VERSION "hnnbnnnynnnnnnnnnnnnnnnnnnnnnnnnnnnnnnnnnn/4/%%%/4/'%**4nnn///"

NS_ :

BS_:

BU_: BAP_Tester Fahrerdisplay_Kombi HUD ICAS1_X_Gateway ICAS3_Gateway ICC_IO_Node Kombi SmartLight_01 ZR_MIB_TOP_ab_Gen3

BO_ 512 Motor_53: 32 ICAS1_X_Gateway
	SG_ ISA_Tempolimit_Regelung : 196|6@1+ (1,0) [0|63] ""  ICAS3_Gateway
	SG_ MO_Antriebsstrang_Warnung_HS : 174|2@1+ (1,0) [0|3] ""  Vector__XXX
	SG_ MO_Anzeige_Betriebsmodus : 154|4@1+ (1,0) [0|15] ""  Vector__XXX
	SG_ MO_Anzeige_Fahrbereitschaft : 143|1@1+ (1,0) [0|1] ""  ICAS3_Gateway,Kombi
	SG_ MO_Anzeige_Rekuperation : 128|8@1+ (0.5,-0.5) [0|100] "PerCent"  Vector__XXX
	SG_ MO_Anzeige_Verbrauch_oE : 176|16@1+ (0.005,0) [0|327.675] "None"  Vector__XXX
	SG_ MO_Boost_aktiv : 153|1@1+ (1,0) [0|1] ""  Vector__XXX
	SG_ MO_Boost_verfuegbar : 144|8@1+ (0.4,-0.4) [0|100.4] "PerCent"  Vector__XXX
	SG_ MO_BZS_Charisma_FahrPr : 117|4@1+ (1,0) [0|15] ""  Vector__XXX
	SG_ MO_BZS_Charisma_Status : 121|2@1+ (1,0) [0|3] ""  Vector__XXX
	SG_ MO_Charisma_FahrPr : 105|4@1+ (1,0) [0|15] ""  Vector__XXX
	SG_ MO_Charisma_Status : 109|2@1+ (1,0) [0|3] ""  Vector__XXX
	SG_ MO_Drehzahlbeeinflussung : 80|8@1+ (0.39,0) [0|99.45] "PerCent"  Vector__XXX
	SG_ MO_Luftpfad_aktiv : 78|1@1+ (1,0) [0|1] ""  Vector__XXX
	SG_ MO_MAX_Wunschdrehzahl : 96|9@1+ (25,0) [0|12750] "MinutInver"  Vector__XXX
	SG_ MO_MIN_Wunschdrehzahl : 88|8@1+ (25,0) [0|6350] "MinutInver"  Vector__XXX
	SG_ MO_Motorlaufwarnung : 58|1@1+ (1,0) [0|1] ""  Vector__XXX
	SG_ MO_NGS_Position : 123|1@1+ (1,0) [0|1] ""  Vector__XXX
	SG_ MO_NGS_Status : 124|2@1+ (1,0) [0|3] ""  Vector__XXX
	SG_ MO_Overboost : 152|1@1+ (1,0) [0|1] ""  Vector__XXX
	SG_ MO_Prio_MAX_Wunschdrehzahl : 76|1@1+ (1,0) [0|1] ""  Vector__XXX
	SG_ MO_Prio_MIN_Wunschdrehzahl : 77|1@1+ (1,0) [0|1] ""  Vector__XXX
	SG_ MO_Rampenzeit_Generator_Anf : 72|4@1+ (1,0) [0|15] ""  Vector__XXX
	SG_ MO_Sperrung_FahrPr_BZS : 64|8@1+ (1,0) [0|255] ""  Vector__XXX
	SG_ MO_StSt_Charisma_FahrPr : 111|4@1+ (1,0) [0|15] ""  Vector__XXX
	SG_ MO_StSt_Charisma_Status : 115|2@1+ (1,0) [0|3] ""  Vector__XXX
	SG_ MO_Text_Aktivierung_Antrieb : 192|4@1+ (1,0) [0|15] ""  Kombi
	SG_ MO_v_Begrenz_Aktivierbar : 79|1@1+ (1,0) [0|1] ""  Vector__XXX
	SG_ MO_v_Begrenzung_Niveau : 126|2@1+ (1,0) [0|3] ""  Vector__XXX
	SG_ PEA_Abschalttexte : 166|2@1+ (1,0) [0|3] ""  Vector__XXX
	SG_ PEA_Ereignisanzeige : 160|5@1+ (1,0) [0|31] ""  Vector__XXX
	SG_ PEA_Ereignisanzeige_temporaer : 165|1@1+ (1,0) [0|1] ""  Vector__XXX
	SG_ PEA_Fahrerinfo : 202|4@1+ (1,0) [0|15] ""  Kombi
	SG_ PEA_Fortschrittsanzeige : 136|7@1+ (1,0) [0|100] "PerCent"  Vector__XXX
	SG_ PEA_Hinweis : 158|2@1+ (1,0) [0|3] ""  Vector__XXX
	SG_ PEA_Zielgeschw : 169|5@1+ (1,0) [0|31] ""  Vector__XXX
	SG_ PEA_Zielgeschw_Einheit : 168|1@1+ (1,0) [0|1] ""  Vector__XXX
	SG_ TSK_Akustik : 45|3@1+ (1,0) [0|7] ""  Kombi
	SG_ TSK_Fahrzeugstatus_GRA : 56|1@1+ (1,0) [0|1] ""  Kombi,ZR_MIB_TOP_ab_Gen3
	SG_ TSK_Fahrzeugstatus_Limiter : 57|1@1+ (1,0) [0|1] ""  Kombi,ZR_MIB_TOP_ab_Gen3
	SG_ TSK_Fahrzeugstatus_praed_Fkt : 31|3@1+ (1,0) [0|7] ""  Kombi,ZR_MIB_TOP_ab_Gen3
	SG_ TSK_Limiter_Anzeige : 55|1@1+ (1,0) [0|1] ""  Kombi,ZR_MIB_TOP_ab_Gen3
	SG_ TSK_Limiter_Fahrerinfo : 53|2@1+ (1,0) [0|3] ""  Kombi,ZR_MIB_TOP_ab_Gen3
	SG_ TSK_naechstes_Event : 25|6@1+ (1,0) [0|63] ""  Kombi,ZR_MIB_TOP_ab_Gen3
	SG_ TSK_naechstes_Event_Einheit : 60|1@1+ (1,0) [0|1] ""  Vector__XXX
	SG_ TSK_praed_Wunschgeschw : 246|10@1+ (0.32,0) [0|326.72] "KiloMeterPerHour"  Kombi,ZR_MIB_TOP_ab_Gen3
	SG_ TSK_praediktiver_Automode : 34|1@1+ (1,0) [0|1] ""  Vector__XXX
	SG_ TSK_praediktiver_Hinweis : 22|3@1+ (1,0) [0|7] ""  Kombi,ZR_MIB_TOP_ab_Gen3
	SG_ TSK_Status_Anzeige : 61|3@1+ (1,0) [0|7] ""  Kombi,ZR_MIB_TOP_ab_Gen3
	SG_ TSK_Texte : 40|5@1+ (1,0) [0|31] ""  Kombi
	SG_ TSK_Texte_Primaeranz : 48|5@1+ (1,0) [0|31] ""  Kombi,ZR_MIB_TOP_ab_Gen3
	SG_ TSK_Wunschgeschw : 12|10@1+ (0.32,0) [0|326.72] "KiloMeterPerHour"  Kombi,ZR_MIB_TOP_ab_Gen3

BO_ 332 Motor_54: 32 ICAS1_X_Gateway
	SG_ FoD_DTC_TSK_ACC : 35|1@1+ (1,0) [0|1] ""  Vector__XXX
	SG_ FoD_DTC_TSK_GRA : 15|1@1+ (1,0) [0|1] ""  Vector__XXX
	SG_ ISA_Regelung_aktiv : 27|1@1+ (1,0) [0|1] ""  ICAS3_Gateway,Kombi,ZR_MIB_TOP_ab_Gen3
	SG_ ISA_Status : 24|3@1+ (1,0) [0|7] ""  Kombi,ZR_MIB_TOP_ab_Gen3
	SG_ ISA_Tempolimitwarnung : 28|1@1+ (1,0) [0|1] ""  Kombi,ZR_MIB_TOP_ab_Gen3
	SG_ KVA_Ist_Pos : 121|7@1+ (1,0) [0|100] "PerCent"  Vector__XXX
	SG_ MO_Anforderung_Anzeige_Halten : 120|1@1+ (1,0) [0|1] ""  Vector__XXX
	SG_ MO_Anforderung_HMS : 12|3@1+ (1,0) [0|7] ""  Vector__XXX
	SG_ MO_EBoost_verf_praed : 90|2@1+ (1,0) [0|3] ""  Vector__XXX
	SG_ MO_eLaunch_verf : 93|2@1+ (1,0) [0|3] ""  Vector__XXX
	SG_ MO_Fahrbereitschaft : 76|2@1+ (1,0) [0|3] ""  Vector__XXX
	SG_ MO_Freilauf_Info : 78|2@1+ (1,0) [0|3] ""  Vector__XXX
	SG_ MO_Freilauf_Status : 87|3@1+ (1,0) [0|7] ""  Vector__XXX
	SG_ MO_Heckspoiler_Anf : 92|1@1+ (1,0) [0|1] ""  Vector__XXX
	SG_ MO_Klima_Regelmodus : 74|2@1+ (1,0) [0|3] ""  Vector__XXX
	SG_ MO_Krit_Heckobjekt : 81|3@1+ (1,0) [0|7] ""  Vector__XXX
	SG_ MO_LaunchControl : 101|1@1+ (1,0) [0|1] ""  Vector__XXX
	SG_ MO_NGS_Gangpos : 84|3@1+ (1,0) [0|7] ""  Vector__XXX
	SG_ MO_OnePedal_Verzoegerungsstufe : 117|3@1+ (1,0) [0|7] ""  Vector__XXX
	SG_ MO_Positionierung_aktiv : 95|1@1+ (1,0) [0|1] ""  Vector__XXX
	SG_ MO_QBit_Aussen_Temp : 185|1@1+ (1,0) [0|1] ""  Vector__XXX
	SG_ MO_Red_El_Fahrleistung : 29|3@1+ (1,0) [0|7] ""  Kombi
	SG_ MO_Servicemodus : 176|4@1+ (1,0) [0|15] ""  Vector__XXX
	SG_ MO_Startwunsch : 100|1@1+ (1,0) [0|1] ""  Vector__XXX
	SG_ MO_UBE_Reserve : 238|10@1+ (5,0) [0|5110] "WattHour"  Vector__XXX
	SG_ Motor_54_BZ : 8|4@1+ (1,0) [0|15] ""  Vector__XXX
	SG_ Motor_54_CRC : 0|8@1+ (1,0) [0|255] ""  Vector__XXX
	SG_ OBD_Abs_Load_Val : 152|16@1+ (0.392156862745,0) [0|25700] "PerCent"  Vector__XXX
	SG_ OBD_Abs_Pedal_Pos : 168|8@1+ (0.392156862745,0) [0|100] "PerCent"  Vector__XXX
	SG_ OBD_Abs_Throttle_Pos : 144|8@1+ (0.392156862745,0) [0|100] "PerCent"  Vector__XXX
	SG_ OBD_Aussen_Temp_gef : 248|8@1+ (1,-40) [-40|213] "DegreCelsi"  Vector__XXX
	SG_ OBD_Calc_Load_Val : 128|8@1+ (0.392156862745,0) [0|100] "PerCent"  Vector__XXX
	SG_ OBD_ClearMem_Inhibit : 183|1@1+ (1,0) [0|1] ""  Vector__XXX
	SG_ OBD_Driving_Cycle : 189|1@1+ (1,0) [0|1] ""  ICAS3_Gateway,ZR_MIB_TOP_ab_Gen3
	SG_ OBD_Eng_Cool_Temp : 136|8@1+ (1,-40) [-40|215] "DegreCelsi"  Vector__XXX
	SG_ OBD_Kaltstart_Denominator : 187|1@1+ (1,0) [0|1] ""  Vector__XXX
	SG_ OBD_Minimum_Trip : 188|1@1+ (1,0) [0|1] ""  Vector__XXX
	SG_ OBD_Normed_Trip : 191|1@1+ (1,0) [0|1] ""  Vector__XXX
	SG_ OBD_Sperrung_IUMPR : 186|1@1+ (1,0) [0|1] ""  Vector__XXX
	SG_ OBD_Sperrung_Kaltstart_Denom : 184|1@1+ (1,0) [0|1] ""  Vector__XXX
	SG_ OBD_Warm_Up_Cycle : 190|1@1+ (1,0) [0|1] ""  ICAS3_Gateway,ZR_MIB_TOP_ab_Gen3
	SG_ TSK_ACC_FoD_Status : 36|2@1+ (1,0) [0|3] ""  Vector__XXX
	SG_ TSK_aktives_System : 53|3@1+ (1,0) [0|7] ""  Vector__XXX
	SG_ TSK_Anf_Antriebsmoment : 57|1@1+ (1,0) [0|1] ""  Vector__XXX
	SG_ TSK_Einheit_vMax_Fahrerassistenz : 49|1@1+ (1,0) [0|1] ""  Vector__XXX
	SG_ TSK_erhoehter_Fahrwiderstand : 56|1@1+ (1,0) [0|1] ""  Vector__XXX
	SG_ TSK_GRA_FoD_Status : 38|2@1+ (1,0) [0|3] ""  ICAS3_Gateway
	SG_ TSK_Status_ARA : 58|3@1+ (1,0) [0|7] ""  Vector__XXX
	SG_ TSK_Status_EA : 32|3@1+ (1,0) [0|7] ""  Vector__XXX
	SG_ TSK_Status_IPA : 61|3@1+ (1,0) [0|7] ""  Vector__XXX
	SG_ TSK_Status_PLA : 50|3@1+ (1,0) [0|7] ""  Vector__XXX
	SG_ TSK_vMax_aktuell : 16|8@1+ (1,0) [0|253] "KiloMeterPerHour"  Kombi
	SG_ TSK_vMax_Fahrerassistenz : 40|9@1+ (1,0) [0|510] ""  Vector__XXX

BO_ 2463978666 Motor_57: 32 ICAS1_X_Gateway
	SG_ MO_Drehzahl_EM : 152|13@1+ (8,-32768) [-32768|32744] "RevPerMinute"  Vector__XXX
	SG_ MO_Drehzahl_EM_sek : 175|13@1+ (8,-32768) [-32768|32744] "RevPerMinute"  Vector__XXX
	SG_ MO_EM1_Generator_Leistung : 104|8@1+ (100,0) [0|25300] "Watt"  Vector__XXX
	SG_ MO_EM1_Max_Leistung_Gesamt : 45|13@1+ (200,-819000) [-819000|818800] "Watt"  Vector__XXX
	SG_ MO_EM1_Max_Spannung_Lim : 22|10@1+ (1,0) [0|1021] "Volt"  Vector__XXX
	SG_ MO_EM1_Min_Leistung_Gesamt : 32|13@1+ (200,-819000) [-819000|818800] "Watt"  Vector__XXX
	SG_ MO_EM1_Min_Spannung_Lim : 12|10@1+ (1,0) [0|1021] "Volt"  Vector__XXX
	SG_ MO_EM2_Generator_Leistung : 112|8@1+ (100,0) [0|25300] "Watt"  Vector__XXX
	SG_ MO_EM2_Max_Leistung_Gesamt : 71|13@1+ (200,-819000) [-819000|818800] "Watt"  Vector__XXX
	SG_ MO_EM2_Max_Spannung_Lim : 94|10@1+ (1,0) [0|1021] "Volt"  Vector__XXX
	SG_ MO_EM2_Min_Leistung_Gesamt : 58|13@1+ (200,-819000) [-819000|818800] "Watt"  Vector__XXX
	SG_ MO_EM2_Min_Spannung_Lim : 84|10@1+ (1,0) [0|1021] "Volt"  Vector__XXX
	SG_ MO_Rekuperation_EM_Ges_Ueberlauf : 151|1@1+ (1,0) [0|1] ""  Kombi
	SG_ MO_Rekuperation_Ges_EM : 136|15@1+ (10,0) [0|327670] "WattSecond"  Kombi
	SG_ MO_Uebersetzung_EM : 165|10@1+ (0.03125,0) [0.03125|31.90625] ""  Vector__XXX
	SG_ MO_Uebersetzung_EM_sek : 188|10@1+ (0.03125,0) [0.03125|31.90625] ""  Vector__XXX
	SG_ MO_Verbrauch_EM_Ges : 120|15@1+ (10,0) [0|327670] "WattSecond"  Kombi
	SG_ MO_Verbrauch_EM_Ges_Ueberlauf : 135|1@1+ (1,0) [0|1] ""  Kombi
	SG_ Motor_57_BZ : 8|4@1+ (1,0) [0|15] ""  Vector__XXX
	SG_ Motor_57_CRC : 0|8@1+ (1,0) [0|255] ""  Vector__XXX

BO_ 2331595982 Motor_64: 32 ICAS1_X_Gateway
	SG_ PTHyDrA_PrctUtilElDrv : 40|11@1+ (0.05,0) [0|102.25] "PerCent"  Vector__XXX
	SG_ PTHyDrA_StAcv : 36|2@1+ (1,0) [0|3] ""  Vector__XXX
	SG_ PTUIPwrm_FacPwrDyn : 73|7@1+ (0.01,0) [0|1.25] "None"  ICAS3_Gateway,Kombi
	SG_ PTUIPwrm_PrctBoostAvl : 91|10@1+ (0.1,0) [0|102.1] "PerCent"  Vector__XXX
	SG_ PTUIPwrm_PrctPeakPwrAvl : 131|11@1+ (0.05,0) [0|102.25] "PerCent"  ICAS3_Gateway
	SG_ PTUIPwrm_PrctPwrElBoostCur : 101|10@1+ (0.1,0) [0|102.1] "PerCent"  Vector__XXX
	SG_ PTUIPwrm_PrctPwrElBoostMaxUse : 111|10@1+ (0.1,0) [0|102.1] "PerCent"  Vector__XXX
	SG_ PTUIPwrm_PrctPwrElDrvCur : 24|12@1+ (0.05,-102.3) [-102.3|102.35] "PerCent"  Vector__XXX
	SG_ PTUIPwrm_PrctPwrGnrMaxUse : 51|11@1+ (0.05,-102.25) [-102.25|0] "PerCent"  ICAS3_Gateway,Kombi
	SG_ PTUIPwrm_PrctPwrMotElMaxUse : 62|11@1+ (0.05,0) [0|102.25] "PerCent"  Vector__XXX
	SG_ PTUIPwrm_PrctPwrMotMaxUse : 80|11@1+ (0.05,0) [0|102.25] "PerCent"  ICAS3_Gateway,Kombi
	SG_ PTUIPwrm_PrctPwrSysCur : 12|12@1+ (0.05,-102.3) [-102.3|102.35] "PerCent"  ICAS3_Gateway,Kombi
	SG_ PTUIPwrm_PwrElBoostNom : 121|10@1+ (1,0) [0|1021] "KiloWatt"  Vector__XXX
	SG_ PTUIPwrm_StAcv : 38|2@1+ (1,0) [0|3] ""  ICAS3_Gateway,Kombi

BO_ 2589283946 Motor_65: 32 ICAS1_X_Gateway
	SG_ PTUIPwrm_PwrGnrNom : 24|11@1+ (1,0) [0|2045] "KiloWatt"  ICAS3_Gateway,Kombi
	SG_ PTUIPwrm_PwrMotElNom : 12|11@1+ (1,0) [0|2045] "KiloWatt"  Vector__XXX
	SG_ PTUIPwrm_PwrSysMotNomDisp : 35|11@1+ (1,0) [0|2045] "KiloWatt"  ICAS3_Gateway,Kombi

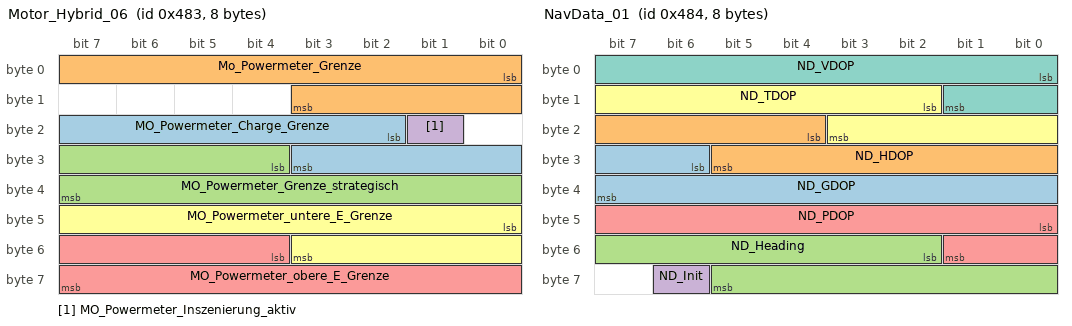
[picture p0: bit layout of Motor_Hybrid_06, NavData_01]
BO_ 1155 Motor_Hybrid_06: 8 ICAS1_X_Gateway
	SG_ MO_Powermeter_Charge_Grenze : 18|10@1+ (1,0) [0|1021] "None"  Kombi
	SG_ Mo_Powermeter_Grenze : 0|12@1+ (1,0) [0|4092] ""  Kombi
	SG_ MO_Powermeter_Grenze_strategisch : 28|12@1+ (1,0) [0|4093] "None"  Kombi
	SG_ MO_Powermeter_Inszenierung_aktiv : 17|1@1+ (1,0) [0|1] ""  Vector__XXX
	SG_ MO_Powermeter_obere_E_Grenze : 52|12@1+ (1,0) [0|4093] "None"  Vector__XXX
	SG_ MO_Powermeter_untere_E_Grenze : 40|12@1+ (1,0) [0|4093] "None"  Vector__XXX

BO_ 1156 NavData_01: 8 ZR_MIB_TOP_ab_Gen3
	SG_ ND_GDOP : 30|10@1+ (0.025,0) [0|25] ""  ICAS1_X_Gateway
	SG_ ND_HDOP : 20|10@1+ (0.025,0) [0|25] ""  ICAS1_X_Gateway
	SG_ ND_Heading : 50|12@1+ (0.1,0) [0|359.9] "DegreOfArc"  ICAS1_X_Gateway
	SG_ ND_Init : 62|1@1+ (1,0) [0|1] ""  ICAS1_X_Gateway
	SG_ ND_PDOP : 40|10@1+ (0.025,0) [0|25] ""  ICAS1_X_Gateway
	SG_ ND_TDOP : 10|10@1+ (0.025,0) [0|25] ""  ICAS1_X_Gateway
	SG_ ND_VDOP : 0|10@1+ (0.025,0) [0|25] ""  ICAS1_X_Gateway

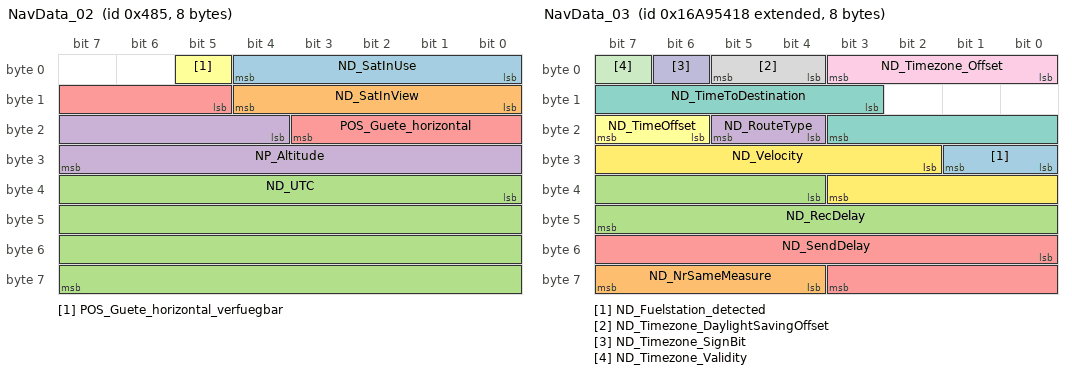
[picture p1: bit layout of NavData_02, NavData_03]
BO_ 1157 NavData_02: 8 ZR_MIB_TOP_ab_Gen3
	SG_ ND_SatInUse : 0|5@1+ (1,0) [0|29] ""  ICAS1_X_Gateway
	SG_ ND_SatInView : 8|5@1+ (1,0) [0|29] ""  ICAS1_X_Gateway
	SG_ ND_UTC : 32|32@1+ (1,0) [0|4294967293] "Secon"  ICAS1_X_Gateway
	SG_ NP_Altitude : 20|12@1+ (2,-500) [-500|7686] "Meter"  ICAS1_X_Gateway
	SG_ POS_Guete_horizontal : 13|7@1+ (2,0) [0|246] "Meter"  ICAS1_X_Gateway
	SG_ POS_Guete_horizontal_verfuegbar : 5|1@1+ (1,0) [0|1] ""  ICAS1_X_Gateway

BO_ 2527679512 NavData_03: 8 ZR_MIB_TOP_ab_Gen3
	SG_ ND_Fuelstation_detected : 24|2@1+ (1,0) [0|3] ""  Vector__XXX
	SG_ ND_NrSameMeasure : 60|4@1+ (1,0) [0|8] ""  Vector__XXX
	SG_ ND_RecDelay : 36|12@1+ (1,0) [0|4093] "MilliSecon"  Vector__XXX
	SG_ ND_RouteType : 20|2@1+ (1,0) [0|3] ""  Vector__XXX
	SG_ ND_SendDelay : 48|12@1+ (1,0) [0|4093] "MilliSecon"  Vector__XXX
	SG_ ND_TimeOffset : 22|2@1+ (1,0) [0|3] ""  Vector__XXX
	SG_ ND_TimeToDestination : 11|9@1+ (1,0) [0|509] "Minut"  Vector__XXX
	SG_ ND_Timezone_DaylightSavingOffset : 4|2@1+ (30,0) [0|60] "Minut"  Vector__XXX
	SG_ ND_Timezone_Offset : 0|4@1+ (1,0) [0|12] "Hours"  Vector__XXX
	SG_ ND_Timezone_SignBit : 6|1@1+ (1,0) [0|1] ""  Vector__XXX
	SG_ ND_Timezone_Validity : 7|1@1+ (1,0) [0|1] ""  Vector__XXX
	SG_ ND_Velocity : 26|10@1+ (0.1,0) [0|102.1] "MeterPerSecon"  Vector__XXX

BO_ 2527679665 NavData_04: 8 ICAS3_Gateway
	SG_ ND_Avrg_Speed_RangeData : 56|8@1+ (1,0) [0|253] "KiloMeterPerHour"  ICAS1_X_Gateway
	SG_ ND_PSD_Street_Category : 53|3@1+ (1,0) [0|7] ""  ICAS1_X_Gateway

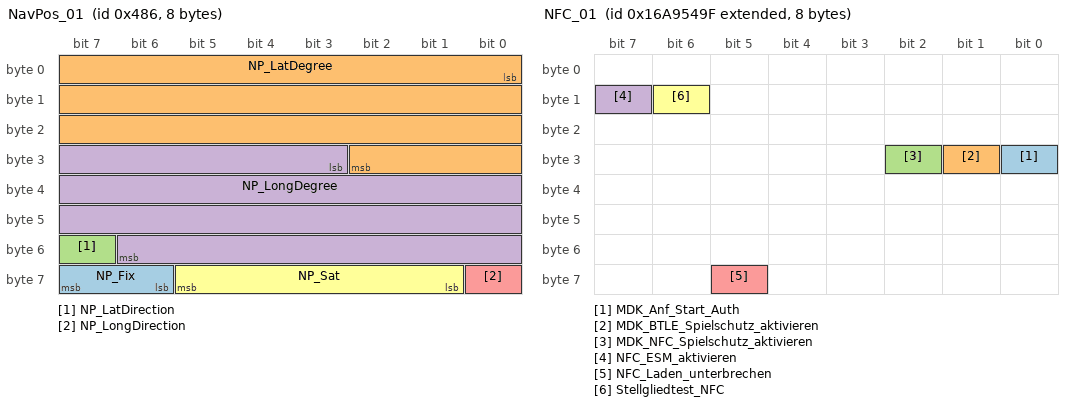
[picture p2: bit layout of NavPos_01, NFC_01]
BO_ 1158 NavPos_01: 8 ZR_MIB_TOP_ab_Gen3
	SG_ NP_Fix : 62|2@1+ (1,0) [0|3] ""  ICAS1_X_Gateway
	SG_ NP_LatDegree : 0|27@1+ (0.000001,0) [0|90] "DegreOfArc"  ICAS1_X_Gateway
	SG_ NP_LatDirection : 55|1@1+ (1,0) [0|1] ""  ICAS1_X_Gateway
	SG_ NP_LongDegree : 27|28@1+ (0.000001,0) [0|180] "DegreOfArc"  ICAS1_X_Gateway
	SG_ NP_LongDirection : 56|1@1+ (1,0) [0|1] ""  ICAS1_X_Gateway
	SG_ NP_Sat : 57|5@1+ (1,0) [0|29] ""  ICAS1_X_Gateway

BO_ 2589283496 NavPos_02_Map_Matched: 8 ZR_MIB_TOP_ab_Gen3
	SG_ POS_Heading m1 : 4|12@1+ (0.1,0) [0|409.5] "DegreOfArc"  ICAS1_X_Gateway
	SG_ POS_Heading_Trust m1 : 30|2@1+ (1,0) [0|3] ""  ICAS1_X_Gateway
	SG_ POS_Last_GPS_Sync m1 : 16|14@1+ (1,0) [0|16383] "Secon"  ICAS1_X_Gateway
	SG_ POS_LatDegree m0 : 8|27@1+ (0.000001,0) [0|90] "DegreOfArc"  ICAS1_X_Gateway
	SG_ POS_LatDirection m0 : 7|1@1+ (1,0) [0|1] ""  ICAS1_X_Gateway
	SG_ POS_LongDegree m0 : 36|28@1+ (0.000001,0) [0|180] "DegreOfArc"  ICAS1_X_Gateway
	SG_ POS_LongDirection m0 : 35|1@1+ (1,0) [0|1] ""  ICAS1_X_Gateway
	SG_ POS_MUX M : 0|2@1+ (1,0) [0|3] ""  ICAS1_X_Gateway
	SG_ POS_ODD_EVEN : 2|1@1+ (1,0) [0|1] ""  ICAS1_X_Gateway
	SG_ POS_PosStati m0 : 3|4@1+ (1,0) [0|15] ""  ICAS1_X_Gateway
	SG_ POS_UTC_REF m1 : 32|32@1+ (1,0) [0|4294967295] "Secon"  ICAS1_X_Gateway

BO_ 2527679647 NFC_01: 8 ICAS1_X_Gateway
	SG_ MDK_Anf_Start_Auth : 24|1@1+ (1,0) [0|1] ""  ICAS3_Gateway,ICC_IO_Node,ZR_MIB_TOP_ab_Gen3
	SG_ MDK_BTLE_Spielschutz_aktivieren : 25|1@1+ (1,0) [0|1] ""  ICAS3_Gateway,ICC_IO_Node,ZR_MIB_TOP_ab_Gen3
	SG_ MDK_NFC_Spielschutz_aktivieren : 26|1@1+ (1,0) [0|1] ""  ICAS3_Gateway,ICC_IO_Node,ZR_MIB_TOP_ab_Gen3
	SG_ NFC_ESM_aktivieren : 15|1@1+ (1,0) [0|1] ""  ICAS3_Gateway,ICC_IO_Node,ZR_MIB_TOP_ab_Gen3
	SG_ NFC_Laden_unterbrechen : 61|1@1+ (1,0) [0|1] ""  ICAS3_Gateway,ICC_IO_Node,ZR_MIB_TOP_ab_Gen3
	SG_ Stellgliedtest_NFC : 14|1@1+ (1,0) [0|1] ""  ICAS3_Gateway,ICC_IO_Node,ZR_MIB_TOP_ab_Gen3

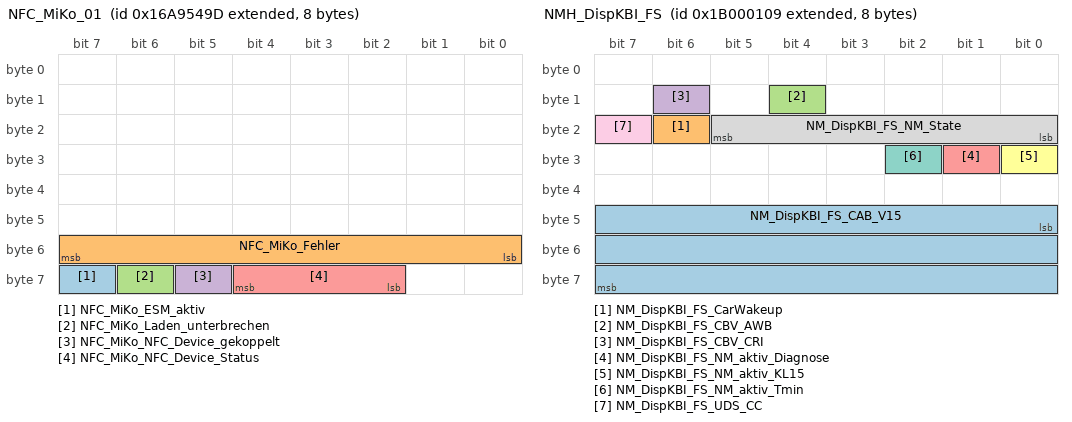
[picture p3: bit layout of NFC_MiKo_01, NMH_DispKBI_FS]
BO_ 2527679645 NFC_MiKo_01: 8 ICAS1_X_Gateway
	SG_ NFC_MiKo_ESM_aktiv : 63|1@1+ (1,0) [0|1] ""  ICAS3_Gateway,ICC_IO_Node,ZR_MIB_TOP_ab_Gen3
	SG_ NFC_MiKo_Fehler : 48|8@1+ (1,0) [0|255] ""  ICAS3_Gateway,ICC_IO_Node,ZR_MIB_TOP_ab_Gen3
	SG_ NFC_MiKo_Laden_unterbrechen : 62|1@1+ (1,0) [0|1] ""  ICAS3_Gateway,ICC_IO_Node,ZR_MIB_TOP_ab_Gen3
	SG_ NFC_MiKo_NFC_Device_gekoppelt : 61|1@1+ (1,0) [0|1] ""  ICAS3_Gateway,ICC_IO_Node,ZR_MIB_TOP_ab_Gen3
	SG_ NFC_MiKo_NFC_Device_Status : 58|3@1+ (1,0) [0|7] ""  ICAS3_Gateway,ICC_IO_Node,ZR_MIB_TOP_ab_Gen3

BO_ 2600468745 NMH_DispKBI_FS: 8 Fahrerdisplay_Kombi
	SG_ NM_DispKBI_FS_CAB_V15 : 40|24@1+ (1,0) [0|16777215] ""  ICAS1_X_Gateway
	SG_ NM_DispKBI_FS_CarWakeup : 22|1@1+ (1,0) [0|1] ""  ICAS1_X_Gateway
	SG_ NM_DispKBI_FS_CBV_AWB : 12|1@1+ (1,0) [0|1] ""  ICAS1_X_Gateway
	SG_ NM_DispKBI_FS_CBV_CRI : 14|1@1+ (1,0) [0|1] ""  ICAS1_X_Gateway
	SG_ NM_DispKBI_FS_NM_aktiv_Diagnose : 25|1@1+ (1,0) [0|1] ""  Vector__XXX
	SG_ NM_DispKBI_FS_NM_aktiv_KL15 : 24|1@1+ (1,0) [0|1] ""  Vector__XXX
	SG_ NM_DispKBI_FS_NM_aktiv_Tmin : 26|1@1+ (1,0) [0|1] ""  Vector__XXX
	SG_ NM_DispKBI_FS_NM_State : 16|6@1+ (1,0) [0|63] ""  HUD,ICAS3_Gateway,ICC_IO_Node,Kombi,SmartLight_01,ZR_MIB_TOP_ab_Gen3
	SG_ NM_DispKBI_FS_UDS_CC : 23|1@1+ (1,0) [0|1] ""  Vector__XXX

BO_ 2600468496 NMH_Gateway: 8 ICAS1_X_Gateway
	SG_ NM_Gateway_CAB_V15 : 40|24@1+ (1,0) [0|16777215] ""  Vector__XXX
	SG_ NM_Gateway_Car_Wakeup : 22|1@1+ (1,0) [0|1] ""  ICAS3_Gateway,ZR_MIB_TOP_ab_Gen3
	SG_ NM_Gateway_CBV_AWB : 12|1@1+ (1,0) [0|1] ""  Vector__XXX
	SG_ NM_Gateway_CBV_CRI : 14|1@1+ (1,0) [0|1] ""  Vector__XXX
	SG_ NM_Gateway_NM_aktiv_CAB : 32|1@1+ (1,0) [0|1] ""  Vector__XXX
	SG_ NM_Gateway_NM_aktiv_Diagnose : 25|1@1+ (1,0) [0|1] ""  Vector__XXX
	SG_ NM_Gateway_NM_aktiv_Energie : 28|1@1+ (1,0) [0|1] ""  Vector__XXX
	SG_ NM_Gateway_NM_aktiv_FoD : 39|1@1+ (1,0) [0|1] ""  Vector__XXX
	SG_ NM_Gateway_NM_aktiv_IAA_PSO : 31|1@1+ (1,0) [0|1] ""  Vector__XXX
	SG_ NM_Gateway_NM_aktiv_Kessy : 27|1@1+ (1,0) [0|1] ""  Vector__XXX
	SG_ NM_Gateway_NM_aktiv_KL15 : 24|1@1+ (1,0) [0|1] ""  Vector__XXX
	SG_ NM_Gateway_NM_aktiv_KS : 33|1@1+ (1,0) [0|1] ""  Vector__XXX
	SG_ NM_Gateway_NM_aktiv_Licht : 29|1@1+ (1,0) [0|1] ""  Vector__XXX
	SG_ NM_Gateway_NM_aktiv_PaCo : 34|1@1+ (1,0) [0|1] ""  Vector__XXX
	SG_ NM_Gateway_NM_aktiv_RTM : 37|1@1+ (1,0) [0|1] ""  Vector__XXX
	SG_ NM_Gateway_NM_aktiv_Standklima : 35|1@1+ (1,0) [0|1] ""  Vector__XXX
	SG_ NM_Gateway_NM_aktiv_Tmin : 26|1@1+ (1,0) [0|1] ""  Vector__XXX
	SG_ NM_Gateway_NM_aktiv_USS : 30|1@1+ (1,0) [0|1] ""  Vector__XXX
	SG_ NM_Gateway_NM_aktiv_ZM : 38|1@1+ (1,0) [0|1] ""  Vector__XXX
	SG_ NM_Gateway_NM_aktiv_ZV : 36|1@1+ (1,0) [0|1] ""  Vector__XXX
	SG_ NM_Gateway_NM_State : 16|6@1+ (1,0) [0|63] ""  Fahrerdisplay_Kombi,HUD,ICAS3_Gateway,ICC_IO_Node,Kombi,SmartLight_01,ZR_MIB_TOP_ab_Gen3
	SG_ NM_Gateway_UDS_CC : 23|1@1+ (1,0) [0|1] ""  Vector__XXX

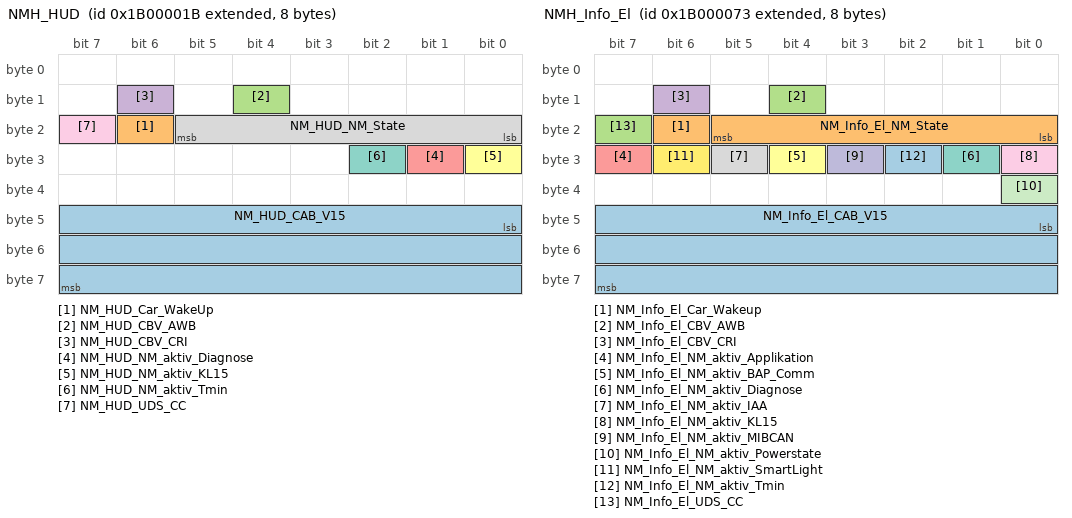
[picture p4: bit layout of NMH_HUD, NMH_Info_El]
BO_ 2600468507 NMH_HUD: 8 HUD
	SG_ NM_HUD_CAB_V15 : 40|24@1+ (1,0) [0|16777215] ""  ICAS1_X_Gateway
	SG_ NM_HUD_Car_WakeUp : 22|1@1+ (1,0) [0|1] ""  ICAS1_X_Gateway
	SG_ NM_HUD_CBV_AWB : 12|1@1+ (1,0) [0|1] ""  ICAS1_X_Gateway
	SG_ NM_HUD_CBV_CRI : 14|1@1+ (1,0) [0|1] ""  ICAS1_X_Gateway
	SG_ NM_HUD_NM_aktiv_Diagnose : 25|1@1+ (1,0) [0|1] ""  Vector__XXX
	SG_ NM_HUD_NM_aktiv_KL15 : 24|1@1+ (1,0) [0|1] ""  Vector__XXX
	SG_ NM_HUD_NM_aktiv_Tmin : 26|1@1+ (1,0) [0|1] ""  Vector__XXX
	SG_ NM_HUD_NM_State : 16|6@1+ (1,0) [0|63] ""  Fahrerdisplay_Kombi,ICAS3_Gateway,ICC_IO_Node,Kombi,SmartLight_01,ZR_MIB_TOP_ab_Gen3
	SG_ NM_HUD_UDS_CC : 23|1@1+ (1,0) [0|1] ""  Vector__XXX

BO_ 2600468595 NMH_Info_El: 8 ICAS3_Gateway
	SG_ NM_Info_El_CAB_V15 : 40|24@1+ (1,0) [0|16777215] ""  ICAS1_X_Gateway
	SG_ NM_Info_El_Car_Wakeup : 22|1@1+ (1,0) [0|1] ""  ICAS1_X_Gateway
	SG_ NM_Info_El_CBV_AWB : 12|1@1+ (1,0) [0|1] ""  ICAS1_X_Gateway
	SG_ NM_Info_El_CBV_CRI : 14|1@1+ (1,0) [0|1] ""  ICAS1_X_Gateway
	SG_ NM_Info_El_NM_aktiv_Applikation : 31|1@1+ (1,0) [0|1] ""  Vector__XXX
	SG_ NM_Info_El_NM_aktiv_BAP_Comm : 28|1@1+ (1,0) [0|1] ""  Vector__XXX
	SG_ NM_Info_El_NM_aktiv_Diagnose : 25|1@1+ (1,0) [0|1] ""  Vector__XXX
	SG_ NM_Info_El_NM_aktiv_IAA : 29|1@1+ (1,0) [0|1] ""  Vector__XXX
	SG_ NM_Info_El_NM_aktiv_KL15 : 24|1@1+ (1,0) [0|1] ""  Vector__XXX
	SG_ NM_Info_El_NM_aktiv_MIBCAN : 27|1@1+ (1,0) [0|1] ""  Vector__XXX
	SG_ NM_Info_El_NM_aktiv_Powerstate : 32|1@1+ (1,0) [0|1] ""  Vector__XXX
	SG_ NM_Info_El_NM_aktiv_SmartLight : 30|1@1+ (1,0) [0|1] ""  Vector__XXX
	SG_ NM_Info_El_NM_aktiv_Tmin : 26|1@1+ (1,0) [0|1] ""  Vector__XXX
	SG_ NM_Info_El_NM_State : 16|6@1+ (1,0) [0|63] ""  Fahrerdisplay_Kombi,HUD,Kombi,SmartLight_01
	SG_ NM_Info_El_UDS_CC : 23|1@1+ (1,0) [0|1] ""  Vector__XXX

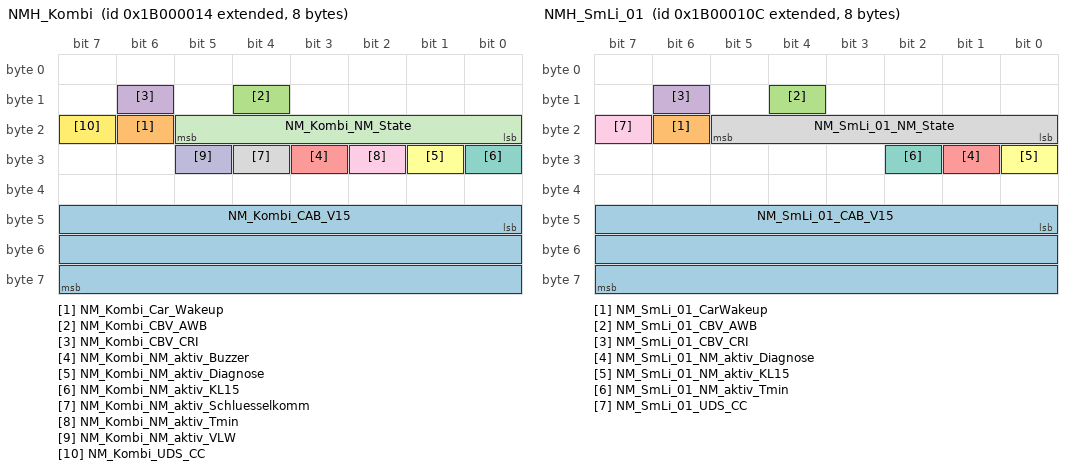
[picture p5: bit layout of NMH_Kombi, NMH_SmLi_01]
BO_ 2600468500 NMH_Kombi: 8 Kombi
	SG_ NM_Kombi_CAB_V15 : 40|24@1+ (1,0) [0|16777215] ""  ICAS1_X_Gateway
	SG_ NM_Kombi_Car_Wakeup : 22|1@1+ (1,0) [0|1] ""  ICAS1_X_Gateway
	SG_ NM_Kombi_CBV_AWB : 12|1@1+ (1,0) [0|1] ""  ICAS1_X_Gateway
	SG_ NM_Kombi_CBV_CRI : 14|1@1+ (1,0) [0|1] ""  ICAS1_X_Gateway
	SG_ NM_Kombi_NM_aktiv_Buzzer : 27|1@1+ (1,0) [0|1] ""  Vector__XXX
	SG_ NM_Kombi_NM_aktiv_Diagnose : 25|1@1+ (1,0) [0|1] ""  Vector__XXX
	SG_ NM_Kombi_NM_aktiv_KL15 : 24|1@1+ (1,0) [0|1] ""  Vector__XXX
	SG_ NM_Kombi_NM_aktiv_Schluesselkomm : 28|1@1+ (1,0) [0|1] ""  Vector__XXX
	SG_ NM_Kombi_NM_aktiv_Tmin : 26|1@1+ (1,0) [0|1] ""  Vector__XXX
	SG_ NM_Kombi_NM_aktiv_VLW : 29|1@1+ (1,0) [0|1] ""  Vector__XXX
	SG_ NM_Kombi_NM_State : 16|6@1+ (1,0) [0|63] ""  Fahrerdisplay_Kombi,HUD,ICAS3_Gateway,ICC_IO_Node,SmartLight_01,ZR_MIB_TOP_ab_Gen3
	SG_ NM_Kombi_UDS_CC : 23|1@1+ (1,0) [0|1] ""  Vector__XXX

BO_ 2600468748 NMH_SmLi_01: 8 SmartLight_01
	SG_ NM_SmLi_01_CAB_V15 : 40|24@1+ (1,0) [0|16777215] ""  ICAS1_X_Gateway
	SG_ NM_SmLi_01_CarWakeup : 22|1@1+ (1,0) [0|1] ""  ICAS1_X_Gateway
	SG_ NM_SmLi_01_CBV_AWB : 12|1@1+ (1,0) [0|1] ""  ICAS1_X_Gateway
	SG_ NM_SmLi_01_CBV_CRI : 14|1@1+ (1,0) [0|1] ""  ICAS1_X_Gateway
	SG_ NM_SmLi_01_NM_aktiv_Diagnose : 25|1@1+ (1,0) [0|1] ""  Vector__XXX
	SG_ NM_SmLi_01_NM_aktiv_KL15 : 24|1@1+ (1,0) [0|1] ""  Vector__XXX
	SG_ NM_SmLi_01_NM_aktiv_Tmin : 26|1@1+ (1,0) [0|1] ""  Vector__XXX
	SG_ NM_SmLi_01_NM_State : 16|6@1+ (1,0) [0|63] ""  Fahrerdisplay_Kombi,HUD,ICAS3_Gateway,ICC_IO_Node,Kombi,ZR_MIB_TOP_ab_Gen3
	SG_ NM_SmLi_01_UDS_CC : 23|1@1+ (1,0) [0|1] ""  Vector__XXX

BO_ 2621702665 OBDC_DispKBI_FS_Req_FD: 64 ICAS1_X_Gateway
	SG_ OBDC_DispKBI_FS_Req_FD_Data : 0|512@1+ (1,0) [0|13407807929942597099574024998205846127479365820592393377723561443721764030073546976801874298166903427690031858186486050853753882811946569946433649006084096] ""  Fahrerdisplay_Kombi

BO_ 2621833737 OBDC_DispKBI_FS_Resp_FD: 64 Fahrerdisplay_Kombi
	SG_ OBDC_DispKBI_FS_Resp_FD_Data : 0|512@1+ (1,0) [0|13407807929942597099574024998205846127479365820592393377723561443721764030073546976801874298166903427690031858186486050853753882811946569946433649006084096] ""  ICAS1_X_Gateway

BO_ 2549940736 OBDC_Funktionaler_Req_All: 8 ICAS1_X_Gateway
	SG_ OBDC_Funktionaler_Req_All_Data : 0|64@1+ (1,0) [0|18446744073709551616] ""  ICAS3_Gateway,ICC_IO_Node,ZR_MIB_TOP_ab_Gen3

BO_ 2621506048 OBDC_Funktionaler_Req_All_FD: 64 ICAS1_X_Gateway
	SG_ OBDC_Funktion_Req_All_FD_Data : 0|512@1+ (1,0) [0|13407807929942597099574024998205846127479365820592393377723561443721764030073546976801874298166903427690031858186486050853753882811946569946433649006084096] ""  Fahrerdisplay_Kombi,HUD,Kombi,SmartLight_01

BO_ 2621440539 OBDC_HUD_Req_FD: 64 ICAS1_X_Gateway
	SG_ OBDC_HUD_Req_FD_Data : 0|512@1+ (1,0) [0|13407807929942597099574024998205846127479365820592393377723561443721764030073546976801874298166903427690031858186486050853753882811946569946433649006084096] ""  HUD

BO_ 2621571611 OBDC_HUD_Resp_FD: 64 HUD
	SG_ OBDC_HUD_Resp_FD_Data : 0|512@1+ (1,0) [0|13407807929942597099574024998205846127479365820592393377723561443721764030073546976801874298166903427690031858186486050853753882811946569946433649006084096] ""  ICAS1_X_Gateway

BO_ 2621440532 OBDC_Kombi_Req_FD: 64 ICAS1_X_Gateway
	SG_ OBDC_Kombi_Req_FD_Data : 0|512@1+ (1,0) [0|13407807929942597099574024998205846127479365820592393377723561443721764030073546976801874298166903427690031858186486050853753882811946569946433649006084096] ""  Kombi

BO_ 2621571604 OBDC_Kombi_Resp_FD: 64 Kombi
	SG_ OBDC_Kombi_Resp_FD_Data : 0|512@1+ (1,0) [0|13407807929942597099574024998205846127479365820592393377723561443721764030073546976801874298166903427690031858186486050853753882811946569946433649006084096] ""  ICAS1_X_Gateway

BO_ 2621702668 OBDC_SmLi_01_Req_FD: 64 ICAS1_X_Gateway
	SG_ OBDC_SmLi_01_Req_FD_Data : 0|512@1+ (1,0) [0|13407807929942597099574024998205846127479365820592393377723561443721764030073546976801874298166903427690031858186486050853753882811946569946433649006084096] ""  SmartLight_01

BO_ 2621833740 OBDC_SmLi_01_Resp_FD: 64 SmartLight_01
	SG_ OBDC_SmLi_01_Resp_FD_Data : 0|512@1+ (1,0) [0|13407807929942597099574024998205846127479365820592393377723561443721764030073546976801874298166903427690031858186486050853753882811946569946433649006084096] ""  ICAS1_X_Gateway

BO_ 2549903374 OBDC_SSN_ABT_1_Req: 8 ICAS1_X_Gateway
	SG_ OBDC_SSN_ABT_1_Req_Data : 0|64@1+ (1,0) [0|18446744073709551616] ""  ICAS3_Gateway,ICC_IO_Node,ZR_MIB_TOP_ab_Gen3

BO_ 2550034446 OBDC_SSN_ABT_1_Resp: 8 ICAS3_Gateway
	SG_ OBDC_SSN_ABT_1_Resp_Data : 0|64@1+ (1,0) [0|18446744073709551616] ""  ICAS1_X_Gateway

BO_ 2549875309 OBDC_TV_Tuner_Req: 8 ICAS1_X_Gateway
	SG_ OBDC_TV_Tuner_Req_Data : 0|64@1+ (1,0) [0|18446744073709551616] ""  ZR_MIB_TOP_ab_Gen3

BO_ 2550006381 OBDC_TV_Tuner_Resp: 8 ZR_MIB_TOP_ab_Gen3
	SG_ OBDC_TV_Tuner_Resp_Data : 0|64@1+ (1,0) [0|18446744073709551616] ""  ICAS1_X_Gateway

BO_ 2549875365 OBDC_WLC1_Req: 8 ICAS1_X_Gateway
	SG_ OBDC_WLC1_Req_Data : 0|64@1+ (1,0) [0|18446744073709551616] "None"  ICAS3_Gateway,ICC_IO_Node,ZR_MIB_TOP_ab_Gen3

BO_ 2550006437 OBDC_WLC1_Resp: 8 ICAS3_Gateway
	SG_ OBDC_WLC1_Resp_Data : 0|64@1+ (1,0) [0|18446744073709551616] "None"  ICAS1_X_Gateway

BO_ 2564502513 OBDx_allOBD_Req: 8 ICAS1_X_Gateway
	SG_ OBDx_allOBD_Req_Data : 0|64@1+ (1,0) [0|18446744073709551616] ""  Vector__XXX

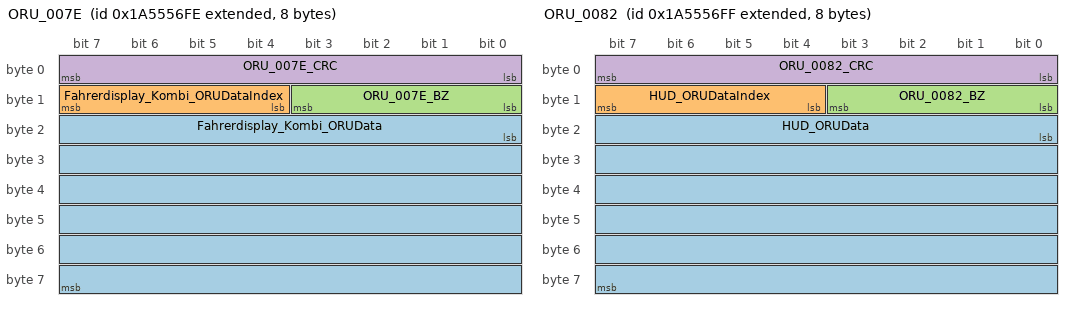
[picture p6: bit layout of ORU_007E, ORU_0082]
BO_ 2589284094 ORU_007E: 8 Fahrerdisplay_Kombi
	SG_ Fahrerdisplay_Kombi_ORUData : 16|48@1+ (1,0) [0|281474976710655] ""  ICAS1_X_Gateway
	SG_ Fahrerdisplay_Kombi_ORUDataIndex : 12|4@1+ (1,0) [0|15] ""  ICAS1_X_Gateway
	SG_ ORU_007E_BZ : 8|4@1+ (1,0) [0|15] ""  ICAS1_X_Gateway
	SG_ ORU_007E_CRC : 0|8@1+ (1,0) [0|255] ""  ICAS1_X_Gateway

BO_ 2589284095 ORU_0082: 8 HUD
	SG_ HUD_ORUData : 16|48@1+ (1,0) [0|281474976710655] ""  ICAS1_X_Gateway
	SG_ HUD_ORUDataIndex : 12|4@1+ (1,0) [0|15] ""  ICAS1_X_Gateway
	SG_ ORU_0082_BZ : 8|4@1+ (1,0) [0|15] ""  ICAS1_X_Gateway
	SG_ ORU_0082_CRC : 0|8@1+ (1,0) [0|255] ""  ICAS1_X_Gateway

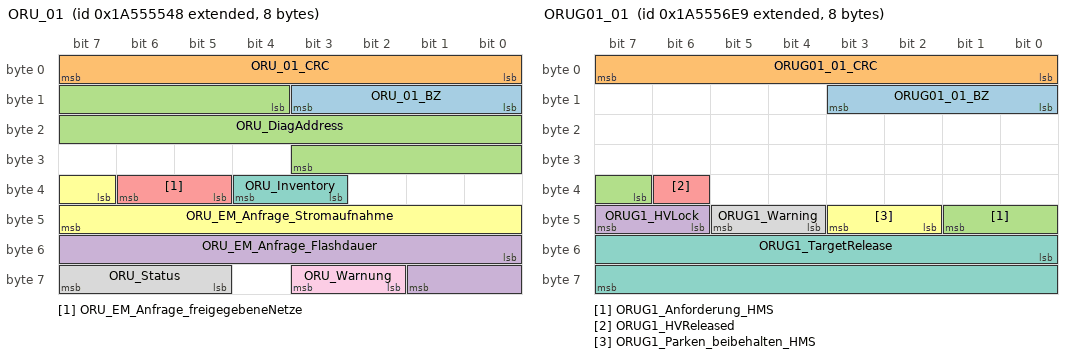
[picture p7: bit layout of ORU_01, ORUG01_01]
BO_ 2589283656 ORU_01: 8 ICAS1_X_Gateway
	SG_ ORU_01_BZ : 8|4@1+ (1,0) [0|15] ""  ICAS3_Gateway,ICC_IO_Node,ZR_MIB_TOP_ab_Gen3
	SG_ ORU_01_CRC : 0|8@1+ (1,0) [0|255] ""  ICAS3_Gateway,ICC_IO_Node,ZR_MIB_TOP_ab_Gen3
	SG_ ORU_DiagAddress : 12|16@1+ (1,0) [0|65535] ""  ICAS3_Gateway,ICC_IO_Node,ZR_MIB_TOP_ab_Gen3
	SG_ ORU_EM_Anfrage_Flashdauer : 48|10@1+ (10,0) [0|10230] "Secon"  ICAS3_Gateway,ICC_IO_Node,ZR_MIB_TOP_ab_Gen3
	SG_ ORU_EM_Anfrage_freigegebeneNetze : 37|2@1+ (1,0) [0|3] ""  ICAS3_Gateway,ICC_IO_Node,ZR_MIB_TOP_ab_Gen3
	SG_ ORU_EM_Anfrage_Stromaufnahme : 39|9@1+ (0.1,0) [0|51.1] "Amper"  ICAS3_Gateway,ICC_IO_Node,ZR_MIB_TOP_ab_Gen3
	SG_ ORU_Inventory : 35|2@1+ (1,0) [0|3] ""  ICAS3_Gateway,ICC_IO_Node,ZR_MIB_TOP_ab_Gen3
	SG_ ORU_Status : 61|3@1+ (1,0) [0|7] ""  Fahrerdisplay_Kombi,HUD,ICAS3_Gateway,ICC_IO_Node,SmartLight_01,ZR_MIB_TOP_ab_Gen3
	SG_ ORU_Warnung : 58|2@1+ (1,0) [0|3] ""  Fahrerdisplay_Kombi,ICAS3_Gateway,ICC_IO_Node,Kombi,ZR_MIB_TOP_ab_Gen3

BO_ 2589283672 ORU_01_SOK_Signatur: 8 ICAS1_X_Gateway
	SG_ SOK_ORU_01_Signatur : 0|64@1+ (1,0) [0|18446744073709551616] ""  ICAS3_Gateway

BO_ 2589284073 ORUG01_01: 8 ICAS1_X_Gateway
	SG_ ORUG01_01_BZ : 8|4@1+ (1,0) [0|15] ""  Fahrerdisplay_Kombi,HUD
	SG_ ORUG01_01_CRC : 0|8@1+ (1,0) [0|255] ""  Fahrerdisplay_Kombi,HUD
	SG_ ORUG1_Anforderung_HMS : 39|3@1+ (1,0) [0|7] ""  Vector__XXX
	SG_ ORUG1_HVLock : 46|2@1+ (1,0) [0|3] ""  Vector__XXX
	SG_ ORUG1_HVReleased : 38|1@1+ (1,0) [0|1] ""  Vector__XXX
	SG_ ORUG1_Parken_beibehalten_HMS : 42|2@1+ (1,0) [0|3] ""  Vector__XXX
	SG_ ORUG1_TargetRelease : 48|16@1+ (1,0) [0|65535] ""  Fahrerdisplay_Kombi,HUD
	SG_ ORUG1_Warning : 44|2@1+ (1,0) [0|3] ""  Fahrerdisplay_Kombi

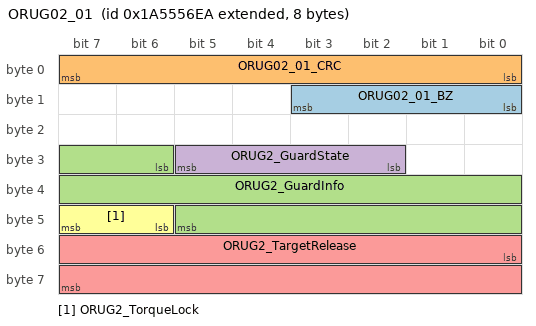
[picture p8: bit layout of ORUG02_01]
BO_ 2589284074 ORUG02_01: 8 ICAS1_X_Gateway
	SG_ ORUG02_01_BZ : 8|4@1+ (1,0) [0|15] ""  Fahrerdisplay_Kombi,HUD
	SG_ ORUG02_01_CRC : 0|8@1+ (1,0) [0|255] ""  Fahrerdisplay_Kombi,HUD
	SG_ ORUG2_GuardInfo : 30|16@1+ (1,0) [0|65535] ""  Vector__XXX
	SG_ ORUG2_GuardState : 26|4@1+ (1,0) [0|15] ""  Vector__XXX
	SG_ ORUG2_TargetRelease : 48|16@1+ (1,0) [0|65535] ""  Fahrerdisplay_Kombi,HUD
	SG_ ORUG2_TorqueLock : 46|2@1+ (1,0) [0|3] ""  Vector__XXX

BO_TX_BU_ 512 :ICAS1_X_Gateway;
BO_TX_BU_ 332 :ICAS1_X_Gateway;
BO_TX_BU_ 2463978666 :ICAS1_X_Gateway;
BO_TX_BU_ 2331595982 :ICAS1_X_Gateway;
BO_TX_BU_ 2589283946 :ICAS1_X_Gateway;
BO_TX_BU_ 1155 :ICAS1_X_Gateway;
BO_TX_BU_ 1156 :ZR_MIB_TOP_ab_Gen3;
BO_TX_BU_ 1157 :ZR_MIB_TOP_ab_Gen3;
BO_TX_BU_ 2527679512 :ZR_MIB_TOP_ab_Gen3;
BO_TX_BU_ 2527679665 :ICAS3_Gateway,ZR_MIB_TOP_ab_Gen3;
BO_TX_BU_ 1158 :ZR_MIB_TOP_ab_Gen3;
BO_TX_BU_ 2589283496 :ZR_MIB_TOP_ab_Gen3;
BO_TX_BU_ 2527679647 :ICAS1_X_Gateway;
BO_TX_BU_ 2527679645 :ICAS1_X_Gateway;
BO_TX_BU_ 2600468745 :Fahrerdisplay_Kombi;
BO_TX_BU_ 2600468496 :ICAS1_X_Gateway;
BO_TX_BU_ 2600468507 :HUD;
BO_TX_BU_ 2600468595 :ICAS3_Gateway,ICC_IO_Node,ZR_MIB_TOP_ab_Gen3;
BO_TX_BU_ 2600468500 :Kombi;
BO_TX_BU_ 2600468748 :SmartLight_01;
BO_TX_BU_ 2621702665 :ICAS1_X_Gateway;
BO_TX_BU_ 2621833737 :Fahrerdisplay_Kombi;
BO_TX_BU_ 2549940736 :ICAS1_X_Gateway;
BO_TX_BU_ 2621506048 :ICAS1_X_Gateway;
BO_TX_BU_ 2621440539 :ICAS1_X_Gateway;
BO_TX_BU_ 2621571611 :HUD;
BO_TX_BU_ 2621440532 :ICAS1_X_Gateway;
BO_TX_BU_ 2621571604 :Kombi;
BO_TX_BU_ 2621702668 :ICAS1_X_Gateway;
BO_TX_BU_ 2621833740 :SmartLight_01;
BO_TX_BU_ 2549903374 :ICAS1_X_Gateway;
BO_TX_BU_ 2550034446 :ICAS3_Gateway,ICC_IO_Node,ZR_MIB_TOP_ab_Gen3;
BO_TX_BU_ 2549875309 :ICAS1_X_Gateway;
BO_TX_BU_ 2550006381 :ZR_MIB_TOP_ab_Gen3;
BO_TX_BU_ 2549875365 :ICAS1_X_Gateway;
BO_TX_BU_ 2550006437 :ICAS3_Gateway,ICC_IO_Node,ZR_MIB_TOP_ab_Gen3;
BO_TX_BU_ 2564502513 :ICAS1_X_Gateway;
BO_TX_BU_ 2589284094 :Fahrerdisplay_Kombi;
BO_TX_BU_ 2589284095 :HUD;
BO_TX_BU_ 2589283656 :ICAS1_X_Gateway;
BO_TX_BU_ 2589283672 :ICAS1_X_Gateway;
BO_TX_BU_ 2589284073 :ICAS1_X_Gateway;
BO_TX_BU_ 2589284074 :ICAS1_X_Gateway;
CM_ BO_ 2600468507 "CAN_NM_PDU MLBevo";
CM_ BO_ 2549940736 "VDC funktionaler Request auf CANHS";
CM_ BO_ 2621506048 "VDC funktionaler Request auf CANFD";
CM_ SG_ 512 ISA_Tempolimit_Regelung "Anzeige des expliziten Tempolimits zur Regelgrundanzeige";
CM_ SG_ 512 MO_Antriebsstrang_Warnung_HS "Status der Fehlerlampen-Ansteuerung und Textausgabe fï?½r Fehlerspeichereintrï?½ge aus der Kupplungsschutz-Funktion fï?½r Handschaltgetriebe.";
CM_ SG_ 512 MO_Anzeige_Betriebsmodus "Info an das Kombi zur Anzeige verschiedener Betriebsmodi";
CM_ SG_ 512 MO_Anzeige_Fahrbereitschaft "Signalisiert dauerhaft an das Kombi, ob die Fahrbereitschaft vorhanden ist (Drehzahlmesser auf READY)";
CM_ SG_ 512 MO_Anzeige_Rekuperation "Signal steht im Kontext zu MO_Anzeige_Verbrauch und wird fï?½r die Anzeige des Reku-Bereiches im grafischen Momentanverbrauch verwendet";
CM_ SG_ 512 MO_Anzeige_Verbrauch_oE "Anzeige Verbrauchssignal fï?½rs Kombi. Im Bezug auf Verbrennerbeteiligung. Das Signal ist einheitenlos. Die zugehï?½rige Einheit wird in MO_Anzeige_Verbr_Einheit ï?½bertragen.";
CM_ SG_ 512 MO_Boost_aktiv "Anzeige im Kombi ob Boost aktiv ist.\nDie Anzeige wird zusï?½tzlich ï?½ber das Signal MO_Boost_verfuegbar gesteuert.\n";
CM_ SG_ 512 MO_Boost_verfuegbar "Anzeige des aktuell verfï?½gbaren Boostpotentials im Kombiinstrument.";
CM_ SG_ 512 MO_BZS_Charisma_FahrPr "Rï?½ckmeldung des aktuellen Charisma-Fahrprogramms der MSG Betriebsstrategie\n\nMLBevo: Aktuelles Fahrprogramm des Charisma-Teilnehmers (siehe Systemlastenheft Drive Select)\nMQB: Istwert der Kennlinie (siehe Systemlastenheft MQB FPA)";
CM_ SG_ 512 MO_BZS_Charisma_Status "Charisma Systemstatus des Charisma-Teilnehmers MSG (Betriebszustï?½nde)\n\nWert 0x3 ist nur fï?½r Fahrzeuge ab MQB relevant";
CM_ SG_ 512 MO_Charisma_FahrPr "MLBevo: Aktuelles Fahrprogramm des Charisma-Teilnehmers (siehe Systemlastenheft Drive Select)\nMQB: Istwert der Kennlinie (siehe Systemlastenheft MQB FPA)";
CM_ SG_ 512 MO_Charisma_Status "Charisma Systemstatus des Charisma-Teilnehmers\n\nWert 0x3 ist nur fï?½r Fahrzeuge ab MQB relevant";
CM_ SG_ 512 MO_Drehzahlbeeinflussung "Faktor zur Anhebung der Fahrdrehzahl im Warmlauf";
CM_ SG_ 512 MO_Luftpfad_aktiv "Getriebeeingriff wird zusï?½tzlich zum Zï?½ndungspfad auch ï?½ber den Luftpfad umgesetzt, kommt zu MLB neu in die PL48-Getriebe";
CM_ SG_ 512 MO_MAX_Wunschdrehzahl "maximale Motorwunschdrehzahl, die vom Getriebe nicht ï?½berschritten werden darf\n\nSignal darf GE_Synchro_Wunschdrehzahl nicht spiegeln";
CM_ SG_ 512 MO_MIN_Wunschdrehzahl "minimale Motorwunschdrehzahl aufgrund Regeneration, die vom Getriebe nicht unterschritten werden darf\n\nHinweis: \nEhemaliger Fehlerwert 0xFF wird senderseitig nicht unterstï?½tzt. \nDiesen Wert aus Kompatibilitï?½tsgrï?½nden nicht neu belegen!";
CM_ SG_ 512 MO_Motorlaufwarnung "Signal zur Anforderung der 'Motorlaufwarnung' im Kombi.";
CM_ SG_ 512 MO_NGS_Position "Messwert des Neutralgangsensors\n(nur Handschalter)";
CM_ SG_ 512 MO_NGS_Status "Status des Signals MO_NGS_Position. Das MSG prï?½ft die Plausibilitï?½t nur hinsichtlich sicher geï?½ffnetem Triebstrang.";
CM_ SG_ 512 MO_Overboost "Nur Turbo. Anzeige eines Overboostpfeils im Kombi wï?½hrend Overboostzustand der Ladedruckregelung.";
CM_ SG_ 512 MO_Prio_MAX_Wunschdrehzahl "Prioritï?½tsbit der Motorwunschdrehzahl  als MAX";
CM_ SG_ 512 MO_Prio_MIN_Wunschdrehzahl "Prioritï?½tsbit der Motorwunschdrehzahl als MIN";
CM_ SG_ 512 MO_Rampenzeit_Generator_Anf "Das Motorsteuergerï?½t kann eine Load-Response-Zeit des Generators vom Niedervoltenergiemanagement (NVEM) anfordern. Die Load-Response-Zeit wird vom NVEM umgesetzt, wenn dies bordnetzvertrï?½glich mï?½glich ist.";
CM_ SG_ 512 MO_Sperrung_FahrPr_BZS "Sperrung einzelner Betriebszustï?½nde bzgl. Kommunikation zwischen Motor-SG und Charisma-SG (Gateway)";
CM_ SG_ 512 MO_StSt_Charisma_FahrPr "MLBevo: Aktuelles Fahrprogramm des Charisma-Teilnehmers (siehe Systemlastenheft Drive Select)\nMQB: Istwert der Kennlinie (siehe Systemlastenheft MQB FPA)";
CM_ SG_ 512 MO_StSt_Charisma_Status "Charisma Systemstatus des Charisma-Teilnehmers\n\nWert 0x3 ist nur fï?½r Fahrzeuge ab MQB relevant";
CM_ SG_ 512 MO_Text_Aktivierung_Antrieb "Fahrerinformation zur Antriebsstrangaktivierung.";
CM_ SG_ 512 MO_v_Begrenz_Aktivierbar "Fehlerbit wird vom Motor-SG gesetzt, wenn dieses nicht in dieGeschwindigkeits-begrenzung gehen kann, ein Fehler wï?½hrend der v-Begrenzung auftritt oder v > v_Begrenzung - v_Delta";
CM_ SG_ 512 MO_v_Begrenzung_Niveau "Zeigt an, ob eine v-Begrenzung aufgrund Anforderung der Niveauregelung  im MSG aktiv ist oder nicht (Signal fï?½r Niveau zum Steuern der Kombianzeige).";
CM_ SG_ 512 PEA_Abschalttexte "Das Signal dient dem Anzeigen von Abschalttexten, wenn PEA nicht verfï?½gbar ist";
CM_ SG_ 512 PEA_Ereignisanzeige "Das Signal dient der Anzeige des Hinweisgrundes";
CM_ SG_ 512 PEA_Ereignisanzeige_temporaer "Signal dient zur Steuerung einer TPA Anzeige im Kombi";
CM_ SG_ 512 PEA_Fahrerinfo "PEA sendet im Hinweis-/Stï?½rungsfall an das Kombi Informationen zum Anzeigen (Text + Akustik)";
CM_ SG_ 512 PEA_Fortschrittsanzeige "Ablaufbalken fï?½r PEA-Hinweise";
CM_ SG_ 512 PEA_Hinweis "Aufforderung fï?½r Fahrerhandlung durch PEA";
CM_ SG_ 512 PEA_Zielgeschw "Das Signal dient der Anzeige einer Geschwindigkeit eines Geschwindigkeitsereignisses fï?½r PEA";
CM_ SG_ 512 PEA_Zielgeschw_Einheit "Einheit der anzuzeigenden Zielgeschwindigkeit fï?½r PEA (Prï?½diktiver Effizienz Assistent)";
CM_ SG_ 512 TSK_Akustik "Anforderung zur Ausgabe Akustischer Meldungen des Triebstrangkoordinators";
CM_ SG_ 512 TSK_Fahrzeugstatus_GRA "Zur Anzeige der Nicht-Verfuegbarkeit des Geschwindigkeitsregelanlage im Fahrzeugstatus";
CM_ SG_ 512 TSK_Fahrzeugstatus_Limiter "Zur Anzeige der Nicht-Verfuegbarkeit des Speedlimiters im Fahrzeugstatus";
CM_ SG_ 512 TSK_Fahrzeugstatus_praed_Fkt "Zeigt den Status der Prï?½diktion der Kundenfunktionen P_LIM und P_ GRA an";
CM_ SG_ 512 TSK_Limiter_Anzeige "Signalisiert den Wunsch des MSG an das Kombiinstrument, seine Anzeige auf Limiter umzuschalten";
CM_ SG_ 512 TSK_Limiter_Fahrerinfo "Fahrerhinweise und Warnungen des Speedlimiters";
CM_ SG_ 512 TSK_naechstes_Event "Anzeige des naechsten Streckenereignisses, welches in der PGRA-PLIM Regelung eine ï?½nderung der Zielgeschwindigkeit zur Folge hat";
CM_ SG_ 512 TSK_naechstes_Event_Einheit "Das Signal zeigt an in welcher Einheit der Hinweis anzuzeigen ist. Bspw. Schilder in mph und Anzeige in Km/h";
CM_ SG_ 512 TSK_praed_Wunschgeschw "Zur Anzeige der prï?½diktiven Wunschgeschwindigkeit von GRA/Speedlimiter im Kombiinstrument";
CM_ SG_ 512 TSK_praediktiver_Automode "Signal zur Anzeige des Automodes bei praediktivem Limiter/GRA";
CM_ SG_ 512 TSK_praediktiver_Hinweis "Anzeigesteuerung ob Geschwindigkeitshinweis als Vorschlag (zur ï?½bernahme) oder als Hinweis (bei automatischer ï?½bernahme) behandelt werden soll";
CM_ SG_ 512 TSK_Status_Anzeige "Signalisiert den Status von GRA oder Limiter zur Anzeige im Kombiinstrument.\nDer Signalwert 'Limitierung_aktiv' wird nur verwendet fï?½r den Audi Speedlimiter und zeigt bei aktivier Funktion an, dass nahe an der Abregelgeschwindigkeit gefahren wird und die";
CM_ SG_ 512 TSK_Texte "Textmeldungen des TSK zur Darstellung im Kombi";
CM_ SG_ 512 TSK_Texte_Primaeranz "Trigger fï?½r Anzeigetexte von GRA und Limiter, GRA Temporï?½ranzeige (Audi) und Limiter Warnungen\n\n0 keine Anzeige \n1 GRA Symbol passiv xxx km/h / mph (nur Audi)\n2 GRA Symbol aktiv xxx km/h / mph (nur Audi)\n3 Bremse ï?½berhitzt ! (reserv.)\n4 Limiter Modu";
CM_ SG_ 512 TSK_Wunschgeschw "Zur Anzeige der Wunschgeschwindigkeit von GRA/Speedlimiter im Kombiinstrument";
CM_ SG_ 332 FoD_DTC_TSK_ACC "DTC ist entweder bereits eingetragen oder wird eingetragen, sobald die zugehï?½rige FOD Funktion freigeschaltet wird.";
CM_ SG_ 332 FoD_DTC_TSK_GRA "DTC ist entweder bereits eingetragen oder wird eingetragen, sobald die zugehï?½rige FoD Funktion freigeschaltet wird.";
CM_ SG_ 332 ISA_Regelung_aktiv "Signalisiert, dass die Regelung zur ï?½berfï?½hrung der Fahrzeuggeschwindigkeit auf ein gï?½ltiges Tempolimit der Funktion Intelligent Speed Assist (ISA) aktiv ist.";
CM_ SG_ 332 ISA_Status "Signalisiert den Status der Funktion Intelligent Speed Assist (ISA). Der Status zeigt an, ob ISA Tempolimits ï?½bernimmt und einregelt. Dabei wird unterschieden, ob es sich um eine globale Aktivierung/Deaktivierung der Funktion, oder um eine temporï?½re Einsc";
CM_ SG_ 332 ISA_Tempolimitwarnung "Signal zur Ausgabe einer Warnung an den Fahrer, wenn bei aktiviertem Intelligent Speed Assit (ISA) das gï?½ltige Tempolimit ï?½berschritten wird.";
CM_ SG_ 332 KVA_Ist_Pos "KVA Istpositionsrï?½ckmeldung";
CM_ SG_ 332 MO_Anforderung_Anzeige_Halten "Statusanzeige, ob 'Hold'-Anzeige aktiv werden soll. Im Status Halten wird die 'Hold' Anzeige aktiviert. Im Status Rï?½ckrollsicherung wird die 'Hold' Anzeige nicht aktiviert.";
CM_ SG_ 332 MO_Anforderung_HMS "Halteanforderung vom Motor an HMS";
CM_ SG_ 332 MO_EBoost_verf_praed "Zeigt an, ob fï?½r eine im Projekt definierte Zeit (max. 10s) E-Boost in Hï?½he von EM1_maxPred_Moment verfï?½gbar sein wird.\n\n0 - Init_oder_nicht_verfï?½gbar\n1 - EBoost_kurzzeit_verfï?½gbar (~3Sek.)\n2 - EBoost_langzeit_verfï?½gbar (~10Sek)";
CM_ SG_ 332 MO_eLaunch_verf "Zeigt an, ob aus Antriebssicht E-Launch verfï?½gbar ist.";
CM_ SG_ 332 MO_Fahrbereitschaft "Das Signal MO_Fahrbereitschaft zeigt in mehreren Stufen an, ob der Motor in einem anfahrbereiten Zustand ist.";
CM_ SG_ 332 MO_Freilauf_Info "Freilauf Informationssignal vom Motorsteuergerï?½t zum Getriebesteuergerï?½t. Das Motorsteuergerï?½t kann ï?½ber dieses Signal den Freilauf freigeben, verhindern bzw. explizit anfordern.";
CM_ SG_ 332 MO_Freilauf_Status "Freilauf-Status-Signal vom Frailauf-Master an aktive Freilauf-Teilnehmer. In diesem Signal zeigt der Freilauf-Master an, welchen aktuellen Status die Freilauf-Betriebsstrategie hat.";
CM_ SG_ 332 MO_Heckspoiler_Anf "Anforderung den Heckspoiler zur Ladeluft- bzw. Motorraumkï?½hlung auszufahren.";
CM_ SG_ 332 MO_Klima_Regelmodus "Anforderung an Klima SG zur Regelungsanpassung der HV Klimakomponenten bei bestimmten Umweltbedingungen";
CM_ SG_ 332 MO_Krit_Heckobjekt "Beschreibt die Kritikalitï?½t des hinter einem in der Spur fahrenden Fahrzeuges";
CM_ SG_ 332 MO_LaunchControl "Signalisierung einer verfï?½gbaren LaunchControl Funktion ans Kombiinstrument";
CM_ SG_ 332 MO_NGS_Gangpos "Gang- bzw. Neutralinformation des erweiterten Neutralgangsensors. Bedingt durch den eingeschrï?½nkten Erfassungssbereich des Sensors sind die Ganginformationen als eingelegt bzw. fast eingelegt/vorausgewï?½hlt zu interpretieren (nur Handschalter)";
CM_ SG_ 332 MO_OnePedal_Verzoegerungsstufe "Angabe der Verzï?½gerungsstufe fï?½r One Pedal Driving";
CM_ SG_ 332 MO_Positionierung_aktiv "Zeigt an, dass die Motorpositionierung mit Hilfe des Riemenstartergenerator momentan aktiv ist.";
CM_ SG_ 332 MO_QBit_Aussen_Temp "QBit der Aussentemperatur. Gesetzt bei Ersatzwert, Init oder Fehler.";
CM_ SG_ 332 MO_Red_El_Fahrleistung "Anzeige einer eingeschrï?½nkten Fahrleistung";
CM_ SG_ 332 MO_Servicemodus "Ausgabe aktiver Service-Mode";
CM_ SG_ 332 MO_Startwunsch "o\tSetzen bei Erfï?½llung der kompletten Fahrerbedienhandlung (z.B. Zï?½ndanlasstaster + Bremse + Fahrstufe P/N [klassisch] oder Fahrstufe D/R + Bremse [MEB]), je nach Fahrzeug z.T. bereits vor oder immer erst nach Einschalten der Klemme 15;\no\tRï?½cksetzen bei ";
CM_ SG_ 332 MO_UBE_Reserve "Seitens Antrieb erforderliche Energiereserve der HV-Batterie, die den Fuï?½punkt der ï?½Usable Battery Energyï?½ (BMS_UBE) verschiebt. Die Reserve dient der Gewï?½hrleistung von Sicherheitsfunktionen und ggf. Emissionierungsmaï?½nahmen unterhalb des Fahrbetriebs im";
CM_ SG_ 332 Motor_54_BZ "4bit Botschaftszï?½hler, wird mit jeder Sendebotschaft inkrementiert";
CM_ SG_ 332 Motor_54_CRC "Fï?½r MLB:\nBerechnung siehe Lastenheft 'Kommunikationsabsicherung fï?½r FlexRay und CAN'\nAb MQB und MLBevo:\nBerechnung siehe Lastenheft 'End-to-End Kommunikationsabsicherung'\n\nEndwerte siehe Begleitdokument 'S-PDU Kennungsfolgen'";
CM_ SG_ 332 OBD_Abs_Load_Val "Absolute Load Value\n\nï?½bertragung von Meï?½grï?½ï?½en an das Getriebesteuergerï?½t fï?½r Freeze Frame Abspeicherung bei Getriebefehlern\n\nPID $43 Absolute Load Value; 0 .. 25700%  mit 100/255 %/bit";
CM_ SG_ 332 OBD_Abs_Pedal_Pos "Absolute Pedal Position\n\nï?½bertragung von Meï?½grï?½ï?½en an das Getriebesteuergerï?½t fï?½r Freeze Frame Abspeicherung bei Getriebefehlern\n\nPID $49 Accelerator Pedal Position D; 0 .. 100% mit 100/255 %/bit";
CM_ SG_ 332 OBD_Abs_Throttle_Pos "Absolute Throttle Position\n\nï?½bertragung von Meï?½grï?½ï?½en an das Getriebesteuergerï?½t fï?½r Freeze Frame Abspeicherung bei Getriebefehlern\n\nPID $11 Absolute Throttle Position; 0 .. 100% mit 100/255 %/bit";
CM_ SG_ 332 OBD_Aussen_Temp_gef "Gefilterte Aussentemperatur vom Motor fï?½r OBD Funktionen.";
CM_ SG_ 332 OBD_Calc_Load_Val "Calculated Load Value\n\nï?½bertragung von Meï?½grï?½ï?½en an das Getriebesteuergerï?½t fï?½r Freeze Frame Abspeicherung bei Getriebefehlern\n\nPID $04 Calculated Load Value; 0 .. 100% mit 100/255 % per bit\n";
CM_ SG_ 332 OBD_ClearMem_Inhibit "Bei FSP_Loeschen_zulï?½ssig mï?½ssen alle OBD-ECUs im Gesamtfahrzeug einen Service 04hex Request (Ereignisspeicher lï?½schen) korrekt ausfï?½hren. \n\nIn MLB-, MLBevo-, MQB-Fahrzeugkonzepten muss der MIL-Master/Motorsteuergerï?½t bei Kl.15 ein, projektabhï?½ngig, kon";
CM_ SG_ 332 OBD_Driving_Cycle "Signalisierung Driving Cycle Qualifizierung - Trigger Ignition Cycle Counter";
CM_ SG_ 332 OBD_Eng_Cool_Temp "Engine Coolant Temperature\n\nï?½bertragung von Meï?½grï?½ï?½en an das Getriebesteuergerï?½t fï?½r Freeze Frame Abspeicherung bei Getriebefehlern\n\nPID $05 Engine Coolant Temperature; -40 .. +215ï?½C mit 1ï?½C/bit und 40ï?½C Offset";
CM_ SG_ 332 OBD_Kaltstart_Denominator "Bestimmte Diagnosen werden nur unter Kaltstartbedingungen durchgefï?½hrt, der entsprechende Denominator bei IUMPR-pflichtigen Systemen wird anhand dieses vom MSG gebildeten Signals inkrementiert. (Entspricht EVAP-Denominator)";
CM_ SG_ 332 OBD_Minimum_Trip "Grundlage OBD-Gesetz CCR 1968.2 (d)(4.3) Denominator Specifications\nBildung des General Denominator 'Normed Trip':\n600 sec. (kumulativ) Zeit nach Motorstart\n300 sec. (kumulativ) mit Fahrzeuggeschwindigkeit > 25 mph (40 km/h)\n30 sec. (kontinuierlich";
CM_ SG_ 332 OBD_Normed_Trip "Gesetzlich definierte 'Normed Condition' erfï?½llt, 'General Denominator' darf erhï?½ht werden";
CM_ SG_ 332 OBD_Sperrung_IUMPR "Wenn der General Denominator auf Grund eines Fehlers in den Eingangsgrï?½ï?½en gesperrt wird, wird diese Information ï?½ber Bussystem als OBD-Statusinformation OBD_Sperrung_IUMPR fï?½r andere OBD-Steuergerï?½te bereitgestellt. \n\nDas MSG (MIL-Master) setzt dieses ";
CM_ SG_ 332 OBD_Sperrung_Kaltstart_Denom "Information vom MIL Master, dass die Bildung des EVAP Denominators  im Motor nicht mï?½glich ist und damit der noECM-Denominator gesperrt werden darf.";
CM_ SG_ 332 OBD_Warm_Up_Cycle "Mit dem Warm-Up-Cycle wird der zentrale Verlernzï?½hler vom Gateway inkrementiert";
CM_ SG_ 332 TSK_ACC_FoD_Status "Information, ob die TSK-ACC-Funktion freigeschaltet ist oder nicht.";
CM_ SG_ 332 TSK_aktives_System "Anzeige der in der TSK-Lï?½ngsfï?½hrung aktiven Funktion";
CM_ SG_ 332 TSK_Anf_Antriebsmoment "Das Signal zeigt an, ob die TSK-Laengsregelung aktuell Antriebsmoment anfordert, zur Verwendung in der ASR/EDS-Funktion";
CM_ SG_ 332 TSK_Einheit_vMax_Fahrerassistenz "Einheit zu Signal TSK_vMax_Fahrerassistenz";
CM_ SG_ 332 TSK_erhoehter_Fahrwiderstand "Rueckmeldung vom Triebstrangkoordinator, dass eine groï?½e Reglerdifferenz detektiert wurde. Soll ermoeglichen, einen ggfs. unbekannten Fahrwiderstand am Boden zu erkennen.";
CM_ SG_ 332 TSK_GRA_FoD_Status "Information, ob die TSK-GRA-Funktion freigeschaltet ist oder nicht.";
CM_ SG_ 332 TSK_Status_ARA "Funktionsstatus des Triebstrangkoordinators fï?½r den Anhï?½ngerrangierassistenten";
CM_ SG_ 332 TSK_Status_EA "Funktionsstatus des Triebstrangkoordinators fï?½r den Anforderer Emergency Assist";
CM_ SG_ 332 TSK_Status_IPA "Funktionsstatus des Triebstrangkoordinators fï?½r die Lï?½ngsfï?½hrung des Einparkassistenten";
CM_ SG_ 332 TSK_Status_PLA "Funktionsstatus des Triebstrangkoordinators fï?½r den Speedlimiter des Parkassistenten";
CM_ SG_ 332 TSK_vMax_aktuell "Im aktuellen Betriebszustand global gï?½ltige Geschwindigkeitslimitierung.";
CM_ SG_ 332 TSK_vMax_Fahrerassistenz "maximale Sollgeschwindigkeit fï?½r GRA/ACC/Limiter\nHinweis: Signal ist mit Signal TSK_Einheit_vMax_Fahrerassistenz zu interpretieren.  Das Signal wird abwechselnd in km/h und mph gesendet.";
CM_ SG_ 2463978666 MO_Drehzahl_EM "Effektivdrehzahl, die am E-Maschinenausgang ermittelt wird, die fï?½r die Primï?½rachse zur Verfï?½gung steht";
CM_ SG_ 2463978666 MO_Drehzahl_EM_sek "Effektivdrehzahl, die am E-Maschinenausgang ermittelt wird, die fï?½r die Sekundï?½rachse zur Verfï?½gung steht";
CM_ SG_ 2463978666 MO_EM1_Generator_Leistung "elektrische Wunschleistung zur Berechnung eines momentan erforderlichen Moments im Generatorbetrieb";
CM_ SG_ 2463978666 MO_EM1_Max_Leistung_Gesamt "im Gesamtsystem verfï?½gbare elektrische Leistung fï?½r den motorischen Betrieb; elektrische Leistung zur Berechnung eines momentan mï?½glichen";
CM_ SG_ 2463978666 MO_EM1_Max_Spannung_Lim "maximal zulï?½ssige HV-Spannung (DC), die von der LE im generatorischen Betrieb nicht ï?½berschritten werden darf; Abregelspannung zur Begrenzung des minimalen Moments im generatorischen Betrieb";
CM_ SG_ 2463978666 MO_EM1_Min_Leistung_Gesamt "vom Gesamtsystem aufnehmbare elektrische Leistung fï?½r den generatorischen Betrieb (betragsmï?½ï?½ig maximal aber i.d.R. negativ, daher ï?½Minï?½); elektrische Leistung zur Berechnung eines momentan mï?½glichen minimalen Moments (maximal genaratorisch)";
CM_ SG_ 2463978666 MO_EM1_Min_Spannung_Lim "minimal zulï?½ssige HV-Spannung (DC), die von der LE im motorischen Betrieb nicht unterschritten werden darf; Abregelspannung zur Begrenzung des maximalen Moments im motorischen Betrieb";
CM_ SG_ 2463978666 MO_EM2_Generator_Leistung "elektrische Wunschleistung zur Berechnung eines momentan erforderlichen Moments im Generatorbetrieb";
CM_ SG_ 2463978666 MO_EM2_Max_Leistung_Gesamt "im Gesamtsystem verfï?½gbare elektrische Leistung fï?½r den motorischen Betrieb; elektrische Leistung zur Berechnung eines momentan mï?½glichen";
CM_ SG_ 2463978666 MO_EM2_Max_Spannung_Lim "maximal zulï?½ssige HV-Spannung (DC), die von der LE im generatorischen Betrieb nicht ï?½berschritten werden darf; Abregelspannung zur Begrenzung des minimalen Moments im generatorischen Betrieb";
CM_ SG_ 2463978666 MO_EM2_Min_Leistung_Gesamt "vom Gesamtsystem aufnehmbare elektrische Leistung fï?½r den generatorischen Betrieb (betragsmï?½ï?½ig maximal aber i.d.R. negativ, daher ï?½Minï?½); elektrische Leistung zur Berechnung eines momentan mï?½glichen minimalen Moments (maximal genaratorisch)";
CM_ SG_ 2463978666 MO_EM2_Min_Spannung_Lim "minimal zulï?½ssige HV-Spannung (DC), die von der LE im motorischen Betrieb nicht unterschritten werden darf; Abregelspannung zur Begrenzung des maximalen Moments im motorischen Betrieb";
CM_ SG_ 2463978666 MO_Rekuperation_EM_Ges_Ueberlauf "Rekuperationleistungssignal mindest 1x ï?½bergelaufen";
CM_ SG_ 2463978666 MO_Rekuperation_Ges_EM "Rekuperation-Energie des Antriebs";
CM_ SG_ 2463978666 MO_Uebersetzung_EM "ï?½bersetzung von MO_Drehzahl_EM zur Primï?½rachse, wenn eine Verbindung sicher hergestellt ist";
CM_ SG_ 2463978666 MO_Uebersetzung_EM_sek "ï?½bersetzung von MO_Drehzahl_EM_sek zur Sekundï?½rachse, wenn eine Verbindung sicher hergestellt ist";
CM_ SG_ 2463978666 MO_Verbrauch_EM_Ges "Antriebs-Energie des Antriebs";
CM_ SG_ 2463978666 MO_Verbrauch_EM_Ges_Ueberlauf "Verbrauchssignal mindest 1x ï?½bergelaufen";
CM_ SG_ 2463978666 Motor_57_BZ "4bit Botschaftszï?½hler, wird mit jeder Sendebotschaft inkrementiert";
CM_ SG_ 2463978666 Motor_57_CRC "Fï?½r MLB:\nBerechnung siehe Lastenheft 'Kommunikationsabsicherung fï?½r FlexRay und CAN'\nAb MQB und MLBevo:\nBerechnung siehe Lastenheft 'End-to-End Kommunikationsabsicherung'\n\nEndwerte siehe Begleitdokument 'S-PDU Kennungsfolgen'";
CM_ SG_ 2331595982 PTHyDrA_PrctUtilElDrv "Display for Fahrer Information Display, that shows the utilization in percent of the electric drive system. When full the combustion engine shall start.";
CM_ SG_ 2331595982 PTHyDrA_StAcv "Status-Information Assistent fï?½r elektrisches Fahren";
CM_ SG_ 2331595982 PTUIPwrm_FacPwrDyn "Dynamik-Faktor fï?½r die anzuzeigende momentane relative Systemleistung im Powermeter";
CM_ SG_ 2331595982 PTUIPwrm_PrctBoostAvl "Anzuzeigende relative Verfï?½gbarkeit des Boost.";
CM_ SG_ 2331595982 PTUIPwrm_PrctPeakPwrAvl "relative Verfï?½gbarkeitsdauer der maximalen Vortriebs-Leistung (Fï?½llstand des MaxLeistung-Topfes)";
CM_ SG_ 2331595982 PTUIPwrm_PrctPwrElBoostCur "Anzuzeigende momentane relative Leistung des Boost";
CM_ SG_ 2331595982 PTUIPwrm_PrctPwrElBoostMaxUse "Anzuzeigende relative nutzbare Leistung des Boost.";
CM_ SG_ 2331595982 PTUIPwrm_PrctPwrElDrvCur "Anzuzeigende momentane relative Leistung des elektrischen Antriebs im Powermeter";
CM_ SG_ 2331595982 PTUIPwrm_PrctPwrGnrMaxUse "Anzuzeigende relative nutzbare generatorische Leistung im Powermeter";
CM_ SG_ 2331595982 PTUIPwrm_PrctPwrMotElMaxUse "Anzuzeigende relative nutzbare motorische Leistung des elektr. Antriebs im Powermeter";
CM_ SG_ 2331595982 PTUIPwrm_PrctPwrMotMaxUse "Anzuzeigende relative nutzbare motorische Leistung im Powermeter";
CM_ SG_ 2331595982 PTUIPwrm_PrctPwrSysCur "Anzuzeigende momentane relative Systemleistung im Powermeter";
CM_ SG_ 2331595982 PTUIPwrm_PwrElBoostNom "nominelle Boost-Leistung des elektrischen Antriebs";
CM_ SG_ 2331595982 PTUIPwrm_StAcv "Status-Information Powermeter";
CM_ SG_ 2589283946 PTUIPwrm_PwrGnrNom "nominelleï?½Verzï?½gerungs-Leistung des elektrischen Antriebsï?½";
CM_ SG_ 2589283946 PTUIPwrm_PwrMotElNom "nominelleï?½Vortriebs-Leistung des elektrischen Antriebs";
CM_ SG_ 2589283946 PTUIPwrm_PwrSysMotNomDisp "nominelle Vortriebs-Leistung des Gesamtantriebs";
CM_ SG_ 1155 MO_Powermeter_Charge_Grenze "Zeigt eine Einschrï?½nkung der Rekuperationsleistung an\n";
CM_ SG_ 1155 Mo_Powermeter_Grenze "Anzeige des verfï?½gbaren Powermeterstands im Kombi. Bei EV Unterscheidung zwischen Boost- und Dauerbereich, bei HEV fï?½r die Zustartgrenze nutzber";
CM_ SG_ 1155 MO_Powermeter_Grenze_strategisch "Zeigt eine strategische Leistungsbeschrï?½nkung des Antriebs, \nzum Beispiel kein Boost im Efficiency Modus";
CM_ SG_ 1155 MO_Powermeter_Inszenierung_aktiv "Mit Hilfe des Signals kann eine Dynamikabfahrt fï?½r den Kunden inszeniert werden. Die Inszenierung wird im Powermeter des Kombi-Instruments verortet.";
CM_ SG_ 1155 MO_Powermeter_obere_E_Grenze "Zeigt die obere Grenze fï?½r das elektrische Fahren an";
CM_ SG_ 1155 MO_Powermeter_untere_E_Grenze "Zeigt die untere Grenze fï?½r das elektrische Fahren an";
CM_ SG_ 1156 ND_GDOP "geometric dilution of precision (Gesamtgenauigkeit, 3D und Zeit) \n";
CM_ SG_ 1156 ND_HDOP "horizontal dilution of precision (Horizontalrichtung, 2D)\n";
CM_ SG_ 1156 ND_Heading "Fahrtrichtung";
CM_ SG_ 1156 ND_Init "Initialisierung";
CM_ SG_ 1156 ND_PDOP "positional dilution of precision (Positionsgenauigkeit, 3D) \n";
CM_ SG_ 1156 ND_TDOP "time dilution of precision (Zeitgenauigkeit)\n";
CM_ SG_ 1156 ND_VDOP "vertical dilution of precision (Vertikalrichtung, 1D)\n";
CM_ SG_ 1157 ND_SatInUse "Anzahl der zur Berechnung verwendeten Satelliten";
CM_ SG_ 1157 ND_SatInView "Anzahl der sichtbaren Satelliten";
CM_ SG_ 1157 ND_UTC "UTC-Zeit, verstrichene Sekunden seit 01.01.1970 00:00\n0xFFFFFFFE = Init\n0xFFFFFFFF = Fehler bei Berechnung der UTC-Time";
CM_ SG_ 1157 NP_Altitude "Hoehe ueber NN\n0xFFF = Fehler bei der Berechnung der Hï?½he ï?½ber NN";
CM_ SG_ 1157 POS_Guete_horizontal "Horizontale Genauigkeit der Position in der Botschaft NavPos_02_MapMatched (Signale\nPOS_LatDegree, POS_LongDegree)\n\nAbhï?½ngig vom Signal\nPOS_Guete_horizontal_verfuegbar";
CM_ SG_ 1157 POS_Guete_horizontal_verfuegbar "Bei gesetztem Bit wird das Signal POS_Guete_horizontal befï?½llt und ist verfï?½gbar.";
CM_ SG_ 2527679512 ND_Fuelstation_detected "Signal gibt an ob eine Tankstelle erkannt wurde";
CM_ SG_ 2527679512 ND_NrSameMeasure "GPS Anzahl der gleichen Messungen";
CM_ SG_ 2527679512 ND_RecDelay "Fï?½r MLBevo:\nZeit in ms zwischen zwei Interruptauslï?½sungen des GPS Receiver.\n\nFï?½r MLBevoGen2:\nZeit in ms zwischen UTC-Sekunde und Messzeitpunkt des GPS Receiver.";
CM_ SG_ 2527679512 ND_RouteType "Routentyp.";
CM_ SG_ 2527679512 ND_SendDelay "Zeit in ms zwischen Interruptauslï?½sung GPS Receiver (Beginn der Messung) und Senden auf den CAN Bus.";
CM_ SG_ 2527679512 ND_TimeOffset "Offset zu ND_TimeToDestination.";
CM_ SG_ 2527679512 ND_TimeToDestination "Zeit in min bis zum Erreichen des Ziel. Wird ausgegeben bei aktiver Routenfï?½hrung oder bei gelernter Route (MPR).";
CM_ SG_ 2527679512 ND_Timezone_DaylightSavingOffset "Offest der Sommerzeit/Winterzeit\n\n0 = kein Offset ; \n1 = 0,5h;  \n2 = 1h";
CM_ SG_ 2527679512 ND_Timezone_Offset "Aktuelle Zeitzonen-Offset des Fahrzeugs.\nVorzeichen und Gï?½ltigkeit beachten";
CM_ SG_ 2527679512 ND_Timezone_SignBit "Vorzeichen des Zeitzonenoffsets.";
CM_ SG_ 2527679512 ND_Timezone_Validity "Gï?½ltigkeit des Zeitzonensignals.";
CM_ SG_ 2527679512 ND_Velocity "GPS Geschwindigkeit";
CM_ SG_ 2527679665 ND_Avrg_Speed_RangeData "Durchschnittsgeschwindigkeit der aktuell befahrenen Strassenkante (Ist-Position Fahrzeug) fuer die Berechnung der routenbasierenden Reichweite.";
CM_ SG_ 2527679665 ND_PSD_Street_Category "The navigation system shall sent the street category for the current car position within the CAN signal ND_PSD_Street_Category.\nThe street category shall correspond to the category sent in the signal PSD_Strassenkategorie for this position.";
CM_ SG_ 1158 NP_LatDegree "Latitude (Nord-Sï?½d Wert)";
CM_ SG_ 1158 NP_LatDirection "Hemisphï?½re Nord/Sï?½d";
CM_ SG_ 1158 NP_LongDegree "Longitude (Ost-West Wert)";
CM_ SG_ 1158 NP_LongDirection "Hemisphï?½re Ost/West";
CM_ SG_ 1158 NP_Sat "Nummer der verwendeten Sateliten beim letzten Fix";
CM_ SG_ 2589283496 POS_Heading "Heading of current position\nMUX(1)";
CM_ SG_ 2589283496 POS_Heading_Trust "Vertrauenswert Heading \nMUX(1) ";
CM_ SG_ 2589283496 POS_Last_GPS_Sync "Letztes bekannte GPS Sync in [s]\nMUX(1)";
CM_ SG_ 2589283496 POS_LatDegree "latitude - position data of navigation\nMUX(0)";
CM_ SG_ 2589283496 POS_LatDirection "latitude direction nav position\nMUX(0)";
CM_ SG_ 2589283496 POS_LongDegree "long - position data of navigation\nMUX(0)";
CM_ SG_ 2589283496 POS_LongDirection "longitude direction nav position\nMUX(0)";
CM_ SG_ 2589283496 POS_MUX "Multiplex-Signal zum schalten des Signals der Positionen von der Navigation.\nMUX(0/1)";
CM_ SG_ 2589283496 POS_ODD_EVEN "Synchronisation der MUX Pos Signale\nMUX(0/1)";
CM_ SG_ 2589283496 POS_PosStati "Aktueller Status der Navgation:\nMUX(0)\n0   init\n1   no nav available (ready_4_nav)\n2   no map available (sd_removed, not_enabled)\n3   nav booting\n4   nav error\n5   nav calibrating\n6   nav no gps resync since 1h\n7   nav offroad  parkgarage ramp of";
CM_ SG_ 2589283496 POS_UTC_REF "Zeitstempel der Nav\nMUX(1)\n\nUTC-Zeit, verstrichene Sekunden seit 01.01.1970 00:00\n0xFFFFFFFE = Init\n0xFFFFFFFF = Fehler bei Berechnung der UTC-Time\n\nSignal wird nur bei aktiver Navigation-Funktion zyklisch gesendet.";
CM_ SG_ 2527679647 MDK_Anf_Start_Auth "Anforderung vom MDK, um die Authentifizierung fï?½r den Motorstart zu triggern.";
CM_ SG_ 2527679647 MDK_BTLE_Spielschutz_aktivieren "Aktivierung Spielschutz Richtung BTLE-TrM";
CM_ SG_ 2527679647 MDK_NFC_Spielschutz_aktivieren "Aktivierung Spielschutz Richtung NFC-STGs";
CM_ SG_ 2527679647 NFC_ESM_aktivieren "Energiesparmodus aktivieren, da z.B. Batterie kritisch";
CM_ SG_ 2527679647 NFC_Laden_unterbrechen "Kommunikation zur Phonebox, das Laden zu unterbrechen";
CM_ SG_ 2527679647 Stellgliedtest_NFC "Applikationssignal um NFC Stellgliedtest abzubilden";
CM_ SG_ 2527679645 NFC_MiKo_ESM_aktiv "Energiesparmodus ist aktiv, z.B. nach 72h Fahrzeugstillstand";
CM_ SG_ 2527679645 NFC_MiKo_Fehler "Das Steuergeraet hat einen Fehler und ist nicht komplett einsatzfaehig.";
CM_ SG_ 2527679645 NFC_MiKo_Laden_unterbrechen "Anforderung seitens Mittelkonsolen-STG das Laden in der Phonebox zu unterbrechen";
CM_ SG_ 2527679645 NFC_MiKo_NFC_Device_gekoppelt "Ein NFC-Device ist im Empfangsbereich und der NFC-Reader hat eine aktive Verbindung aufgebaut.";
CM_ SG_ 2527679645 NFC_MiKo_NFC_Device_Status "Status der aktuellen NFC Erkennung";
CM_ SG_ 2600468745 NM_DispKBI_FS_CAB_V15 "CAB = Clusteraktivbits (V15)";
CM_ SG_ 2600468745 NM_DispKBI_FS_CarWakeup "Car Wakeup (Gateway wertet aus)";
CM_ SG_ 2600468745 NM_DispKBI_FS_CBV_AWB "Das Signal ist zu setzen, wenn das SG aktiv den Bus geweckt hat";
CM_ SG_ 2600468745 NM_DispKBI_FS_CBV_CRI "Das Signal ist dauerhaft gesetzt, wenn das NM-Layout Cluster- Anforderungen enthï?½lt";
CM_ SG_ 2600468745 NM_DispKBI_FS_NM_aktiv_Diagnose "Diagnose befindet sich nach VW80124 in einer NonDefaultDiagnostic-Session, z.B. ExtendedDiagnostic-Session";
CM_ SG_ 2600468745 NM_DispKBI_FS_NM_aktiv_KL15 "Steuergerï?½t hat KL15-EIN erkannt";
CM_ SG_ 2600468745 NM_DispKBI_FS_NM_aktiv_Tmin "Mindestaktivzeit ist noch nicht abgelaufen (bei jedem Weckereignis wird die Mindestaktivzeit neu gestartet)";
CM_ SG_ 2600468745 NM_DispKBI_FS_NM_State "1 = Zustand Repeat Message (<-- Bus-Sleep Mode)\n2 = Zustand Repeat Message (<-- Prepare Bus-Sleep Mode)\n4 = Zustand Normal Operation (<-- Repeat Message)\n8 = Zustand Normal Operation (<-- Ready Sleep)";
CM_ SG_ 2600468745 NM_DispKBI_FS_UDS_CC "Funktionseinschrï?½nkung aufgrund aktivem UDS-Communication Control, siehe VW80124";
CM_ SG_ 2600468496 NM_Gateway_CAB_V15 "CAB = Clusteraktivbits (V15)";
CM_ SG_ 2600468496 NM_Gateway_Car_Wakeup "Car Wakeup (Subbusmaster wertet aus)\n\nMQB: \n-Diagnose- oder Komponentenschutzmaster-Funktion weckt den schlafenden Subbus (z.B. MOST)\n\nE3_Volumen:\n- Diagnose aktiv -aktive Diagnosekommunikation am OBD-Stecker\n\nMQBw_Baseline:\n- Diagnose aktiv -akt";
CM_ SG_ 2600468496 NM_Gateway_CBV_AWB "Das Signal ist zu setzen, wenn das SG aktiv den Bus geweckt hat\n0 = Passiver_WakeUp = SG hat das Netzwerk nicht aktiv geweckt\n1 = Akitiver_WakeUp = SG hat das Netzwerk aktiv geweckt";
CM_ SG_ 2600468496 NM_Gateway_CBV_CRI "Das Signal ist dauerhaft gesetzt, wenn das NM-Layout Cluster- Anforderungen enthï?½lt";
CM_ SG_ 2600468496 NM_Gateway_NM_aktiv_CAB "Nachlauf aufgrund Kopplung mehrerer Busse. z.B. K-CAN und K2-CAN, Clusteranforderung ï?½ber CAB und Car Wakeup Anforderung.";
CM_ SG_ 2600468496 NM_Gateway_NM_aktiv_Diagnose "Diagnose befindet sich nach VW80124 in einer NonDefaultDiagnostic-Session, z.B. ExtendedDiagnostic-Session";
CM_ SG_ 2600468496 NM_Gateway_NM_aktiv_Energie "Dieser Bus wird auf Grund einer Aktivitï?½t der Funktion EMHLR, HVEM, Dynamic Charging POI, Charging-Management-Server oder Extended Charging Monitoring wachgehalten";
CM_ SG_ 2600468496 NM_Gateway_NM_aktiv_FoD "Dieser Bus wird auf Grund einer Aktivitï?½t der Function on Demand wachgehalten";
CM_ SG_ 2600468496 NM_Gateway_NM_aktiv_IAA_PSO "Dieser Bus wird auf Grund einer Aktivitï?½t der Personalisierung wachgehalten";
CM_ SG_ 2600468496 NM_Gateway_NM_aktiv_Kessy "Dieser Bus wird auf Grund einer Aktivitï?½t der Funktion Kessy wachgehalten";
CM_ SG_ 2600468496 NM_Gateway_NM_aktiv_KL15 "Steuergerï?½t hat KL15-EIN erkannt";
CM_ SG_ 2600468496 NM_Gateway_NM_aktiv_KS "Dieser Bus wird auf Grund einer Aktivitï?½t des Komponentenschutzes wachgehalten";
CM_ SG_ 2600468496 NM_Gateway_NM_aktiv_Licht "Dieser Bus wird auf Grund einer Aktivitï?½t der Funktion Dimmung oder Standard Auï?½enlicht wachgehalten";
CM_ SG_ 2600468496 NM_Gateway_NM_aktiv_PaCo "Dieser Bus wird auf Grund einer Aktivitï?½t des Park Koordinators wachgehalten";
CM_ SG_ 2600468496 NM_Gateway_NM_aktiv_RTM "Dieser Bus wird auf Grund einer Aktivitï?½t des Real Time Monitors wachgehalten";
CM_ SG_ 2600468496 NM_Gateway_NM_aktiv_Standklima "Dieser Bus wird auf Grund einer Aktivitï?½t der Standklimatisierung wachgehalten";
CM_ SG_ 2600468496 NM_Gateway_NM_aktiv_Tmin "Mindestaktivzeit ist noch nicht abgelaufen (bei jedem Weckereignis wird die Mindestaktivzeit neu gestartet)";
CM_ SG_ 2600468496 NM_Gateway_NM_aktiv_USS "Dieser Bus wird auf Grund einer Aktivitï?½t des User State Servers wachgehalten";
CM_ SG_ 2600468496 NM_Gateway_NM_aktiv_ZM "Dieser Bus wird auf Grund einer Aktivitï?½t des Zeitmasters wachgehalten";
CM_ SG_ 2600468496 NM_Gateway_NM_aktiv_ZV "Dieser Bus wird auf Grund einer Aktivitï?½t der Zentralverriegelung wachgehalten";
CM_ SG_ 2600468496 NM_Gateway_NM_State "1 = Zustand Repeat Message (<-- Bus-Sleep Mode)\n2 = Zustand Repeat Message (<-- Prepare Bus-Sleep Mode)\n4 = Zustand Normal Operation (<-- Repeat Message)\n8 = Zustand Normal Operation (<-- Ready Sleep)";
CM_ SG_ 2600468496 NM_Gateway_UDS_CC "Funktionseinschrï?½nkung aufgrund aktivem UDS-Communication Control, siehe VW80124";
CM_ SG_ 2600468507 NM_HUD_CAB_V15 "CAB = Clusteraktivbits (V15)";
CM_ SG_ 2600468507 NM_HUD_Car_WakeUp "Das Bit wird vom Waehlhebel nicht bedient. Die Car Wakeup-Funktionalitï?½t ist im Waehlhebel nicht umgesetzt.\n";
CM_ SG_ 2600468507 NM_HUD_CBV_AWB "Das Signal ist zu setzen, wenn das SG aktiv den Bus geweckt hat\n0 = Passiver_WakeUp = SG hat das Netzwerk nicht aktiv geweckt\n1 = Akitiver_WakeUp = SG hat das Netzwerk aktiv geweckt";
CM_ SG_ 2600468507 NM_HUD_CBV_CRI "Das Signal ist dauerhaft gesetzt, wenn das NM-Layout Cluster- Anforderungen enthï?½lt";
CM_ SG_ 2600468507 NM_HUD_NM_aktiv_Diagnose "Diagnose befindet sich nach VW80124 in einer NonDefaultDiagnostic-Session, z.B. ExtendedDiagnostic-Session";
CM_ SG_ 2600468507 NM_HUD_NM_aktiv_KL15 "Steuergerï?½t hat KL15-EIN erkannt";
CM_ SG_ 2600468507 NM_HUD_NM_aktiv_Tmin "Mindestaktivzeit ist noch nicht abgelaufen (bei jedem Weckereignis wird die Mindestaktivzeit neu gestartet)";
CM_ SG_ 2600468507 NM_HUD_NM_State "1 = Zustand Repeat Message (<-- Bus-Sleep Mode)\n2 = Zustand Repeat Message (<-- Prepare Bus-Sleep Mode)\n4 = Zustand Normal Operation (<-- Repeat Message)\n8 = Zustand Normal Operation (<-- Ready Sleep)";
CM_ SG_ 2600468507 NM_HUD_UDS_CC "Funktionseinschrï?½nkung aufgrund aktivem UDS-Communication Control, siehe VW80124";
CM_ SG_ 2600468595 NM_Info_El_CAB_V15 "CAB = Clusteraktivbits (V15)\n\nCluster - CAB_02_Hybrid\n-Ausstiegspanel (Bedienmï?½glichkeit bei S-Kontakt EIN fï?½r maximal 60sec)\n\nCluster - CAB_04_Fahrerassistenz\n-Ausstiegspanel (Bedienmï?½glichkeit bei S-Kontakt EIN fï?½r maximal 60sec)\n\nCluster - CAB_";
CM_ SG_ 2600468595 NM_Info_El_Car_Wakeup "Car Wakeup (Gateway wertet aus)\n\nMLBevo:\n- Remote Lock/Unlock\n- Remote STH\n\nMQB (MIB ab Gen3):\n- OCU Download";
CM_ SG_ 2600468595 NM_Info_El_CBV_AWB "Das Signal ist zu setzen, wenn das SG aktiv den Bus geweckt hat\n0 = Passiver_WakeUp = SG hat das Netzwerk nicht aktiv geweckt\n1 = Akitiver_WakeUp = SG hat das Netzwerk aktiv geweckt";
CM_ SG_ 2600468595 NM_Info_El_CBV_CRI "Das Signal ist dauerhaft gesetzt, wenn das NM-Layout Cluster- Anforderungen enthï?½lt";
CM_ SG_ 2600468595 NM_Info_El_NM_aktiv_Applikation "Eine Applikationsanforderung fordert den Bus";
CM_ SG_ 2600468595 NM_Info_El_NM_aktiv_BAP_Comm "MQB:\nCAN wird zum Betrieb des BAP CAN Verstï?½rkers wachgehalten";
CM_ SG_ 2600468595 NM_Info_El_NM_aktiv_Diagnose "Diagnose befindet sich nach VW80124 in einer NonDefaultDiagnostic-Session, z.B. ExtendedDiagnostic-Session";
CM_ SG_ 2600468595 NM_Info_El_NM_aktiv_IAA "IAA: Nutzeridentifikation / Management ist aktiv";
CM_ SG_ 2600468595 NM_Info_El_NM_aktiv_KL15 "Steuergerï?½t hat KL15-EIN erkannt";
CM_ SG_ 2600468595 NM_Info_El_NM_aktiv_MIBCAN "MIB-CAN lï?½nger als Mindestaktivzeit aktiv fï?½r: SWDL, TEL, Radio_On/Hour_Mode, Mute_Mode\nTT3: ICAN lï?½nger als Mindestaktivzeit aktiv fï?½r MFL-Bedienung";
CM_ SG_ 2600468595 NM_Info_El_NM_aktiv_Powerstate "Dieser Bus wird auf Grund des Powerstates MMI_STANDBY(_PWR_Save_1) oder MMI_ON(_DIAG/_TEL) wachgehalten";
CM_ SG_ 2600468595 NM_Info_El_NM_aktiv_SmartLight "Aktivitï?½t der Smartlight Applikation im SG";
CM_ SG_ 2600468595 NM_Info_El_NM_aktiv_Tmin "Mindestaktivzeit ist noch nicht abgelaufen (bei jedem Weckereignis wird die Mindestaktivzeit neu gestartet)";
CM_ SG_ 2600468595 NM_Info_El_NM_State "1 = Zustand Repeat Message (<-- Bus-Sleep Mode)\n2 = Zustand Repeat Message (<-- Prepare Bus-Sleep Mode)\n4 = Zustand Normal Operation (<-- Repeat Message)\n8 = Zustand Normal Operation (<-- Ready Sleep)";
CM_ SG_ 2600468595 NM_Info_El_UDS_CC "Funktionseinschrï?½nkung aufgrund aktivem UDS-Communication Control, siehe VW80124";
CM_ SG_ 2600468500 NM_Kombi_CAB_V15 "CAB = Clusteraktivbits (V15)";
CM_ SG_ 2600468500 NM_Kombi_Car_Wakeup "Car Wakeup (Gateway wertet aus)\nMQB: Timer abgelaufen, Zeitverstellung manuell oder automatisch (>5Min) beim aktiven Timer, Verlassenswarnung\n\nMLBevo: Timer abgelaufen, Zeitverstellung manuell oder automatisch (>5Min) beim aktiven Timer\nBerechnung Tan";
CM_ SG_ 2600468500 NM_Kombi_CBV_AWB "Das Signal ist zu setzen, wenn das SG aktiv den Bus geweckt hat";
CM_ SG_ 2600468500 NM_Kombi_CBV_CRI "Das Signal ist dauerhaft gesetzt, wenn das NM-Layout dem neuen NM-Layout fï?½r Teilnetzbetrieb entspricht";
CM_ SG_ 2600468500 NM_Kombi_NM_aktiv_Buzzer "Buzzer Weckereignis aktiv (1 Minute)";
CM_ SG_ 2600468500 NM_Kombi_NM_aktiv_Diagnose "Diagnose befindet sich nach VW80124 in einer NonDefaultDiagnostic-Session, z.B. ExtendedDiagnostic-Session";
CM_ SG_ 2600468500 NM_Kombi_NM_aktiv_KL15 "Steuergerï?½t hat KL15-EIN erkannt";
CM_ SG_ 2600468500 NM_Kombi_NM_aktiv_Schluesselkomm "Schlï?½sselkommunikation aktiv (WFS)";
CM_ SG_ 2600468500 NM_Kombi_NM_aktiv_Tmin "Mindestaktivzeit ist noch nicht abgelaufen (bei jedem Weckereignis wird die Mindestaktivzeit neu gestartet)";
CM_ SG_ 2600468500 NM_Kombi_NM_aktiv_VLW "Nachlaufursache des CAN. Es findet ein CAN Nachlauf fï?½r Dauer von max 5 Min statt, sofern Auslï?½sebedingungen fï?½r die Verlassenswarnung (VLW) erfï?½llt sind. Die VLW ist im Kombi umgesetzt. Auslï?½sebedingungen der VLW sind:\n- Fahrzeugstillstand (v < 3km/h)\n";
CM_ SG_ 2600468500 NM_Kombi_NM_State "1 = Zustand Repeat Message (<-- Bus-Sleep Mode)\n2 = Zustand Repeat Message (<-- Prepare Bus-Sleep Mode)\n4 = Zustand Normal Operation (<-- Repeat Message)\n8 = Zustand Normal Operation (<-- Ready Sleep)";
CM_ SG_ 2600468500 NM_Kombi_UDS_CC "Funktionseinschrï?½nkung aufgrund aktivem UDS-Communication Control; siehe VW80124";
CM_ SG_ 2600468748 NM_SmLi_01_CAB_V15 "CAB = Clusteraktivbits (V15)";
CM_ SG_ 2600468748 NM_SmLi_01_CarWakeup "Car Wakeup (Gateway wertet aus)";
CM_ SG_ 2600468748 NM_SmLi_01_CBV_AWB "Das Signal ist zu setzen, wenn das SG aktiv den Bus geweckt hat";
CM_ SG_ 2600468748 NM_SmLi_01_CBV_CRI "Das Signal ist dauerhaft gesetzt, wenn das NM-Layout dem neuen NM-Layout fï?½r Teilnetzbetrieb entspricht";
CM_ SG_ 2600468748 NM_SmLi_01_NM_aktiv_Diagnose "Diagnose befindet sich nach VW80124 in einer NonDefaultDiagnostic-Session, z.B. ExtendedDiagnostic-Session";
CM_ SG_ 2600468748 NM_SmLi_01_NM_aktiv_KL15 "Steuergerï?½t hat KL15-EIN erkannt";
CM_ SG_ 2600468748 NM_SmLi_01_NM_aktiv_Tmin "Mindestaktivzeit ist noch nicht abgelaufen (bei jedem Weckereignis wird die Mindestaktivzeit neu gestartet)";
CM_ SG_ 2600468748 NM_SmLi_01_NM_State "1 = Zustand Repeat Message (<-- Bus-Sleep Mode)\n2 = Zustand Repeat Message (<-- Prepare Bus-Sleep Mode)\n4 = Zustand Normal Operation (<-- Repeat Message)\n8 = Zustand Normal Operation (<-- Ready Sleep)";
CM_ SG_ 2600468748 NM_SmLi_01_UDS_CC "Funktionseinschrï?½nkung aufgrund aktivem UDS-Communication Control; siehe VW80124";
CM_ SG_ 2621702665 OBDC_DispKBI_FS_Req_FD_Data "OnBoard Tester Diagnose Request DispKBI_FS";
CM_ SG_ 2621833737 OBDC_DispKBI_FS_Resp_FD_Data "OnBoard Tester Diagnose Response DispKBI_FS";
CM_ SG_ 2549940736 OBDC_Funktionaler_Req_All_Data "VDC funktionaler Request auf CANHS";
CM_ SG_ 2621506048 OBDC_Funktion_Req_All_FD_Data "OnBoard Tester funktionaler Diagnose Request ALL";
CM_ SG_ 2621440539 OBDC_HUD_Req_FD_Data "OnBoard Tester Diagnose Request HUD";
CM_ SG_ 2621571611 OBDC_HUD_Resp_FD_Data "OnBoard Tester Diagnose Response HUD";
CM_ SG_ 2621440532 OBDC_Kombi_Req_FD_Data "OnBoard Tester Diagnose ï?½ber ISO TP.";
CM_ SG_ 2621571604 OBDC_Kombi_Resp_FD_Data "OnBoard Tester Diagnose ï?½ber ISO TP.";
CM_ SG_ 2621702668 OBDC_SmLi_01_Req_FD_Data "OnBoard Tester Diagnose Request SmLi_01";
CM_ SG_ 2621833740 OBDC_SmLi_01_Resp_FD_Data "OnBoard Tester Diagnose Response SmLi_01";
CM_ SG_ 2549903374 OBDC_SSN_ABT_1_Req_Data "Request FID- zu NA- Kommunikation zw. OnboardDiagnoseClient und DK2F Sub-System-Knoten ABT_1";
CM_ SG_ 2550034446 OBDC_SSN_ABT_1_Resp_Data "Response FID- zu NA- Kommunikation zw. OnboardDiagnoseClient und DK2F Sub-System-Knoten ABT_1";
CM_ SG_ 2549875365 OBDC_WLC1_Req_Data "OBDC Strecke fï?½r WLC1 - Req Kanal";
CM_ SG_ 2550006437 OBDC_WLC1_Resp_Data "OBDC Strecke fï?½r WLC1 - Resp Kanal";
CM_ SG_ 2564502513 OBDx_allOBD_Req_Data "Generic Scan Tool funktionaler Diagnose Request ALL OBD";
CM_ SG_ 2589284094 Fahrerdisplay_Kombi_ORUData "'- diagnostic address LowByte=a / Highbyte=b (2 bytes)\n- HW-part no cde.fgh.ijk.lm   (11 bytes ASCII)\n- HW version no. nop  (3 bytes ACII)\n- SW version no. qrst (4 bytes ASCII)\n- IVD-P Value   (32 bytes) lowest byte = I1 / highest byte = I32";
CM_ SG_ 2589284094 Fahrerdisplay_Kombi_ORUDataIndex "Data index of the last 6 Bytes";
CM_ SG_ 2589284094 ORU_007E_BZ "4bit Botschaftszï?½hler, wird mit jeder Sendebotschaft inkrementiert";
CM_ SG_ 2589284094 ORU_007E_CRC "Fï?½r MLB:\nBerechnung siehe Lastenheft 'Kommunikationsabsicherung fï?½r FlexRay und CAN'\nAb MQB und MLBevo:\nBerechnung siehe Lastenheft 'End-to-End Kommunikationsabsicherung'\n\nEndwerte siehe Begleitdokument 'S-PDU Kennungsfolgen'";
CM_ SG_ 2589284095 HUD_ORUData "ORU information multiplexed\n- diagnostic address (2 bytes)\n- HW-part no   (11 bytes)\n- HW version no.   (3 bytes)\n- SW version no. (4 bytes)\n- IVD-P Value   (64 bytes)\n\nneed to be sent in combination with ORUDataIndex";
CM_ SG_ 2589284095 HUD_ORUDataIndex "Data index of the last 6 Bytes";
CM_ SG_ 2589284095 ORU_0082_BZ "4bit Botschaftszï?½hler, wird mit jeder Sendebotschaft inkrementiert";
CM_ SG_ 2589284095 ORU_0082_CRC "Fï?½r MLB:\nBerechnung siehe Lastenheft 'Kommunikationsabsicherung fï?½r FlexRay und CAN'\nAb MQB und MLBevo:\nBerechnung siehe Lastenheft 'End-to-End Kommunikationsabsicherung'\n\nEndwerte siehe Begleitdokument 'S-PDU Kennungsfolgen'";
CM_ SG_ 2589283656 ORU_DiagAddress "Diagnostic address of next ECU to be updated";
CM_ SG_ 2589283656 ORU_EM_Anfrage_Flashdauer "Anfrage an das Energiemanagement, ob ein konkretes Online Remote Update durchgefï?½hrt werden kann - Flashdauer in 10s.";
CM_ SG_ 2589283656 ORU_EM_Anfrage_freigegebeneNetze "Meldung der wï?½hrend eines konkreten Online Remote Updates freigegebenen Netze (12V, 48V, HV)";
CM_ SG_ 2589283656 ORU_EM_Anfrage_Stromaufnahme "Meldung der voraussichtlichen durchschnittlichen Stromaufnahme eines konkreten Online Remote Updates an das NVEM";
CM_ SG_ 2589283656 ORU_Inventory "Signal zur Anzeige, ob die Inventory Erstellung durch ORU aktiv ist.\n\n0 = Init\n1 = ORU Inventory Erstellung ist nicht aktiv\n2 = ORU Inventory Erstellung ist aktiv";
CM_ SG_ 2589283656 ORU_Status "Verteilung des internen ORU Zustandes";
CM_ SG_ 2589283656 ORU_Warnung "Wenn durch Stï?½rungen der Funktion Online Remote Update nicht sichergestellt ist, dass vor Kunde keine Funktionseinschrï?½nkungen auftreten, muss der Benutzer des Fahrzeugs entsprechend gewarnt werden.";
CM_ SG_ 2589283672 SOK_ORU_01_Signatur "Signatur im Rahmen der durch SOK geschï?½tzten Broadcast-Kommunikation\n\nGeschï?½tzte Funktion: ORU\nGeschï?½tzte Botschaft: ORU_01";
CM_ SG_ 2589284073 ORUG01_01_BZ "4bit Botschaftszï?½hler, wird mit jeder Sendebotschaft inkrementiert";
CM_ SG_ 2589284073 ORUG01_01_CRC "Fï?½r MLB:\nBerechnung siehe Lastenheft 'Kommunikationsabsicherung fï?½r FlexRay und CAN'\nAb MQB und MLBevo:\nBerechnung siehe Lastenheft 'End-to-End Kommunikationsabsicherung'\n\nEndwerte siehe Begleitdokument 'S-PDU Kennungsfolgen'";
CM_ SG_ 2589284073 ORUG1_Anforderung_HMS "Request to gain park status to HMS";
CM_ SG_ 2589284073 ORUG1_HVLock "Request to lock HV-System to be de-energized";
CM_ SG_ 2589284073 ORUG1_HVReleased "Combination of the two status fixation state of HV to be de-energized is active and no crash has occured.";
CM_ SG_ 2589284073 ORUG1_Parken_beibehalten_HMS "Request to keep park status to HMS";
CM_ SG_ 2589284073 ORUG1_TargetRelease "Diagnostic address of ECU released to be updated";
CM_ SG_ 2589284073 ORUG1_Warning "Suppress warning on HMI during ORU update";
CM_ SG_ 2589284074 ORUG02_01_BZ "4bit Botschaftszï?½hler, wird mit jeder Sendebotschaft inkrementiert";
CM_ SG_ 2589284074 ORUG02_01_CRC "Fï?½r MLB:\nBerechnung siehe Lastenheft 'Kommunikationsabsicherung fï?½r FlexRay und CAN'\nAb MQB und MLBevo:\nBerechnung siehe Lastenheft 'End-to-End Kommunikationsabsicherung'\n\nEndwerte siehe Begleitdokument 'S-PDU Kennungsfolgen'";
CM_ SG_ 2589284074 ORUG2_GuardInfo "Released           = no lock is active\nVehLocked         = vehicle lock is active\nHVVehLocked    = HV-System is locked";
CM_ SG_ 2589284074 ORUG2_GuardState "Idle            = ORU guards are in Idle state\nDataErr      = check of Metadata not succsessful\nCountErr    = no. of ECUs differs between data and vehicle\nCollecting = data collection from ECUs is incomplete\nHwVerErr  = wrong HW version found\nWaiting";
CM_ SG_ 2589284074 ORUG2_TargetRelease "Diagnostic address of ECU released to be updated";
CM_ SG_ 2589284074 ORUG2_TorqueLock "Request HV system to prevent bringing torque on the EMotor";
BA_DEF_ BO_ "CANFD_BRS" ENUM "0", "1";
BA_DEF_ BO_ "DiagRequest" ENUM "No", "Yes";
BA_DEF_ BO_ "DiagResponse" ENUM "No", "Yes";
BA_DEF_ BO_ "DiagState" ENUM "No", "Yes";
BA_DEF_ BO_ "GenMsgChkConstant" HEX 0 4095;
BA_DEF_ BO_ "GenMsgCycleTime" INT 0 65535;
BA_DEF_ BO_ "GenMsgCycleTimeFast" INT 0 65535;
BA_DEF_ BO_ "GenMsgDelayTime" INT 0 100000;
BA_DEF_ BO_ "GenMsgILSupport" ENUM "No", "Yes";
BA_DEF_ BO_ "GenMsgNrOfRepetition" INT 0 100;
BA_DEF_ BO_ "GenMsgPDUConstants" STRING;
BA_DEF_ BO_ "GenMsgSendType" ENUM "Cyclic", "not_used", "not_used", "not_used", "not_used", "not_used", "not_used", "IfActive", "NoMsgSendType";
BA_DEF_ BO_ "GenMsgStartDelayTime" INT 0 100000;
BA_DEF_ BO_ "MsgType" ENUM "Application", "NM ", "NMH", "TP2.0", "ISO-TP ", "BAP", "EID", "KS", "XCP_PRE_CONFIGURED", "XCP_RUNTIME_CONFIGURED";
BA_DEF_ BO_ "NmMessage" ENUM "No", "Yes";
BA_DEF_ BO_ "NmhMessage" ENUM "No", "Yes";
BA_DEF_ BO_ "VAGTP20_API" HEX 0 255;
BA_DEF_ BO_ "VAGTP20_DynConnection" ENUM "No", "Yes";
BA_DEF_ BO_ "VAGTP20_DynSetup" ENUM "No", "Yes";
BA_DEF_ BO_ "VAGTP20_StatConnection" ENUM "No", "Yes";
BA_DEF_ BO_ "VFrameFormat" ENUM "StandardCAN", "ExtendedCAN", "reserved", "reserved", "reserved", "reserved", "reserved", "reserved", "reserved", "reserved", "reserved", "reserved", "reserved", "reserved", "StandardCAN_FD", "ExtendedCAN_FD";
BA_DEF_ SG_ "Fehlerwert" HEX 0 2147483647;
BA_DEF_ SG_ "GenSigActiveRepetitions" INT -2147483648 2147483647;
BA_DEF_ SG_ "GenSigFuncType" ENUM "NoFunction", "MsgCounter", "CRC-8", "XOR", "XOR-2", "DatedBit", "SW-Kl15", "CHK", "Constant", "Protocol", "CRC-8-SAE_J1850", "CRC-32", "DataLength", "DataID", "MsgCounter16", "SOK-Signatur", "Cluster";
BA_DEF_ SG_ "GenSigInactiveValue" INT -2147483648 2147483647;
BA_DEF_ SG_ "GenSigMissingSourceValue" HEX 0 2147483647;
BA_DEF_ SG_ "GenSigSendType" ENUM "Cyclic", "OnWrite", "OnWriteWithRepetition", "OnChange", "OnChangeWithRepetition", "IfActive", "IfActiveWithRepetition", "NoSigSendType", "OnChangeAndIfActive", "OnChangeAndIfActiveWithRepetition";
BA_DEF_ SG_ "GenSigStartValue" INT -2147483648 2147483647;
BA_DEF_ SG_ "GenSigSwitchedByIgnition" ENUM "No", "Yes";
BA_DEF_ SG_ "NWM-WakeupAllowed" ENUM "No", "Yes";

BA_DEF_REL_ BU_SG_REL_ "GenSigTimeoutTime" INT 0 65535;
BA_DEF_DEF_ "CANFD_BRS" "1";
BA_DEF_DEF_ "DiagRequest" "No";
BA_DEF_DEF_ "DiagResponse" "No";
BA_DEF_DEF_ "DiagState" "No";
BA_DEF_DEF_ "Fehlerwert" 0;
BA_DEF_DEF_ "GenMsgChkConstant" 0;
BA_DEF_DEF_ "GenMsgCycleTime" 0;
BA_DEF_DEF_ "GenMsgCycleTimeFast" 0;
BA_DEF_DEF_ "GenMsgDelayTime" 0;
BA_DEF_DEF_ "GenMsgILSupport" "No";
BA_DEF_DEF_ "GenMsgNrOfRepetition" 0;
BA_DEF_DEF_ "GenMsgPDUConstants" "";
BA_DEF_DEF_ "GenMsgSendType" "NoMsgSendType";
BA_DEF_DEF_ "GenMsgStartDelayTime" 0;
BA_DEF_DEF_ "GenSigActiveRepetitions" 0;
BA_DEF_DEF_ "GenSigFuncType" "NoFunction";
BA_DEF_DEF_ "GenSigInactiveValue" 0;
BA_DEF_DEF_ "GenSigMissingSourceValue" 0;
BA_DEF_DEF_ "GenSigSendType" "NoSigSendType";
BA_DEF_DEF_ "GenSigStartValue" 0;
BA_DEF_DEF_ "GenSigSwitchedByIgnition" "Yes";
BA_DEF_DEF_ "MsgType" "Application";
BA_DEF_DEF_ "NWM-WakeupAllowed" "No";
BA_DEF_DEF_ "NmMessage" "No";
BA_DEF_DEF_ "NmhMessage" "No";
BA_DEF_DEF_ "VAGTP20_API" 0;
BA_DEF_DEF_ "VAGTP20_DynConnection" "No";
BA_DEF_DEF_ "VAGTP20_DynSetup" "No";
BA_DEF_DEF_ "VAGTP20_StatConnection" "No";
BA_DEF_DEF_ "VFrameFormat" "StandardCAN";
BA_DEF_DEF_REL_ "GenSigTimeoutTime" 0;
BA_ "GenMsgCycleTime" BO_ 512 50;
BA_ "GenMsgILSupport" BO_ 512 1;
BA_ "GenMsgSendType" BO_ 512 0;
BA_ "VFrameFormat" BO_ 512 14;
BA_ "GenMsgCycleTime" BO_ 332 100;
BA_ "GenMsgDelayTime" BO_ 332 10;
BA_ "GenMsgILSupport" BO_ 332 1;
BA_ "GenMsgPDUConstants" BO_ 332 "0x16,0x35,0x59,0x15,0x9a,0x2a,0x97,0xb8,0x0e,0x4e,0x30,0xcc,0xb3,0x07,0x01,0xad";
BA_ "GenMsgSendType" BO_ 332 0;
BA_ "VFrameFormat" BO_ 332 14;
BA_ "GenMsgCycleTime" BO_ 2463978666 100;
BA_ "GenMsgILSupport" BO_ 2463978666 1;
BA_ "GenMsgPDUConstants" BO_ 2463978666 "0x4a,0x1b,0x16,0x0a,0x24,0x35,0xf8,0x1f,0x59,0x60,0x3b,0x15,0xaa,0xe5,0x9a,0x2e";
BA_ "GenMsgSendType" BO_ 2463978666 0;
BA_ "VFrameFormat" BO_ 2463978666 15;
BA_ "GenMsgCycleTime" BO_ 2331595982 50;
BA_ "GenMsgILSupport" BO_ 2331595982 1;
BA_ "GenMsgSendType" BO_ 2331595982 0;
BA_ "VFrameFormat" BO_ 2331595982 15;
BA_ "GenMsgCycleTime" BO_ 2589283946 500;
BA_ "GenMsgILSupport" BO_ 2589283946 1;
BA_ "GenMsgSendType" BO_ 2589283946 0;
BA_ "VFrameFormat" BO_ 2589283946 15;
BA_ "GenMsgCycleTime" BO_ 1155 500;
BA_ "GenMsgDelayTime" BO_ 1155 50;
BA_ "GenMsgILSupport" BO_ 1155 1;
BA_ "GenMsgSendType" BO_ 1155 0;
BA_ "VFrameFormat" BO_ 1155 14;
BA_ "GenMsgCycleTime" BO_ 1156 200;
BA_ "GenMsgILSupport" BO_ 1156 1;
BA_ "GenMsgSendType" BO_ 1156 0;
BA_ "VFrameFormat" BO_ 1156 14;
BA_ "GenMsgCycleTime" BO_ 1157 200;
BA_ "GenMsgILSupport" BO_ 1157 1;
BA_ "GenMsgSendType" BO_ 1157 0;
BA_ "VFrameFormat" BO_ 1157 14;
BA_ "GenMsgCycleTime" BO_ 2527679512 200;
BA_ "GenMsgILSupport" BO_ 2527679512 1;
BA_ "GenMsgSendType" BO_ 2527679512 0;
BA_ "GenMsgStartDelayTime" BO_ 2527679512 60;
BA_ "VFrameFormat" BO_ 2527679512 15;
BA_ "GenMsgCycleTime" BO_ 2527679665 200;
BA_ "GenMsgILSupport" BO_ 2527679665 1;
BA_ "GenMsgSendType" BO_ 2527679665 0;
BA_ "VFrameFormat" BO_ 2527679665 15;
BA_ "GenMsgCycleTime" BO_ 1158 200;
BA_ "GenMsgILSupport" BO_ 1158 1;
BA_ "GenMsgSendType" BO_ 1158 0;
BA_ "VFrameFormat" BO_ 1158 14;
BA_ "GenMsgCycleTime" BO_ 2589283496 500;
BA_ "GenMsgILSupport" BO_ 2589283496 1;
BA_ "GenMsgSendType" BO_ 2589283496 0;
BA_ "VFrameFormat" BO_ 2589283496 15;
BA_ "GenMsgCycleTime" BO_ 2527679647 200;
BA_ "GenMsgDelayTime" BO_ 2527679647 10;
BA_ "GenMsgILSupport" BO_ 2527679647 1;
BA_ "GenMsgSendType" BO_ 2527679647 0;
BA_ "VFrameFormat" BO_ 2527679647 15;
BA_ "GenMsgCycleTime" BO_ 2527679645 200;
BA_ "GenMsgILSupport" BO_ 2527679645 1;
BA_ "GenMsgSendType" BO_ 2527679645 0;
BA_ "VFrameFormat" BO_ 2527679645 15;
BA_ "GenMsgCycleTime" BO_ 2600468745 200;
BA_ "GenMsgCycleTimeFast" BO_ 2600468745 10;
BA_ "MsgType" BO_ 2600468745 2;
BA_ "NmhMessage" BO_ 2600468745 1;
BA_ "VFrameFormat" BO_ 2600468745 15;
BA_ "GenMsgCycleTime" BO_ 2600468496 200;
BA_ "GenMsgCycleTimeFast" BO_ 2600468496 10;
BA_ "MsgType" BO_ 2600468496 2;
BA_ "NmhMessage" BO_ 2600468496 1;
BA_ "VFrameFormat" BO_ 2600468496 15;
BA_ "GenMsgCycleTime" BO_ 2600468507 200;
BA_ "GenMsgCycleTimeFast" BO_ 2600468507 10;
BA_ "MsgType" BO_ 2600468507 2;
BA_ "NmhMessage" BO_ 2600468507 1;
BA_ "VFrameFormat" BO_ 2600468507 15;
BA_ "GenMsgCycleTime" BO_ 2600468595 200;
BA_ "GenMsgCycleTimeFast" BO_ 2600468595 10;
BA_ "MsgType" BO_ 2600468595 2;
BA_ "NmhMessage" BO_ 2600468595 1;
BA_ "VFrameFormat" BO_ 2600468595 15;
BA_ "GenMsgCycleTime" BO_ 2600468500 200;
BA_ "GenMsgCycleTimeFast" BO_ 2600468500 10;
BA_ "MsgType" BO_ 2600468500 2;
BA_ "NmhMessage" BO_ 2600468500 1;
BA_ "VFrameFormat" BO_ 2600468500 15;
BA_ "GenMsgCycleTime" BO_ 2600468748 200;
BA_ "GenMsgCycleTimeFast" BO_ 2600468748 10;
BA_ "MsgType" BO_ 2600468748 2;
BA_ "NmhMessage" BO_ 2600468748 1;
BA_ "VFrameFormat" BO_ 2600468748 15;
BA_ "DiagRequest" BO_ 2621702665 1;
BA_ "MsgType" BO_ 2621702665 4;
BA_ "VFrameFormat" BO_ 2621702665 15;
BA_ "DiagResponse" BO_ 2621833737 1;
BA_ "MsgType" BO_ 2621833737 4;
BA_ "VFrameFormat" BO_ 2621833737 15;
BA_ "DiagState" BO_ 2549940736 1;
BA_ "MsgType" BO_ 2549940736 4;
BA_ "VFrameFormat" BO_ 2549940736 15;
BA_ "DiagState" BO_ 2621506048 1;
BA_ "MsgType" BO_ 2621506048 4;
BA_ "VFrameFormat" BO_ 2621506048 15;
BA_ "DiagRequest" BO_ 2621440539 1;
BA_ "MsgType" BO_ 2621440539 4;
BA_ "VFrameFormat" BO_ 2621440539 15;
BA_ "DiagResponse" BO_ 2621571611 1;
BA_ "MsgType" BO_ 2621571611 4;
BA_ "VFrameFormat" BO_ 2621571611 15;
BA_ "DiagRequest" BO_ 2621440532 1;
BA_ "MsgType" BO_ 2621440532 4;
BA_ "VFrameFormat" BO_ 2621440532 15;
BA_ "DiagResponse" BO_ 2621571604 1;
BA_ "MsgType" BO_ 2621571604 4;
BA_ "VFrameFormat" BO_ 2621571604 15;
BA_ "DiagRequest" BO_ 2621702668 1;
BA_ "MsgType" BO_ 2621702668 4;
BA_ "VFrameFormat" BO_ 2621702668 15;
BA_ "DiagResponse" BO_ 2621833740 1;
BA_ "MsgType" BO_ 2621833740 4;
BA_ "VFrameFormat" BO_ 2621833740 15;
BA_ "DiagRequest" BO_ 2549903374 1;
BA_ "MsgType" BO_ 2549903374 4;
BA_ "VFrameFormat" BO_ 2549903374 15;
BA_ "DiagResponse" BO_ 2550034446 1;
BA_ "MsgType" BO_ 2550034446 4;
BA_ "VFrameFormat" BO_ 2550034446 15;
BA_ "DiagRequest" BO_ 2549875309 1;
BA_ "MsgType" BO_ 2549875309 4;
BA_ "VFrameFormat" BO_ 2549875309 15;
BA_ "DiagResponse" BO_ 2550006381 1;
BA_ "MsgType" BO_ 2550006381 4;
BA_ "VFrameFormat" BO_ 2550006381 15;
BA_ "DiagRequest" BO_ 2549875365 1;
BA_ "MsgType" BO_ 2549875365 4;
BA_ "VFrameFormat" BO_ 2549875365 15;
BA_ "DiagResponse" BO_ 2550006437 1;
BA_ "MsgType" BO_ 2550006437 4;
BA_ "VFrameFormat" BO_ 2550006437 15;
BA_ "DiagState" BO_ 2564502513 1;
BA_ "MsgType" BO_ 2564502513 4;
BA_ "VFrameFormat" BO_ 2564502513 15;
BA_ "GenMsgCycleTime" BO_ 2589284094 500;
BA_ "GenMsgILSupport" BO_ 2589284094 1;
BA_ "GenMsgPDUConstants" BO_ 2589284094 "0xac,0xfb,0xc0,0xbc,0x22,0xed,0x09,0x2c,0x28,0xda,0x04,0x67,0xd2,0xd6,0xbe,0xd8";
BA_ "GenMsgSendType" BO_ 2589284094 0;
BA_ "VFrameFormat" BO_ 2589284094 15;
BA_ "GenMsgCycleTime" BO_ 2589284095 500;
BA_ "GenMsgILSupport" BO_ 2589284095 1;
BA_ "GenMsgPDUConstants" BO_ 2589284095 "0x26,0x34,0x94,0x36,0xee,0x5c,0x23,0x15,0x01,0xeb,0x17,0x87,0xf3,0x70,0x57,0xa5";
BA_ "GenMsgSendType" BO_ 2589284095 0;
BA_ "VFrameFormat" BO_ 2589284095 15;
BA_ "GenMsgCycleTime" BO_ 2589283656 500;
BA_ "GenMsgDelayTime" BO_ 2589283656 100;
BA_ "GenMsgILSupport" BO_ 2589283656 1;
BA_ "GenMsgPDUConstants" BO_ 2589283656 "0xee,0xcc,0x2f,0x27,0x93,0x0c,0x45,0x97,0x87,0x2e,0xec,0x3b,0xd3,0x35,0xcb,0x4a";
BA_ "GenMsgSendType" BO_ 2589283656 0;
BA_ "VFrameFormat" BO_ 2589283656 15;
BA_ "GenMsgCycleTime" BO_ 2589283672 500;
BA_ "GenMsgDelayTime" BO_ 2589283672 100;
BA_ "GenMsgILSupport" BO_ 2589283672 1;
BA_ "GenMsgSendType" BO_ 2589283672 0;
BA_ "VFrameFormat" BO_ 2589283672 15;
BA_ "GenMsgCycleTime" BO_ 2589284073 500;
BA_ "GenMsgILSupport" BO_ 2589284073 1;
BA_ "GenMsgPDUConstants" BO_ 2589284073 "0xdf,0xa2,0xc0,0x44,0x96,0xbf,0x81,0x49,0x65,0xe4,0x1a,0xd1,0xf4,0x10,0xaa,0xac";
BA_ "GenMsgSendType" BO_ 2589284073 0;
BA_ "VFrameFormat" BO_ 2589284073 15;
BA_ "GenMsgCycleTime" BO_ 2589284074 500;
BA_ "GenMsgILSupport" BO_ 2589284074 1;
BA_ "GenMsgPDUConstants" BO_ 2589284074 "0x20,0x60,0x3f,0x23,0x7c,0x96,0x28,0x42,0x0e,0x79,0x90,0xe4,0x40,0xb1,0xce,0x18";
BA_ "GenMsgSendType" BO_ 2589284074 0;
BA_ "VFrameFormat" BO_ 2589284074 15;
BA_ "GenSigSendType" SG_ 512 ISA_Tempolimit_Regelung 0;
BA_ "GenSigSwitchedByIgnition" SG_ 512 ISA_Tempolimit_Regelung 0;
BA_ "GenSigSendType" SG_ 512 MO_Antriebsstrang_Warnung_HS 0;
BA_ "GenSigSwitchedByIgnition" SG_ 512 MO_Antriebsstrang_Warnung_HS 0;
BA_ "GenSigSendType" SG_ 512 MO_Anzeige_Betriebsmodus 0;
BA_ "GenSigSwitchedByIgnition" SG_ 512 MO_Anzeige_Betriebsmodus 0;
BA_ "GenSigSendType" SG_ 512 MO_Anzeige_Fahrbereitschaft 0;
BA_ "GenSigSwitchedByIgnition" SG_ 512 MO_Anzeige_Fahrbereitschaft 0;
BA_ "GenSigSendType" SG_ 512 MO_Anzeige_Rekuperation 0;
BA_ "GenSigSwitchedByIgnition" SG_ 512 MO_Anzeige_Rekuperation 0;
BA_ "GenSigSendType" SG_ 512 MO_Anzeige_Verbrauch_oE 0;
BA_ "GenSigSwitchedByIgnition" SG_ 512 MO_Anzeige_Verbrauch_oE 0;
BA_ "GenSigSendType" SG_ 512 MO_Boost_aktiv 0;
BA_ "GenSigSwitchedByIgnition" SG_ 512 MO_Boost_aktiv 0;
BA_ "Fehlerwert" SG_ 512 MO_Boost_verfuegbar 255;
BA_ "GenSigSendType" SG_ 512 MO_Boost_verfuegbar 0;
BA_ "GenSigSwitchedByIgnition" SG_ 512 MO_Boost_verfuegbar 0;
BA_ "GenSigSendType" SG_ 512 MO_BZS_Charisma_FahrPr 0;
BA_ "GenSigSwitchedByIgnition" SG_ 512 MO_BZS_Charisma_FahrPr 0;
BA_ "GenSigSendType" SG_ 512 MO_BZS_Charisma_Status 0;
BA_ "GenSigSwitchedByIgnition" SG_ 512 MO_BZS_Charisma_Status 0;
BA_ "GenSigSendType" SG_ 512 MO_Charisma_FahrPr 0;
BA_ "GenSigSwitchedByIgnition" SG_ 512 MO_Charisma_FahrPr 0;
BA_ "GenSigSendType" SG_ 512 MO_Charisma_Status 0;
BA_ "GenSigSwitchedByIgnition" SG_ 512 MO_Charisma_Status 0;
BA_ "GenSigSendType" SG_ 512 MO_Drehzahlbeeinflussung 0;
BA_ "GenSigSwitchedByIgnition" SG_ 512 MO_Drehzahlbeeinflussung 0;
BA_ "GenSigSendType" SG_ 512 MO_Luftpfad_aktiv 0;
BA_ "GenSigSwitchedByIgnition" SG_ 512 MO_Luftpfad_aktiv 0;
BA_ "GenSigSendType" SG_ 512 MO_MAX_Wunschdrehzahl 0;
BA_ "GenSigSwitchedByIgnition" SG_ 512 MO_MAX_Wunschdrehzahl 0;
BA_ "GenSigSendType" SG_ 512 MO_MIN_Wunschdrehzahl 0;
BA_ "GenSigSwitchedByIgnition" SG_ 512 MO_MIN_Wunschdrehzahl 0;
BA_ "GenSigSendType" SG_ 512 MO_Motorlaufwarnung 0;
BA_ "GenSigSwitchedByIgnition" SG_ 512 MO_Motorlaufwarnung 0;
BA_ "GenSigSendType" SG_ 512 MO_NGS_Position 0;
BA_ "GenSigSwitchedByIgnition" SG_ 512 MO_NGS_Position 0;
BA_ "Fehlerwert" SG_ 512 MO_NGS_Status 3;
BA_ "GenSigSendType" SG_ 512 MO_NGS_Status 0;
BA_ "GenSigSwitchedByIgnition" SG_ 512 MO_NGS_Status 0;
BA_ "GenSigSendType" SG_ 512 MO_Overboost 0;
BA_ "GenSigSwitchedByIgnition" SG_ 512 MO_Overboost 0;
BA_ "GenSigSendType" SG_ 512 MO_Prio_MAX_Wunschdrehzahl 0;
BA_ "GenSigSwitchedByIgnition" SG_ 512 MO_Prio_MAX_Wunschdrehzahl 0;
BA_ "GenSigSendType" SG_ 512 MO_Prio_MIN_Wunschdrehzahl 0;
BA_ "GenSigSwitchedByIgnition" SG_ 512 MO_Prio_MIN_Wunschdrehzahl 0;
BA_ "GenSigSendType" SG_ 512 MO_Rampenzeit_Generator_Anf 0;
BA_ "GenSigStartValue" SG_ 512 MO_Rampenzeit_Generator_Anf 15;
BA_ "GenSigSwitchedByIgnition" SG_ 512 MO_Rampenzeit_Generator_Anf 0;
BA_ "GenSigSendType" SG_ 512 MO_Sperrung_FahrPr_BZS 0;
BA_ "GenSigSwitchedByIgnition" SG_ 512 MO_Sperrung_FahrPr_BZS 0;
BA_ "GenSigSendType" SG_ 512 MO_StSt_Charisma_FahrPr 0;
BA_ "GenSigSwitchedByIgnition" SG_ 512 MO_StSt_Charisma_FahrPr 0;
BA_ "GenSigSendType" SG_ 512 MO_StSt_Charisma_Status 0;
BA_ "GenSigSwitchedByIgnition" SG_ 512 MO_StSt_Charisma_Status 0;
BA_ "GenSigSendType" SG_ 512 MO_Text_Aktivierung_Antrieb 0;
BA_ "GenSigStartValue" SG_ 512 MO_Text_Aktivierung_Antrieb 15;
BA_ "GenSigSwitchedByIgnition" SG_ 512 MO_Text_Aktivierung_Antrieb 0;
BA_ "GenSigSendType" SG_ 512 MO_v_Begrenz_Aktivierbar 0;
BA_ "GenSigSwitchedByIgnition" SG_ 512 MO_v_Begrenz_Aktivierbar 0;
BA_ "GenSigSendType" SG_ 512 MO_v_Begrenzung_Niveau 0;
BA_ "GenSigSwitchedByIgnition" SG_ 512 MO_v_Begrenzung_Niveau 0;
BA_ "GenSigSendType" SG_ 512 PEA_Abschalttexte 0;
BA_ "GenSigSwitchedByIgnition" SG_ 512 PEA_Abschalttexte 0;
BA_ "GenSigSendType" SG_ 512 PEA_Ereignisanzeige 0;
BA_ "GenSigSwitchedByIgnition" SG_ 512 PEA_Ereignisanzeige 0;
BA_ "GenSigSendType" SG_ 512 PEA_Ereignisanzeige_temporaer 0;
BA_ "GenSigSwitchedByIgnition" SG_ 512 PEA_Ereignisanzeige_temporaer 0;
BA_ "GenSigSendType" SG_ 512 PEA_Fahrerinfo 0;
BA_ "GenSigSwitchedByIgnition" SG_ 512 PEA_Fahrerinfo 0;
BA_ "GenSigSendType" SG_ 512 PEA_Fortschrittsanzeige 0;
BA_ "GenSigStartValue" SG_ 512 PEA_Fortschrittsanzeige 127;
BA_ "GenSigSwitchedByIgnition" SG_ 512 PEA_Fortschrittsanzeige 0;
BA_ "GenSigSendType" SG_ 512 PEA_Hinweis 0;
BA_ "GenSigSwitchedByIgnition" SG_ 512 PEA_Hinweis 0;
BA_ "GenSigSendType" SG_ 512 PEA_Zielgeschw 0;
BA_ "GenSigSwitchedByIgnition" SG_ 512 PEA_Zielgeschw 0;
BA_ "GenSigSendType" SG_ 512 PEA_Zielgeschw_Einheit 0;
BA_ "GenSigSwitchedByIgnition" SG_ 512 PEA_Zielgeschw_Einheit 0;
BA_ "GenSigSendType" SG_ 512 TSK_Akustik 0;
BA_ "GenSigSwitchedByIgnition" SG_ 512 TSK_Akustik 0;
BA_ "GenSigSendType" SG_ 512 TSK_Fahrzeugstatus_GRA 0;
BA_ "GenSigSwitchedByIgnition" SG_ 512 TSK_Fahrzeugstatus_GRA 0;
BA_ "GenSigSendType" SG_ 512 TSK_Fahrzeugstatus_Limiter 0;
BA_ "GenSigSwitchedByIgnition" SG_ 512 TSK_Fahrzeugstatus_Limiter 0;
BA_ "GenSigSendType" SG_ 512 TSK_Fahrzeugstatus_praed_Fkt 0;
BA_ "GenSigSwitchedByIgnition" SG_ 512 TSK_Fahrzeugstatus_praed_Fkt 0;
BA_ "GenSigSendType" SG_ 512 TSK_Limiter_Anzeige 0;
BA_ "GenSigSwitchedByIgnition" SG_ 512 TSK_Limiter_Anzeige 0;
BA_ "GenSigSendType" SG_ 512 TSK_Limiter_Fahrerinfo 0;
BA_ "GenSigSwitchedByIgnition" SG_ 512 TSK_Limiter_Fahrerinfo 0;
BA_ "GenSigSendType" SG_ 512 TSK_naechstes_Event 0;
BA_ "GenSigSwitchedByIgnition" SG_ 512 TSK_naechstes_Event 0;
BA_ "GenSigSendType" SG_ 512 TSK_naechstes_Event_Einheit 0;
BA_ "GenSigSwitchedByIgnition" SG_ 512 TSK_naechstes_Event_Einheit 0;
BA_ "GenSigSendType" SG_ 512 TSK_praed_Wunschgeschw 0;
BA_ "GenSigStartValue" SG_ 512 TSK_praed_Wunschgeschw 1022;
BA_ "GenSigSwitchedByIgnition" SG_ 512 TSK_praed_Wunschgeschw 0;
BA_ "GenSigSendType" SG_ 512 TSK_praediktiver_Automode 0;
BA_ "GenSigSwitchedByIgnition" SG_ 512 TSK_praediktiver_Automode 0;
BA_ "GenSigSendType" SG_ 512 TSK_praediktiver_Hinweis 0;
BA_ "GenSigSwitchedByIgnition" SG_ 512 TSK_praediktiver_Hinweis 0;
BA_ "GenSigSendType" SG_ 512 TSK_Status_Anzeige 0;
BA_ "GenSigStartValue" SG_ 512 TSK_Status_Anzeige 1;
BA_ "GenSigSwitchedByIgnition" SG_ 512 TSK_Status_Anzeige 0;
BA_ "GenSigSendType" SG_ 512 TSK_Texte 0;
BA_ "GenSigSwitchedByIgnition" SG_ 512 TSK_Texte 0;
BA_ "GenSigSendType" SG_ 512 TSK_Texte_Primaeranz 0;
BA_ "GenSigSwitchedByIgnition" SG_ 512 TSK_Texte_Primaeranz 0;
BA_ "GenSigSendType" SG_ 512 TSK_Wunschgeschw 0;
BA_ "GenSigSwitchedByIgnition" SG_ 512 TSK_Wunschgeschw 0;
BA_ "GenSigSendType" SG_ 332 FoD_DTC_TSK_ACC 0;
BA_ "GenSigSwitchedByIgnition" SG_ 332 FoD_DTC_TSK_ACC 0;
BA_ "GenSigSendType" SG_ 332 FoD_DTC_TSK_GRA 0;
BA_ "GenSigSwitchedByIgnition" SG_ 332 FoD_DTC_TSK_GRA 0;
BA_ "GenSigSendType" SG_ 332 ISA_Regelung_aktiv 3;
BA_ "GenSigSwitchedByIgnition" SG_ 332 ISA_Regelung_aktiv 0;
BA_ "GenSigSendType" SG_ 332 ISA_Status 3;
BA_ "GenSigStartValue" SG_ 332 ISA_Status 1;
BA_ "GenSigSwitchedByIgnition" SG_ 332 ISA_Status 0;
BA_ "GenSigSendType" SG_ 332 ISA_Tempolimitwarnung 3;
BA_ "GenSigSwitchedByIgnition" SG_ 332 ISA_Tempolimitwarnung 0;
BA_ "Fehlerwert" SG_ 332 KVA_Ist_Pos 127;
BA_ "GenSigSendType" SG_ 332 KVA_Ist_Pos 0;
BA_ "GenSigStartValue" SG_ 332 KVA_Ist_Pos 126;
BA_ "GenSigSwitchedByIgnition" SG_ 332 KVA_Ist_Pos 0;
BA_ "GenSigSendType" SG_ 332 MO_Anforderung_Anzeige_Halten 3;
BA_ "GenSigSwitchedByIgnition" SG_ 332 MO_Anforderung_Anzeige_Halten 0;
BA_ "GenSigSendType" SG_ 332 MO_Anforderung_HMS 3;
BA_ "GenSigSwitchedByIgnition" SG_ 332 MO_Anforderung_HMS 0;
BA_ "GenSigSendType" SG_ 332 MO_EBoost_verf_praed 0;
BA_ "GenSigSwitchedByIgnition" SG_ 332 MO_EBoost_verf_praed 0;
BA_ "GenSigSendType" SG_ 332 MO_eLaunch_verf 0;
BA_ "GenSigSwitchedByIgnition" SG_ 332 MO_eLaunch_verf 0;
BA_ "GenSigSendType" SG_ 332 MO_Fahrbereitschaft 3;
BA_ "GenSigSwitchedByIgnition" SG_ 332 MO_Fahrbereitschaft 0;
BA_ "GenSigSendType" SG_ 332 MO_Freilauf_Info 3;
BA_ "GenSigSwitchedByIgnition" SG_ 332 MO_Freilauf_Info 0;
BA_ "Fehlerwert" SG_ 332 MO_Freilauf_Status 7;
BA_ "GenSigSendType" SG_ 332 MO_Freilauf_Status 3;
BA_ "GenSigSwitchedByIgnition" SG_ 332 MO_Freilauf_Status 0;
BA_ "GenSigSendType" SG_ 332 MO_Heckspoiler_Anf 0;
BA_ "GenSigSwitchedByIgnition" SG_ 332 MO_Heckspoiler_Anf 0;
BA_ "GenSigSendType" SG_ 332 MO_Klima_Regelmodus 0;
BA_ "GenSigSwitchedByIgnition" SG_ 332 MO_Klima_Regelmodus 0;
BA_ "Fehlerwert" SG_ 332 MO_Krit_Heckobjekt 7;
BA_ "GenSigSendType" SG_ 332 MO_Krit_Heckobjekt 0;
BA_ "GenSigSwitchedByIgnition" SG_ 332 MO_Krit_Heckobjekt 0;
BA_ "GenSigSendType" SG_ 332 MO_LaunchControl 0;
BA_ "GenSigSwitchedByIgnition" SG_ 332 MO_LaunchControl 0;
BA_ "Fehlerwert" SG_ 332 MO_NGS_Gangpos 7;
BA_ "GenSigSendType" SG_ 332 MO_NGS_Gangpos 3;
BA_ "GenSigSwitchedByIgnition" SG_ 332 MO_NGS_Gangpos 0;
BA_ "Fehlerwert" SG_ 332 MO_OnePedal_Verzoegerungsstufe 7;
BA_ "GenSigSendType" SG_ 332 MO_OnePedal_Verzoegerungsstufe 3;
BA_ "GenSigSwitchedByIgnition" SG_ 332 MO_OnePedal_Verzoegerungsstufe 0;
BA_ "GenSigSendType" SG_ 332 MO_Positionierung_aktiv 0;
BA_ "GenSigSwitchedByIgnition" SG_ 332 MO_Positionierung_aktiv 0;
BA_ "GenSigSendType" SG_ 332 MO_QBit_Aussen_Temp 0;
BA_ "GenSigStartValue" SG_ 332 MO_QBit_Aussen_Temp 1;
BA_ "GenSigSwitchedByIgnition" SG_ 332 MO_QBit_Aussen_Temp 0;
BA_ "GenSigSendType" SG_ 332 MO_Red_El_Fahrleistung 0;
BA_ "GenSigSwitchedByIgnition" SG_ 332 MO_Red_El_Fahrleistung 0;
BA_ "GenSigSendType" SG_ 332 MO_Servicemodus 0;
BA_ "GenSigSwitchedByIgnition" SG_ 332 MO_Servicemodus 0;
BA_ "GenSigSendType" SG_ 332 MO_Startwunsch 3;
BA_ "GenSigSwitchedByIgnition" SG_ 332 MO_Startwunsch 0;
BA_ "GenSigSendType" SG_ 332 MO_UBE_Reserve 0;
BA_ "GenSigStartValue" SG_ 332 MO_UBE_Reserve 1023;
BA_ "GenSigSwitchedByIgnition" SG_ 332 MO_UBE_Reserve 0;
BA_ "GenSigFuncType" SG_ 332 Motor_54_BZ 1;
BA_ "GenSigSendType" SG_ 332 Motor_54_BZ 0;
BA_ "GenSigSwitchedByIgnition" SG_ 332 Motor_54_BZ 0;
BA_ "GenSigFuncType" SG_ 332 Motor_54_CRC 2;
BA_ "GenSigSendType" SG_ 332 Motor_54_CRC 0;
BA_ "GenSigSwitchedByIgnition" SG_ 332 Motor_54_CRC 0;
BA_ "GenSigSendType" SG_ 332 OBD_Abs_Load_Val 0;
BA_ "GenSigStartValue" SG_ 332 OBD_Abs_Load_Val 65535;
BA_ "GenSigSwitchedByIgnition" SG_ 332 OBD_Abs_Load_Val 0;
BA_ "GenSigSendType" SG_ 332 OBD_Abs_Pedal_Pos 0;
BA_ "GenSigStartValue" SG_ 332 OBD_Abs_Pedal_Pos 255;
BA_ "GenSigSwitchedByIgnition" SG_ 332 OBD_Abs_Pedal_Pos 0;
BA_ "GenSigSendType" SG_ 332 OBD_Abs_Throttle_Pos 0;
BA_ "GenSigStartValue" SG_ 332 OBD_Abs_Throttle_Pos 255;
BA_ "GenSigSwitchedByIgnition" SG_ 332 OBD_Abs_Throttle_Pos 0;
BA_ "Fehlerwert" SG_ 332 OBD_Aussen_Temp_gef 255;
BA_ "GenSigSendType" SG_ 332 OBD_Aussen_Temp_gef 0;
BA_ "GenSigStartValue" SG_ 332 OBD_Aussen_Temp_gef 254;
BA_ "GenSigSwitchedByIgnition" SG_ 332 OBD_Aussen_Temp_gef 0;
BA_ "GenSigSendType" SG_ 332 OBD_Calc_Load_Val 0;
BA_ "GenSigStartValue" SG_ 332 OBD_Calc_Load_Val 255;
BA_ "GenSigSwitchedByIgnition" SG_ 332 OBD_Calc_Load_Val 0;
BA_ "GenSigSendType" SG_ 332 OBD_ClearMem_Inhibit 0;
BA_ "GenSigSwitchedByIgnition" SG_ 332 OBD_ClearMem_Inhibit 0;
BA_ "GenSigSendType" SG_ 332 OBD_Driving_Cycle 0;
BA_ "GenSigSwitchedByIgnition" SG_ 332 OBD_Driving_Cycle 0;
BA_ "GenSigSendType" SG_ 332 OBD_Eng_Cool_Temp 0;
BA_ "GenSigStartValue" SG_ 332 OBD_Eng_Cool_Temp 255;
BA_ "GenSigSwitchedByIgnition" SG_ 332 OBD_Eng_Cool_Temp 0;
BA_ "GenSigSendType" SG_ 332 OBD_Kaltstart_Denominator 0;
BA_ "GenSigSwitchedByIgnition" SG_ 332 OBD_Kaltstart_Denominator 0;
BA_ "GenSigSendType" SG_ 332 OBD_Minimum_Trip 0;
BA_ "GenSigSwitchedByIgnition" SG_ 332 OBD_Minimum_Trip 0;
BA_ "GenSigSendType" SG_ 332 OBD_Normed_Trip 0;
BA_ "GenSigSwitchedByIgnition" SG_ 332 OBD_Normed_Trip 0;
BA_ "GenSigSendType" SG_ 332 OBD_Sperrung_IUMPR 0;
BA_ "GenSigSwitchedByIgnition" SG_ 332 OBD_Sperrung_IUMPR 0;
BA_ "GenSigSendType" SG_ 332 OBD_Sperrung_Kaltstart_Denom 0;
BA_ "GenSigSwitchedByIgnition" SG_ 332 OBD_Sperrung_Kaltstart_Denom 0;
BA_ "GenSigSendType" SG_ 332 OBD_Warm_Up_Cycle 0;
BA_ "GenSigSwitchedByIgnition" SG_ 332 OBD_Warm_Up_Cycle 0;
BA_ "GenSigSendType" SG_ 332 TSK_ACC_FoD_Status 0;
BA_ "GenSigSwitchedByIgnition" SG_ 332 TSK_ACC_FoD_Status 0;
BA_ "GenSigSendType" SG_ 332 TSK_aktives_System 3;
BA_ "GenSigSwitchedByIgnition" SG_ 332 TSK_aktives_System 0;
BA_ "GenSigSendType" SG_ 332 TSK_Anf_Antriebsmoment 3;
BA_ "GenSigSwitchedByIgnition" SG_ 332 TSK_Anf_Antriebsmoment 0;
BA_ "GenSigSendType" SG_ 332 TSK_Einheit_vMax_Fahrerassistenz 0;
BA_ "GenSigSwitchedByIgnition" SG_ 332 TSK_Einheit_vMax_Fahrerassistenz 0;
BA_ "GenSigSendType" SG_ 332 TSK_erhoehter_Fahrwiderstand 3;
BA_ "GenSigSwitchedByIgnition" SG_ 332 TSK_erhoehter_Fahrwiderstand 0;
BA_ "GenSigSendType" SG_ 332 TSK_GRA_FoD_Status 0;
BA_ "GenSigSwitchedByIgnition" SG_ 332 TSK_GRA_FoD_Status 0;
BA_ "Fehlerwert" SG_ 332 TSK_Status_ARA 7;
BA_ "GenSigSendType" SG_ 332 TSK_Status_ARA 3;
BA_ "GenSigStartValue" SG_ 332 TSK_Status_ARA 1;
BA_ "GenSigSwitchedByIgnition" SG_ 332 TSK_Status_ARA 0;
BA_ "Fehlerwert" SG_ 332 TSK_Status_EA 7;
BA_ "GenSigSendType" SG_ 332 TSK_Status_EA 3;
BA_ "GenSigStartValue" SG_ 332 TSK_Status_EA 1;
BA_ "GenSigSwitchedByIgnition" SG_ 332 TSK_Status_EA 0;
BA_ "Fehlerwert" SG_ 332 TSK_Status_IPA 7;
BA_ "GenSigSendType" SG_ 332 TSK_Status_IPA 3;
BA_ "GenSigStartValue" SG_ 332 TSK_Status_IPA 1;
BA_ "GenSigSwitchedByIgnition" SG_ 332 TSK_Status_IPA 0;
BA_ "Fehlerwert" SG_ 332 TSK_Status_PLA 7;
BA_ "GenSigSendType" SG_ 332 TSK_Status_PLA 3;
BA_ "GenSigStartValue" SG_ 332 TSK_Status_PLA 1;
BA_ "GenSigSwitchedByIgnition" SG_ 332 TSK_Status_PLA 0;
BA_ "GenSigSendType" SG_ 332 TSK_vMax_aktuell 0;
BA_ "GenSigStartValue" SG_ 332 TSK_vMax_aktuell 255;
BA_ "GenSigSendType" SG_ 332 TSK_vMax_Fahrerassistenz 0;
BA_ "GenSigStartValue" SG_ 332 TSK_vMax_Fahrerassistenz 511;
BA_ "GenSigSwitchedByIgnition" SG_ 332 TSK_vMax_Fahrerassistenz 0;
BA_ "Fehlerwert" SG_ 2463978666 MO_Drehzahl_EM 8191;
BA_ "GenSigSendType" SG_ 2463978666 MO_Drehzahl_EM 0;
BA_ "GenSigStartValue" SG_ 2463978666 MO_Drehzahl_EM 8190;
BA_ "GenSigSwitchedByIgnition" SG_ 2463978666 MO_Drehzahl_EM 0;
BA_ "Fehlerwert" SG_ 2463978666 MO_Drehzahl_EM_sek 8191;
BA_ "GenSigSendType" SG_ 2463978666 MO_Drehzahl_EM_sek 0;
BA_ "GenSigStartValue" SG_ 2463978666 MO_Drehzahl_EM_sek 8190;
BA_ "GenSigSwitchedByIgnition" SG_ 2463978666 MO_Drehzahl_EM_sek 0;
BA_ "Fehlerwert" SG_ 2463978666 MO_EM1_Generator_Leistung 255;
BA_ "GenSigSendType" SG_ 2463978666 MO_EM1_Generator_Leistung 0;
BA_ "GenSigStartValue" SG_ 2463978666 MO_EM1_Generator_Leistung 254;
BA_ "GenSigSwitchedByIgnition" SG_ 2463978666 MO_EM1_Generator_Leistung 0;
BA_ "GenSigSendType" SG_ 2463978666 MO_EM1_Max_Leistung_Gesamt 0;
BA_ "GenSigStartValue" SG_ 2463978666 MO_EM1_Max_Leistung_Gesamt 8190;
BA_ "GenSigSwitchedByIgnition" SG_ 2463978666 MO_EM1_Max_Leistung_Gesamt 0;
BA_ "GenSigSendType" SG_ 2463978666 MO_EM1_Max_Spannung_Lim 0;
BA_ "GenSigStartValue" SG_ 2463978666 MO_EM1_Max_Spannung_Lim 1022;
BA_ "GenSigSwitchedByIgnition" SG_ 2463978666 MO_EM1_Max_Spannung_Lim 0;
BA_ "GenSigSendType" SG_ 2463978666 MO_EM1_Min_Leistung_Gesamt 0;
BA_ "GenSigStartValue" SG_ 2463978666 MO_EM1_Min_Leistung_Gesamt 8190;
BA_ "GenSigSwitchedByIgnition" SG_ 2463978666 MO_EM1_Min_Leistung_Gesamt 0;
BA_ "GenSigSendType" SG_ 2463978666 MO_EM1_Min_Spannung_Lim 0;
BA_ "GenSigStartValue" SG_ 2463978666 MO_EM1_Min_Spannung_Lim 1022;
BA_ "GenSigSwitchedByIgnition" SG_ 2463978666 MO_EM1_Min_Spannung_Lim 0;
BA_ "Fehlerwert" SG_ 2463978666 MO_EM2_Generator_Leistung 255;
BA_ "GenSigSendType" SG_ 2463978666 MO_EM2_Generator_Leistung 0;
BA_ "GenSigStartValue" SG_ 2463978666 MO_EM2_Generator_Leistung 254;
BA_ "GenSigSwitchedByIgnition" SG_ 2463978666 MO_EM2_Generator_Leistung 0;
BA_ "GenSigSendType" SG_ 2463978666 MO_EM2_Max_Leistung_Gesamt 0;
BA_ "GenSigStartValue" SG_ 2463978666 MO_EM2_Max_Leistung_Gesamt 8190;
BA_ "GenSigSwitchedByIgnition" SG_ 2463978666 MO_EM2_Max_Leistung_Gesamt 0;
BA_ "GenSigSendType" SG_ 2463978666 MO_EM2_Max_Spannung_Lim 0;
BA_ "GenSigStartValue" SG_ 2463978666 MO_EM2_Max_Spannung_Lim 1022;
BA_ "GenSigSwitchedByIgnition" SG_ 2463978666 MO_EM2_Max_Spannung_Lim 0;
BA_ "GenSigSendType" SG_ 2463978666 MO_EM2_Min_Leistung_Gesamt 0;
BA_ "GenSigStartValue" SG_ 2463978666 MO_EM2_Min_Leistung_Gesamt 8190;
BA_ "GenSigSwitchedByIgnition" SG_ 2463978666 MO_EM2_Min_Leistung_Gesamt 0;
BA_ "GenSigSendType" SG_ 2463978666 MO_EM2_Min_Spannung_Lim 0;
BA_ "GenSigStartValue" SG_ 2463978666 MO_EM2_Min_Spannung_Lim 1022;
BA_ "GenSigSwitchedByIgnition" SG_ 2463978666 MO_EM2_Min_Spannung_Lim 0;
BA_ "GenSigSendType" SG_ 2463978666 MO_Rekuperation_EM_Ges_Ueberlauf 0;
BA_ "GenSigSwitchedByIgnition" SG_ 2463978666 MO_Rekuperation_EM_Ges_Ueberlauf 0;
BA_ "GenSigSendType" SG_ 2463978666 MO_Rekuperation_Ges_EM 0;
BA_ "GenSigSwitchedByIgnition" SG_ 2463978666 MO_Rekuperation_Ges_EM 0;
BA_ "Fehlerwert" SG_ 2463978666 MO_Uebersetzung_EM 1023;
BA_ "GenSigSendType" SG_ 2463978666 MO_Uebersetzung_EM 0;
BA_ "GenSigStartValue" SG_ 2463978666 MO_Uebersetzung_EM 1022;
BA_ "GenSigSwitchedByIgnition" SG_ 2463978666 MO_Uebersetzung_EM 0;
BA_ "Fehlerwert" SG_ 2463978666 MO_Uebersetzung_EM_sek 1023;
BA_ "GenSigSendType" SG_ 2463978666 MO_Uebersetzung_EM_sek 0;
BA_ "GenSigStartValue" SG_ 2463978666 MO_Uebersetzung_EM_sek 1022;
BA_ "GenSigSwitchedByIgnition" SG_ 2463978666 MO_Uebersetzung_EM_sek 0;
BA_ "GenSigSendType" SG_ 2463978666 MO_Verbrauch_EM_Ges 0;
BA_ "GenSigSwitchedByIgnition" SG_ 2463978666 MO_Verbrauch_EM_Ges 0;
BA_ "GenSigSendType" SG_ 2463978666 MO_Verbrauch_EM_Ges_Ueberlauf 0;
BA_ "GenSigSwitchedByIgnition" SG_ 2463978666 MO_Verbrauch_EM_Ges_Ueberlauf 0;
BA_ "GenSigFuncType" SG_ 2463978666 Motor_57_BZ 1;
BA_ "GenSigSendType" SG_ 2463978666 Motor_57_BZ 0;
BA_ "GenSigSwitchedByIgnition" SG_ 2463978666 Motor_57_BZ 0;
BA_ "GenSigFuncType" SG_ 2463978666 Motor_57_CRC 2;
BA_ "GenSigSendType" SG_ 2463978666 Motor_57_CRC 0;
BA_ "GenSigSwitchedByIgnition" SG_ 2463978666 Motor_57_CRC 0;
BA_ "GenSigSendType" SG_ 2331595982 PTHyDrA_PrctUtilElDrv 0;
BA_ "GenSigStartValue" SG_ 2331595982 PTHyDrA_PrctUtilElDrv 2047;
BA_ "GenSigSwitchedByIgnition" SG_ 2331595982 PTHyDrA_PrctUtilElDrv 0;
BA_ "GenSigSendType" SG_ 2331595982 PTHyDrA_StAcv 0;
BA_ "GenSigStartValue" SG_ 2331595982 PTHyDrA_StAcv 3;
BA_ "GenSigSwitchedByIgnition" SG_ 2331595982 PTHyDrA_StAcv 0;
BA_ "GenSigSendType" SG_ 2331595982 PTUIPwrm_FacPwrDyn 0;
BA_ "GenSigStartValue" SG_ 2331595982 PTUIPwrm_FacPwrDyn 127;
BA_ "GenSigSwitchedByIgnition" SG_ 2331595982 PTUIPwrm_FacPwrDyn 0;
BA_ "GenSigSendType" SG_ 2331595982 PTUIPwrm_PrctBoostAvl 0;
BA_ "GenSigStartValue" SG_ 2331595982 PTUIPwrm_PrctBoostAvl 1023;
BA_ "GenSigSwitchedByIgnition" SG_ 2331595982 PTUIPwrm_PrctBoostAvl 0;
BA_ "GenSigSendType" SG_ 2331595982 PTUIPwrm_PrctPeakPwrAvl 0;
BA_ "GenSigStartValue" SG_ 2331595982 PTUIPwrm_PrctPeakPwrAvl 2047;
BA_ "GenSigSwitchedByIgnition" SG_ 2331595982 PTUIPwrm_PrctPeakPwrAvl 0;
BA_ "GenSigSendType" SG_ 2331595982 PTUIPwrm_PrctPwrElBoostCur 0;
BA_ "GenSigStartValue" SG_ 2331595982 PTUIPwrm_PrctPwrElBoostCur 1023;
BA_ "GenSigSwitchedByIgnition" SG_ 2331595982 PTUIPwrm_PrctPwrElBoostCur 0;
BA_ "GenSigSendType" SG_ 2331595982 PTUIPwrm_PrctPwrElBoostMaxUse 0;
BA_ "GenSigStartValue" SG_ 2331595982 PTUIPwrm_PrctPwrElBoostMaxUse 1023;
BA_ "GenSigSwitchedByIgnition" SG_ 2331595982 PTUIPwrm_PrctPwrElBoostMaxUse 0;
BA_ "GenSigSendType" SG_ 2331595982 PTUIPwrm_PrctPwrElDrvCur 0;
BA_ "GenSigStartValue" SG_ 2331595982 PTUIPwrm_PrctPwrElDrvCur 4095;
BA_ "GenSigSwitchedByIgnition" SG_ 2331595982 PTUIPwrm_PrctPwrElDrvCur 0;
BA_ "GenSigSendType" SG_ 2331595982 PTUIPwrm_PrctPwrGnrMaxUse 0;
BA_ "GenSigStartValue" SG_ 2331595982 PTUIPwrm_PrctPwrGnrMaxUse 2047;
BA_ "GenSigSwitchedByIgnition" SG_ 2331595982 PTUIPwrm_PrctPwrGnrMaxUse 0;
BA_ "GenSigSendType" SG_ 2331595982 PTUIPwrm_PrctPwrMotElMaxUse 0;
BA_ "GenSigStartValue" SG_ 2331595982 PTUIPwrm_PrctPwrMotElMaxUse 2047;
BA_ "GenSigSwitchedByIgnition" SG_ 2331595982 PTUIPwrm_PrctPwrMotElMaxUse 0;
BA_ "GenSigSendType" SG_ 2331595982 PTUIPwrm_PrctPwrMotMaxUse 0;
BA_ "GenSigStartValue" SG_ 2331595982 PTUIPwrm_PrctPwrMotMaxUse 2047;
BA_ "GenSigSwitchedByIgnition" SG_ 2331595982 PTUIPwrm_PrctPwrMotMaxUse 0;
BA_ "GenSigSendType" SG_ 2331595982 PTUIPwrm_PrctPwrSysCur 0;
BA_ "GenSigStartValue" SG_ 2331595982 PTUIPwrm_PrctPwrSysCur 4095;
BA_ "GenSigSwitchedByIgnition" SG_ 2331595982 PTUIPwrm_PrctPwrSysCur 0;
BA_ "GenSigSendType" SG_ 2331595982 PTUIPwrm_PwrElBoostNom 0;
BA_ "GenSigStartValue" SG_ 2331595982 PTUIPwrm_PwrElBoostNom 1023;
BA_ "GenSigSwitchedByIgnition" SG_ 2331595982 PTUIPwrm_PwrElBoostNom 0;
BA_ "GenSigSendType" SG_ 2331595982 PTUIPwrm_StAcv 0;
BA_ "GenSigSwitchedByIgnition" SG_ 2331595982 PTUIPwrm_StAcv 0;
BA_ "GenSigSendType" SG_ 2589283946 PTUIPwrm_PwrGnrNom 0;
BA_ "GenSigStartValue" SG_ 2589283946 PTUIPwrm_PwrGnrNom 2047;
BA_ "GenSigSwitchedByIgnition" SG_ 2589283946 PTUIPwrm_PwrGnrNom 0;
BA_ "GenSigSendType" SG_ 2589283946 PTUIPwrm_PwrMotElNom 0;
BA_ "GenSigStartValue" SG_ 2589283946 PTUIPwrm_PwrMotElNom 2047;
BA_ "GenSigSwitchedByIgnition" SG_ 2589283946 PTUIPwrm_PwrMotElNom 0;
BA_ "GenSigSendType" SG_ 2589283946 PTUIPwrm_PwrSysMotNomDisp 0;
BA_ "GenSigStartValue" SG_ 2589283946 PTUIPwrm_PwrSysMotNomDisp 2047;
BA_ "GenSigSwitchedByIgnition" SG_ 2589283946 PTUIPwrm_PwrSysMotNomDisp 0;
BA_ "Fehlerwert" SG_ 1155 MO_Powermeter_Charge_Grenze 1023;
BA_ "GenSigSendType" SG_ 1155 MO_Powermeter_Charge_Grenze 3;
BA_ "GenSigStartValue" SG_ 1155 MO_Powermeter_Charge_Grenze 1022;
BA_ "GenSigSwitchedByIgnition" SG_ 1155 MO_Powermeter_Charge_Grenze 0;
BA_ "GenSigSendType" SG_ 1155 Mo_Powermeter_Grenze 3;
BA_ "GenSigStartValue" SG_ 1155 Mo_Powermeter_Grenze 4093;
BA_ "GenSigSwitchedByIgnition" SG_ 1155 Mo_Powermeter_Grenze 0;
BA_ "Fehlerwert" SG_ 1155 MO_Powermeter_Grenze_strategisch 4095;
BA_ "GenSigSendType" SG_ 1155 MO_Powermeter_Grenze_strategisch 3;
BA_ "GenSigStartValue" SG_ 1155 MO_Powermeter_Grenze_strategisch 4094;
BA_ "GenSigSwitchedByIgnition" SG_ 1155 MO_Powermeter_Grenze_strategisch 0;
BA_ "GenSigSendType" SG_ 1155 MO_Powermeter_Inszenierung_aktiv 3;
BA_ "GenSigSwitchedByIgnition" SG_ 1155 MO_Powermeter_Inszenierung_aktiv 0;
BA_ "Fehlerwert" SG_ 1155 MO_Powermeter_obere_E_Grenze 4095;
BA_ "GenSigSendType" SG_ 1155 MO_Powermeter_obere_E_Grenze 3;
BA_ "GenSigStartValue" SG_ 1155 MO_Powermeter_obere_E_Grenze 4094;
BA_ "GenSigSwitchedByIgnition" SG_ 1155 MO_Powermeter_obere_E_Grenze 0;
BA_ "Fehlerwert" SG_ 1155 MO_Powermeter_untere_E_Grenze 4095;
BA_ "GenSigSendType" SG_ 1155 MO_Powermeter_untere_E_Grenze 3;
BA_ "GenSigStartValue" SG_ 1155 MO_Powermeter_untere_E_Grenze 4094;
BA_ "GenSigSwitchedByIgnition" SG_ 1155 MO_Powermeter_untere_E_Grenze 0;
BA_ "Fehlerwert" SG_ 1156 ND_GDOP 1023;
BA_ "GenSigSendType" SG_ 1156 ND_GDOP 0;
BA_ "GenSigStartValue" SG_ 1156 ND_GDOP 1022;
BA_ "GenSigSwitchedByIgnition" SG_ 1156 ND_GDOP 0;
BA_ "Fehlerwert" SG_ 1156 ND_HDOP 1023;
BA_ "GenSigSendType" SG_ 1156 ND_HDOP 0;
BA_ "GenSigStartValue" SG_ 1156 ND_HDOP 1022;
BA_ "GenSigSwitchedByIgnition" SG_ 1156 ND_HDOP 0;
BA_ "Fehlerwert" SG_ 1156 ND_Heading 4095;
BA_ "GenSigSendType" SG_ 1156 ND_Heading 0;
BA_ "GenSigStartValue" SG_ 1156 ND_Heading 4094;
BA_ "GenSigSwitchedByIgnition" SG_ 1156 ND_Heading 0;
BA_ "GenSigSendType" SG_ 1156 ND_Init 0;
BA_ "GenSigSwitchedByIgnition" SG_ 1156 ND_Init 0;
BA_ "Fehlerwert" SG_ 1156 ND_PDOP 1023;
BA_ "GenSigSendType" SG_ 1156 ND_PDOP 0;
BA_ "GenSigStartValue" SG_ 1156 ND_PDOP 1022;
BA_ "GenSigSwitchedByIgnition" SG_ 1156 ND_PDOP 0;
BA_ "Fehlerwert" SG_ 1156 ND_TDOP 1023;
BA_ "GenSigSendType" SG_ 1156 ND_TDOP 0;
BA_ "GenSigStartValue" SG_ 1156 ND_TDOP 1022;
BA_ "GenSigSwitchedByIgnition" SG_ 1156 ND_TDOP 0;
BA_ "Fehlerwert" SG_ 1156 ND_VDOP 1023;
BA_ "GenSigSendType" SG_ 1156 ND_VDOP 0;
BA_ "GenSigStartValue" SG_ 1156 ND_VDOP 1022;
BA_ "GenSigSwitchedByIgnition" SG_ 1156 ND_VDOP 0;
BA_ "Fehlerwert" SG_ 1157 ND_SatInUse 31;
BA_ "GenSigSendType" SG_ 1157 ND_SatInUse 0;
BA_ "GenSigStartValue" SG_ 1157 ND_SatInUse 30;
BA_ "GenSigSwitchedByIgnition" SG_ 1157 ND_SatInUse 0;
BA_ "Fehlerwert" SG_ 1157 ND_SatInView 31;
BA_ "GenSigSendType" SG_ 1157 ND_SatInView 0;
BA_ "GenSigStartValue" SG_ 1157 ND_SatInView 30;
BA_ "GenSigSwitchedByIgnition" SG_ 1157 ND_SatInView 0;
BA_ "GenSigSendType" SG_ 1157 ND_UTC 0;
BA_ "GenSigSwitchedByIgnition" SG_ 1157 ND_UTC 0;
BA_ "Fehlerwert" SG_ 1157 NP_Altitude 4095;
BA_ "GenSigSendType" SG_ 1157 NP_Altitude 0;
BA_ "GenSigStartValue" SG_ 1157 NP_Altitude 4094;
BA_ "GenSigSwitchedByIgnition" SG_ 1157 NP_Altitude 0;
BA_ "Fehlerwert" SG_ 1157 POS_Guete_horizontal 127;
BA_ "GenSigSendType" SG_ 1157 POS_Guete_horizontal 0;
BA_ "GenSigStartValue" SG_ 1157 POS_Guete_horizontal 126;
BA_ "GenSigSwitchedByIgnition" SG_ 1157 POS_Guete_horizontal 0;
BA_ "GenSigSendType" SG_ 1157 POS_Guete_horizontal_verfuegbar 0;
BA_ "GenSigSwitchedByIgnition" SG_ 1157 POS_Guete_horizontal_verfuegbar 0;
BA_ "GenSigSendType" SG_ 2527679512 ND_Fuelstation_detected 0;
BA_ "GenSigStartValue" SG_ 2527679512 ND_Fuelstation_detected 3;
BA_ "GenSigSwitchedByIgnition" SG_ 2527679512 ND_Fuelstation_detected 0;
BA_ "GenSigSendType" SG_ 2527679512 ND_NrSameMeasure 0;
BA_ "GenSigSwitchedByIgnition" SG_ 2527679512 ND_NrSameMeasure 0;
BA_ "Fehlerwert" SG_ 2527679512 ND_RecDelay 4095;
BA_ "GenSigSendType" SG_ 2527679512 ND_RecDelay 0;
BA_ "GenSigStartValue" SG_ 2527679512 ND_RecDelay 4094;
BA_ "GenSigSwitchedByIgnition" SG_ 2527679512 ND_RecDelay 0;
BA_ "GenSigSendType" SG_ 2527679512 ND_RouteType 0;
BA_ "GenSigSwitchedByIgnition" SG_ 2527679512 ND_RouteType 0;
BA_ "Fehlerwert" SG_ 2527679512 ND_SendDelay 4095;
BA_ "GenSigSendType" SG_ 2527679512 ND_SendDelay 0;
BA_ "GenSigStartValue" SG_ 2527679512 ND_SendDelay 4094;
BA_ "GenSigSwitchedByIgnition" SG_ 2527679512 ND_SendDelay 0;
BA_ "GenSigSendType" SG_ 2527679512 ND_TimeOffset 0;
BA_ "GenSigSwitchedByIgnition" SG_ 2527679512 ND_TimeOffset 0;
BA_ "Fehlerwert" SG_ 2527679512 ND_TimeToDestination 510;
BA_ "GenSigSendType" SG_ 2527679512 ND_TimeToDestination 0;
BA_ "GenSigStartValue" SG_ 2527679512 ND_TimeToDestination 511;
BA_ "GenSigSwitchedByIgnition" SG_ 2527679512 ND_TimeToDestination 0;
BA_ "GenSigSendType" SG_ 2527679512 ND_Timezone_DaylightSavingOffset 0;
BA_ "GenSigSwitchedByIgnition" SG_ 2527679512 ND_Timezone_DaylightSavingOffset 0;
BA_ "Fehlerwert" SG_ 2527679512 ND_Timezone_Offset 15;
BA_ "GenSigSendType" SG_ 2527679512 ND_Timezone_Offset 0;
BA_ "GenSigStartValue" SG_ 2527679512 ND_Timezone_Offset 14;
BA_ "GenSigSwitchedByIgnition" SG_ 2527679512 ND_Timezone_Offset 0;
BA_ "GenSigSendType" SG_ 2527679512 ND_Timezone_SignBit 0;
BA_ "GenSigSwitchedByIgnition" SG_ 2527679512 ND_Timezone_SignBit 0;
BA_ "GenSigSendType" SG_ 2527679512 ND_Timezone_Validity 0;
BA_ "GenSigSwitchedByIgnition" SG_ 2527679512 ND_Timezone_Validity 0;
BA_ "Fehlerwert" SG_ 2527679512 ND_Velocity 1023;
BA_ "GenSigSendType" SG_ 2527679512 ND_Velocity 0;
BA_ "GenSigStartValue" SG_ 2527679512 ND_Velocity 1022;
BA_ "GenSigSwitchedByIgnition" SG_ 2527679512 ND_Velocity 0;
BA_ "Fehlerwert" SG_ 2527679665 ND_Avrg_Speed_RangeData 255;
BA_ "GenSigSendType" SG_ 2527679665 ND_Avrg_Speed_RangeData 0;
BA_ "GenSigStartValue" SG_ 2527679665 ND_Avrg_Speed_RangeData 254;
BA_ "GenSigSwitchedByIgnition" SG_ 2527679665 ND_Avrg_Speed_RangeData 0;
BA_ "GenSigSendType" SG_ 2527679665 ND_PSD_Street_Category 0;
BA_ "GenSigSwitchedByIgnition" SG_ 2527679665 ND_PSD_Street_Category 0;
BA_ "GenSigSendType" SG_ 1158 NP_Fix 0;
BA_ "GenSigSwitchedByIgnition" SG_ 1158 NP_Fix 0;
BA_ "Fehlerwert" SG_ 1158 NP_LatDegree 134217727;
BA_ "GenSigSendType" SG_ 1158 NP_LatDegree 0;
BA_ "GenSigStartValue" SG_ 1158 NP_LatDegree 134217726;
BA_ "GenSigSwitchedByIgnition" SG_ 1158 NP_LatDegree 0;
BA_ "GenSigSendType" SG_ 1158 NP_LatDirection 0;
BA_ "GenSigStartValue" SG_ 1158 NP_LatDirection 1;
BA_ "GenSigSwitchedByIgnition" SG_ 1158 NP_LatDirection 0;
BA_ "Fehlerwert" SG_ 1158 NP_LongDegree 268435455;
BA_ "GenSigSendType" SG_ 1158 NP_LongDegree 0;
BA_ "GenSigStartValue" SG_ 1158 NP_LongDegree 268435454;
BA_ "GenSigSwitchedByIgnition" SG_ 1158 NP_LongDegree 0;
BA_ "GenSigSendType" SG_ 1158 NP_LongDirection 0;
BA_ "GenSigStartValue" SG_ 1158 NP_LongDirection 1;
BA_ "GenSigSwitchedByIgnition" SG_ 1158 NP_LongDirection 0;
BA_ "Fehlerwert" SG_ 1158 NP_Sat 31;
BA_ "GenSigSendType" SG_ 1158 NP_Sat 0;
BA_ "GenSigStartValue" SG_ 1158 NP_Sat 30;
BA_ "GenSigSwitchedByIgnition" SG_ 1158 NP_Sat 0;
BA_ "GenSigSwitchedByIgnition" SG_ 2589283496 POS_Heading 0;
BA_ "Fehlerwert" SG_ 2589283496 POS_Heading_Trust 3;
BA_ "GenSigSwitchedByIgnition" SG_ 2589283496 POS_Heading_Trust 0;
BA_ "GenSigSwitchedByIgnition" SG_ 2589283496 POS_Last_GPS_Sync 0;
BA_ "Fehlerwert" SG_ 2589283496 POS_LatDegree 134217727;
BA_ "GenSigStartValue" SG_ 2589283496 POS_LatDegree 134217726;
BA_ "GenSigSwitchedByIgnition" SG_ 2589283496 POS_LatDegree 0;
BA_ "GenSigSwitchedByIgnition" SG_ 2589283496 POS_LatDirection 0;
BA_ "Fehlerwert" SG_ 2589283496 POS_LongDegree 268435455;
BA_ "GenSigStartValue" SG_ 2589283496 POS_LongDegree 268435454;
BA_ "GenSigSwitchedByIgnition" SG_ 2589283496 POS_LongDegree 0;
BA_ "GenSigSwitchedByIgnition" SG_ 2589283496 POS_LongDirection 0;
BA_ "GenSigSendType" SG_ 2589283496 POS_MUX 0;
BA_ "GenSigStartValue" SG_ 2589283496 POS_MUX 3;
BA_ "GenSigSwitchedByIgnition" SG_ 2589283496 POS_MUX 0;
BA_ "GenSigSendType" SG_ 2589283496 POS_ODD_EVEN 0;
BA_ "GenSigSwitchedByIgnition" SG_ 2589283496 POS_ODD_EVEN 0;
BA_ "GenSigSwitchedByIgnition" SG_ 2589283496 POS_PosStati 0;
BA_ "GenSigSwitchedByIgnition" SG_ 2589283496 POS_UTC_REF 0;
BA_ "GenSigSendType" SG_ 2527679647 MDK_Anf_Start_Auth 3;
BA_ "GenSigSwitchedByIgnition" SG_ 2527679647 MDK_Anf_Start_Auth 0;
BA_ "GenSigSendType" SG_ 2527679647 MDK_BTLE_Spielschutz_aktivieren 3;
BA_ "GenSigSwitchedByIgnition" SG_ 2527679647 MDK_BTLE_Spielschutz_aktivieren 0;
BA_ "GenSigSendType" SG_ 2527679647 MDK_NFC_Spielschutz_aktivieren 3;
BA_ "GenSigSwitchedByIgnition" SG_ 2527679647 MDK_NFC_Spielschutz_aktivieren 0;
BA_ "GenSigSendType" SG_ 2527679647 NFC_ESM_aktivieren 3;
BA_ "GenSigSwitchedByIgnition" SG_ 2527679647 NFC_ESM_aktivieren 0;
BA_ "GenSigSendType" SG_ 2527679647 NFC_Laden_unterbrechen 3;
BA_ "GenSigSwitchedByIgnition" SG_ 2527679647 NFC_Laden_unterbrechen 0;
BA_ "GenSigSendType" SG_ 2527679647 Stellgliedtest_NFC 0;
BA_ "GenSigSwitchedByIgnition" SG_ 2527679647 Stellgliedtest_NFC 0;
BA_ "GenSigSendType" SG_ 2527679645 NFC_MiKo_ESM_aktiv 0;
BA_ "GenSigSwitchedByIgnition" SG_ 2527679645 NFC_MiKo_ESM_aktiv 0;
BA_ "GenSigSendType" SG_ 2527679645 NFC_MiKo_Fehler 0;
BA_ "GenSigSwitchedByIgnition" SG_ 2527679645 NFC_MiKo_Fehler 0;
BA_ "GenSigSendType" SG_ 2527679645 NFC_MiKo_Laden_unterbrechen 0;
BA_ "GenSigSwitchedByIgnition" SG_ 2527679645 NFC_MiKo_Laden_unterbrechen 0;
BA_ "GenSigSendType" SG_ 2527679645 NFC_MiKo_NFC_Device_gekoppelt 0;
BA_ "GenSigSwitchedByIgnition" SG_ 2527679645 NFC_MiKo_NFC_Device_gekoppelt 0;
BA_ "GenSigSendType" SG_ 2527679645 NFC_MiKo_NFC_Device_Status 0;
BA_ "GenSigFuncType" SG_ 2600468745 NM_DispKBI_FS_CAB_V15 16;
BA_ "GenSigSwitchedByIgnition" SG_ 2600468745 NM_DispKBI_FS_CAB_V15 0;
BA_ "GenSigSwitchedByIgnition" SG_ 2600468745 NM_DispKBI_FS_CarWakeup 0;
BA_ "GenSigSwitchedByIgnition" SG_ 2600468745 NM_DispKBI_FS_CBV_AWB 0;
BA_ "GenSigSwitchedByIgnition" SG_ 2600468745 NM_DispKBI_FS_CBV_CRI 0;
BA_ "GenSigSwitchedByIgnition" SG_ 2600468745 NM_DispKBI_FS_NM_aktiv_Diagnose 0;
BA_ "GenSigSwitchedByIgnition" SG_ 2600468745 NM_DispKBI_FS_NM_aktiv_KL15 0;
BA_ "GenSigSwitchedByIgnition" SG_ 2600468745 NM_DispKBI_FS_NM_aktiv_Tmin 0;
BA_ "GenSigSwitchedByIgnition" SG_ 2600468745 NM_DispKBI_FS_NM_State 0;
BA_ "GenSigSwitchedByIgnition" SG_ 2600468745 NM_DispKBI_FS_UDS_CC 0;
BA_ "GenSigFuncType" SG_ 2600468496 NM_Gateway_CAB_V15 16;
BA_ "GenSigSwitchedByIgnition" SG_ 2600468496 NM_Gateway_CAB_V15 0;
BA_ "GenSigSwitchedByIgnition" SG_ 2600468496 NM_Gateway_Car_Wakeup 0;
BA_ "GenSigSwitchedByIgnition" SG_ 2600468496 NM_Gateway_CBV_AWB 0;
BA_ "GenSigSwitchedByIgnition" SG_ 2600468496 NM_Gateway_CBV_CRI 0;
BA_ "GenSigSwitchedByIgnition" SG_ 2600468496 NM_Gateway_NM_aktiv_CAB 0;
BA_ "GenSigSwitchedByIgnition" SG_ 2600468496 NM_Gateway_NM_aktiv_Diagnose 0;
BA_ "GenSigSwitchedByIgnition" SG_ 2600468496 NM_Gateway_NM_aktiv_Energie 0;
BA_ "GenSigSwitchedByIgnition" SG_ 2600468496 NM_Gateway_NM_aktiv_FoD 0;
BA_ "GenSigSwitchedByIgnition" SG_ 2600468496 NM_Gateway_NM_aktiv_IAA_PSO 0;
BA_ "GenSigSwitchedByIgnition" SG_ 2600468496 NM_Gateway_NM_aktiv_Kessy 0;
BA_ "GenSigSwitchedByIgnition" SG_ 2600468496 NM_Gateway_NM_aktiv_KL15 0;
BA_ "GenSigSwitchedByIgnition" SG_ 2600468496 NM_Gateway_NM_aktiv_KS 0;
BA_ "GenSigSwitchedByIgnition" SG_ 2600468496 NM_Gateway_NM_aktiv_Licht 0;
BA_ "GenSigSwitchedByIgnition" SG_ 2600468496 NM_Gateway_NM_aktiv_PaCo 0;
BA_ "GenSigSwitchedByIgnition" SG_ 2600468496 NM_Gateway_NM_aktiv_RTM 0;
BA_ "GenSigSwitchedByIgnition" SG_ 2600468496 NM_Gateway_NM_aktiv_Standklima 0;
BA_ "GenSigSwitchedByIgnition" SG_ 2600468496 NM_Gateway_NM_aktiv_Tmin 0;
BA_ "GenSigSwitchedByIgnition" SG_ 2600468496 NM_Gateway_NM_aktiv_USS 0;
BA_ "GenSigSwitchedByIgnition" SG_ 2600468496 NM_Gateway_NM_aktiv_ZM 0;
BA_ "GenSigSwitchedByIgnition" SG_ 2600468496 NM_Gateway_NM_aktiv_ZV 0;
BA_ "GenSigSwitchedByIgnition" SG_ 2600468496 NM_Gateway_NM_State 0;
BA_ "GenSigSwitchedByIgnition" SG_ 2600468496 NM_Gateway_UDS_CC 0;
BA_ "GenSigFuncType" SG_ 2600468507 NM_HUD_CAB_V15 16;
BA_ "GenSigSwitchedByIgnition" SG_ 2600468507 NM_HUD_CAB_V15 0;
BA_ "GenSigSwitchedByIgnition" SG_ 2600468507 NM_HUD_Car_WakeUp 0;
BA_ "GenSigSwitchedByIgnition" SG_ 2600468507 NM_HUD_CBV_AWB 0;
BA_ "GenSigStartValue" SG_ 2600468507 NM_HUD_CBV_CRI 1;
BA_ "GenSigSwitchedByIgnition" SG_ 2600468507 NM_HUD_CBV_CRI 0;
BA_ "GenSigSwitchedByIgnition" SG_ 2600468507 NM_HUD_NM_aktiv_Diagnose 0;
BA_ "GenSigSwitchedByIgnition" SG_ 2600468507 NM_HUD_NM_aktiv_KL15 0;
BA_ "GenSigSwitchedByIgnition" SG_ 2600468507 NM_HUD_NM_aktiv_Tmin 0;
BA_ "GenSigSwitchedByIgnition" SG_ 2600468507 NM_HUD_NM_State 0;
BA_ "GenSigSwitchedByIgnition" SG_ 2600468507 NM_HUD_UDS_CC 0;
BA_ "GenSigFuncType" SG_ 2600468595 NM_Info_El_CAB_V15 16;
BA_ "GenSigSwitchedByIgnition" SG_ 2600468595 NM_Info_El_CAB_V15 0;
BA_ "GenSigSwitchedByIgnition" SG_ 2600468595 NM_Info_El_Car_Wakeup 0;
BA_ "GenSigSwitchedByIgnition" SG_ 2600468595 NM_Info_El_CBV_AWB 0;
BA_ "GenSigStartValue" SG_ 2600468595 NM_Info_El_CBV_CRI 1;
BA_ "GenSigSwitchedByIgnition" SG_ 2600468595 NM_Info_El_CBV_CRI 0;
BA_ "GenSigSwitchedByIgnition" SG_ 2600468595 NM_Info_El_NM_aktiv_Applikation 0;
BA_ "GenSigSwitchedByIgnition" SG_ 2600468595 NM_Info_El_NM_aktiv_BAP_Comm 0;
BA_ "GenSigSwitchedByIgnition" SG_ 2600468595 NM_Info_El_NM_aktiv_Diagnose 0;
BA_ "GenSigSwitchedByIgnition" SG_ 2600468595 NM_Info_El_NM_aktiv_IAA 0;
BA_ "GenSigSwitchedByIgnition" SG_ 2600468595 NM_Info_El_NM_aktiv_KL15 0;
BA_ "GenSigSwitchedByIgnition" SG_ 2600468595 NM_Info_El_NM_aktiv_MIBCAN 0;
BA_ "GenSigSwitchedByIgnition" SG_ 2600468595 NM_Info_El_NM_aktiv_Powerstate 0;
BA_ "GenSigSwitchedByIgnition" SG_ 2600468595 NM_Info_El_NM_aktiv_SmartLight 0;
BA_ "GenSigSwitchedByIgnition" SG_ 2600468595 NM_Info_El_NM_aktiv_Tmin 0;
BA_ "GenSigSwitchedByIgnition" SG_ 2600468595 NM_Info_El_NM_State 0;
BA_ "GenSigSwitchedByIgnition" SG_ 2600468595 NM_Info_El_UDS_CC 0;
BA_ "GenSigFuncType" SG_ 2600468500 NM_Kombi_CAB_V15 16;
BA_ "GenSigSwitchedByIgnition" SG_ 2600468500 NM_Kombi_CAB_V15 0;
BA_ "GenSigSwitchedByIgnition" SG_ 2600468500 NM_Kombi_Car_Wakeup 0;
BA_ "GenSigSwitchedByIgnition" SG_ 2600468500 NM_Kombi_CBV_AWB 0;
BA_ "GenSigFuncType" SG_ 2600468500 NM_Kombi_CBV_CRI 8;
BA_ "GenSigSwitchedByIgnition" SG_ 2600468500 NM_Kombi_CBV_CRI 0;
BA_ "GenSigSwitchedByIgnition" SG_ 2600468500 NM_Kombi_NM_aktiv_Buzzer 0;
BA_ "GenSigSwitchedByIgnition" SG_ 2600468500 NM_Kombi_NM_aktiv_Diagnose 0;
BA_ "GenSigSwitchedByIgnition" SG_ 2600468500 NM_Kombi_NM_aktiv_KL15 0;
BA_ "GenSigSwitchedByIgnition" SG_ 2600468500 NM_Kombi_NM_aktiv_Schluesselkomm 0;
BA_ "GenSigSwitchedByIgnition" SG_ 2600468500 NM_Kombi_NM_aktiv_Tmin 0;
BA_ "GenSigSwitchedByIgnition" SG_ 2600468500 NM_Kombi_NM_aktiv_VLW 0;
BA_ "GenSigSwitchedByIgnition" SG_ 2600468500 NM_Kombi_NM_State 0;
BA_ "GenSigSwitchedByIgnition" SG_ 2600468500 NM_Kombi_UDS_CC 0;
BA_ "GenSigFuncType" SG_ 2600468748 NM_SmLi_01_CAB_V15 16;
BA_ "GenSigSwitchedByIgnition" SG_ 2600468748 NM_SmLi_01_CAB_V15 0;
BA_ "GenSigSwitchedByIgnition" SG_ 2600468748 NM_SmLi_01_CarWakeup 0;
BA_ "GenSigSwitchedByIgnition" SG_ 2600468748 NM_SmLi_01_CBV_AWB 0;
BA_ "GenSigSwitchedByIgnition" SG_ 2600468748 NM_SmLi_01_CBV_CRI 0;
BA_ "GenSigSwitchedByIgnition" SG_ 2600468748 NM_SmLi_01_NM_aktiv_Diagnose 0;
BA_ "GenSigSwitchedByIgnition" SG_ 2600468748 NM_SmLi_01_NM_aktiv_KL15 0;
BA_ "GenSigSwitchedByIgnition" SG_ 2600468748 NM_SmLi_01_NM_aktiv_Tmin 0;
BA_ "GenSigSwitchedByIgnition" SG_ 2600468748 NM_SmLi_01_NM_State 0;
BA_ "GenSigSwitchedByIgnition" SG_ 2600468748 NM_SmLi_01_UDS_CC 0;
BA_ "GenSigFuncType" SG_ 2621702665 OBDC_DispKBI_FS_Req_FD_Data 9;
BA_ "GenSigSendType" SG_ 2621702665 OBDC_DispKBI_FS_Req_FD_Data 3;
BA_ "GenSigSwitchedByIgnition" SG_ 2621702665 OBDC_DispKBI_FS_Req_FD_Data 0;
BA_ "GenSigFuncType" SG_ 2621833737 OBDC_DispKBI_FS_Resp_FD_Data 9;
BA_ "GenSigSendType" SG_ 2621833737 OBDC_DispKBI_FS_Resp_FD_Data 3;
BA_ "GenSigSwitchedByIgnition" SG_ 2621833737 OBDC_DispKBI_FS_Resp_FD_Data 0;
BA_ "GenSigFuncType" SG_ 2549940736 OBDC_Funktionaler_Req_All_Data 9;
BA_ "GenSigSendType" SG_ 2549940736 OBDC_Funktionaler_Req_All_Data 3;
BA_ "GenSigSwitchedByIgnition" SG_ 2549940736 OBDC_Funktionaler_Req_All_Data 0;
BA_ "GenSigFuncType" SG_ 2621506048 OBDC_Funktion_Req_All_FD_Data 9;
BA_ "GenSigSendType" SG_ 2621506048 OBDC_Funktion_Req_All_FD_Data 3;
BA_ "GenSigSwitchedByIgnition" SG_ 2621506048 OBDC_Funktion_Req_All_FD_Data 0;
BA_ "GenSigFuncType" SG_ 2621440539 OBDC_HUD_Req_FD_Data 9;
BA_ "GenSigSendType" SG_ 2621440539 OBDC_HUD_Req_FD_Data 3;
BA_ "GenSigSwitchedByIgnition" SG_ 2621440539 OBDC_HUD_Req_FD_Data 0;
BA_ "GenSigFuncType" SG_ 2621571611 OBDC_HUD_Resp_FD_Data 9;
BA_ "GenSigSendType" SG_ 2621571611 OBDC_HUD_Resp_FD_Data 3;
BA_ "GenSigSwitchedByIgnition" SG_ 2621571611 OBDC_HUD_Resp_FD_Data 0;
BA_ "GenSigFuncType" SG_ 2621440532 OBDC_Kombi_Req_FD_Data 9;
BA_ "GenSigSendType" SG_ 2621440532 OBDC_Kombi_Req_FD_Data 3;
BA_ "GenSigSwitchedByIgnition" SG_ 2621440532 OBDC_Kombi_Req_FD_Data 0;
BA_ "GenSigFuncType" SG_ 2621571604 OBDC_Kombi_Resp_FD_Data 9;
BA_ "GenSigSendType" SG_ 2621571604 OBDC_Kombi_Resp_FD_Data 3;
BA_ "GenSigSwitchedByIgnition" SG_ 2621571604 OBDC_Kombi_Resp_FD_Data 0;
BA_ "GenSigFuncType" SG_ 2621702668 OBDC_SmLi_01_Req_FD_Data 9;
BA_ "GenSigSendType" SG_ 2621702668 OBDC_SmLi_01_Req_FD_Data 3;
BA_ "GenSigSwitchedByIgnition" SG_ 2621702668 OBDC_SmLi_01_Req_FD_Data 0;
BA_ "GenSigFuncType" SG_ 2621833740 OBDC_SmLi_01_Resp_FD_Data 9;
BA_ "GenSigSendType" SG_ 2621833740 OBDC_SmLi_01_Resp_FD_Data 3;
BA_ "GenSigSwitchedByIgnition" SG_ 2621833740 OBDC_SmLi_01_Resp_FD_Data 0;
BA_ "GenSigFuncType" SG_ 2549903374 OBDC_SSN_ABT_1_Req_Data 9;
BA_ "GenSigSendType" SG_ 2549903374 OBDC_SSN_ABT_1_Req_Data 3;
BA_ "GenSigSwitchedByIgnition" SG_ 2549903374 OBDC_SSN_ABT_1_Req_Data 0;
BA_ "GenSigFuncType" SG_ 2550034446 OBDC_SSN_ABT_1_Resp_Data 9;
BA_ "GenSigSendType" SG_ 2550034446 OBDC_SSN_ABT_1_Resp_Data 3;
BA_ "GenSigSwitchedByIgnition" SG_ 2550034446 OBDC_SSN_ABT_1_Resp_Data 0;
BA_ "GenSigFuncType" SG_ 2549875309 OBDC_TV_Tuner_Req_Data 9;
BA_ "GenSigSendType" SG_ 2549875309 OBDC_TV_Tuner_Req_Data 3;
BA_ "GenSigSwitchedByIgnition" SG_ 2549875309 OBDC_TV_Tuner_Req_Data 0;
BA_ "GenSigFuncType" SG_ 2550006381 OBDC_TV_Tuner_Resp_Data 9;
BA_ "GenSigSendType" SG_ 2550006381 OBDC_TV_Tuner_Resp_Data 3;
BA_ "GenSigSwitchedByIgnition" SG_ 2550006381 OBDC_TV_Tuner_Resp_Data 0;
BA_ "GenSigFuncType" SG_ 2549875365 OBDC_WLC1_Req_Data 9;
BA_ "GenSigSendType" SG_ 2549875365 OBDC_WLC1_Req_Data 3;
BA_ "GenSigSwitchedByIgnition" SG_ 2549875365 OBDC_WLC1_Req_Data 0;
BA_ "GenSigFuncType" SG_ 2550006437 OBDC_WLC1_Resp_Data 9;
BA_ "GenSigSendType" SG_ 2550006437 OBDC_WLC1_Resp_Data 3;
BA_ "GenSigSwitchedByIgnition" SG_ 2550006437 OBDC_WLC1_Resp_Data 0;
BA_ "GenSigFuncType" SG_ 2564502513 OBDx_allOBD_Req_Data 9;
BA_ "GenSigSendType" SG_ 2564502513 OBDx_allOBD_Req_Data 3;
BA_ "GenSigSwitchedByIgnition" SG_ 2564502513 OBDx_allOBD_Req_Data 0;
BA_ "GenSigSendType" SG_ 2589284094 Fahrerdisplay_Kombi_ORUData 0;
BA_ "GenSigSwitchedByIgnition" SG_ 2589284094 Fahrerdisplay_Kombi_ORUData 0;
BA_ "GenSigSendType" SG_ 2589284094 Fahrerdisplay_Kombi_ORUDataIndex 0;
BA_ "GenSigSwitchedByIgnition" SG_ 2589284094 Fahrerdisplay_Kombi_ORUDataIndex 0;
BA_ "GenSigFuncType" SG_ 2589284094 ORU_007E_BZ 1;
BA_ "GenSigSendType" SG_ 2589284094 ORU_007E_BZ 0;
BA_ "GenSigSwitchedByIgnition" SG_ 2589284094 ORU_007E_BZ 0;
BA_ "GenSigFuncType" SG_ 2589284094 ORU_007E_CRC 2;
BA_ "GenSigSendType" SG_ 2589284094 ORU_007E_CRC 0;
BA_ "GenSigSwitchedByIgnition" SG_ 2589284094 ORU_007E_CRC 0;
BA_ "GenSigSendType" SG_ 2589284095 HUD_ORUData 0;
BA_ "GenSigSwitchedByIgnition" SG_ 2589284095 HUD_ORUData 0;
BA_ "GenSigSendType" SG_ 2589284095 HUD_ORUDataIndex 0;
BA_ "GenSigSwitchedByIgnition" SG_ 2589284095 HUD_ORUDataIndex 0;
BA_ "GenSigFuncType" SG_ 2589284095 ORU_0082_BZ 1;
BA_ "GenSigSendType" SG_ 2589284095 ORU_0082_BZ 0;
BA_ "GenSigSwitchedByIgnition" SG_ 2589284095 ORU_0082_BZ 0;
BA_ "GenSigFuncType" SG_ 2589284095 ORU_0082_CRC 2;
BA_ "GenSigSendType" SG_ 2589284095 ORU_0082_CRC 0;
BA_ "GenSigSwitchedByIgnition" SG_ 2589284095 ORU_0082_CRC 0;
BA_ "GenSigFuncType" SG_ 2589283656 ORU_01_BZ 1;
BA_ "GenSigSendType" SG_ 2589283656 ORU_01_BZ 0;
BA_ "GenSigFuncType" SG_ 2589283656 ORU_01_CRC 2;
BA_ "GenSigSendType" SG_ 2589283656 ORU_01_CRC 0;
BA_ "GenSigSendType" SG_ 2589283656 ORU_DiagAddress 0;
BA_ "GenSigSwitchedByIgnition" SG_ 2589283656 ORU_DiagAddress 0;
BA_ "GenSigSendType" SG_ 2589283656 ORU_EM_Anfrage_Flashdauer 3;
BA_ "GenSigSwitchedByIgnition" SG_ 2589283656 ORU_EM_Anfrage_Flashdauer 0;
BA_ "GenSigSendType" SG_ 2589283656 ORU_EM_Anfrage_freigegebeneNetze 3;
BA_ "GenSigSwitchedByIgnition" SG_ 2589283656 ORU_EM_Anfrage_freigegebeneNetze 0;
BA_ "GenSigSendType" SG_ 2589283656 ORU_EM_Anfrage_Stromaufnahme 3;
BA_ "GenSigSwitchedByIgnition" SG_ 2589283656 ORU_EM_Anfrage_Stromaufnahme 0;
BA_ "GenSigSendType" SG_ 2589283656 ORU_Inventory 0;
BA_ "GenSigSwitchedByIgnition" SG_ 2589283656 ORU_Inventory 0;
BA_ "GenSigSendType" SG_ 2589283656 ORU_Status 3;
BA_ "GenSigSwitchedByIgnition" SG_ 2589283656 ORU_Status 0;
BA_ "GenSigSendType" SG_ 2589283656 ORU_Warnung 3;
BA_ "GenSigSwitchedByIgnition" SG_ 2589283656 ORU_Warnung 0;
BA_ "GenSigFuncType" SG_ 2589283672 SOK_ORU_01_Signatur 15;
BA_ "GenSigSendType" SG_ 2589283672 SOK_ORU_01_Signatur 3;
BA_ "GenSigSwitchedByIgnition" SG_ 2589283672 SOK_ORU_01_Signatur 0;
BA_ "GenSigFuncType" SG_ 2589284073 ORUG01_01_BZ 1;
BA_ "GenSigSendType" SG_ 2589284073 ORUG01_01_BZ 0;
BA_ "GenSigSwitchedByIgnition" SG_ 2589284073 ORUG01_01_BZ 0;
BA_ "GenSigFuncType" SG_ 2589284073 ORUG01_01_CRC 2;
BA_ "GenSigSendType" SG_ 2589284073 ORUG01_01_CRC 0;
BA_ "GenSigSwitchedByIgnition" SG_ 2589284073 ORUG01_01_CRC 0;
BA_ "GenSigSendType" SG_ 2589284073 ORUG1_Anforderung_HMS 0;
BA_ "GenSigSwitchedByIgnition" SG_ 2589284073 ORUG1_Anforderung_HMS 0;
BA_ "GenSigSendType" SG_ 2589284073 ORUG1_HVLock 0;
BA_ "GenSigSwitchedByIgnition" SG_ 2589284073 ORUG1_HVLock 0;
BA_ "GenSigSendType" SG_ 2589284073 ORUG1_HVReleased 0;
BA_ "GenSigSwitchedByIgnition" SG_ 2589284073 ORUG1_HVReleased 0;
BA_ "Fehlerwert" SG_ 2589284073 ORUG1_Parken_beibehalten_HMS 3;
BA_ "GenSigSendType" SG_ 2589284073 ORUG1_Parken_beibehalten_HMS 0;
BA_ "GenSigSwitchedByIgnition" SG_ 2589284073 ORUG1_Parken_beibehalten_HMS 0;
BA_ "GenSigSendType" SG_ 2589284073 ORUG1_TargetRelease 0;
BA_ "GenSigSwitchedByIgnition" SG_ 2589284073 ORUG1_TargetRelease 0;
BA_ "GenSigSendType" SG_ 2589284073 ORUG1_Warning 0;
BA_ "GenSigSwitchedByIgnition" SG_ 2589284073 ORUG1_Warning 0;
BA_ "GenSigFuncType" SG_ 2589284074 ORUG02_01_BZ 1;
BA_ "GenSigSendType" SG_ 2589284074 ORUG02_01_BZ 0;
BA_ "GenSigSwitchedByIgnition" SG_ 2589284074 ORUG02_01_BZ 0;
BA_ "GenSigFuncType" SG_ 2589284074 ORUG02_01_CRC 2;
BA_ "GenSigSendType" SG_ 2589284074 ORUG02_01_CRC 0;
BA_ "GenSigSwitchedByIgnition" SG_ 2589284074 ORUG02_01_CRC 0;
BA_ "GenSigSendType" SG_ 2589284074 ORUG2_GuardInfo 0;
BA_ "GenSigSwitchedByIgnition" SG_ 2589284074 ORUG2_GuardInfo 0;
BA_ "GenSigSendType" SG_ 2589284074 ORUG2_GuardState 0;
BA_ "GenSigSwitchedByIgnition" SG_ 2589284074 ORUG2_GuardState 0;
BA_ "GenSigSendType" SG_ 2589284074 ORUG2_TargetRelease 0;
BA_ "GenSigSwitchedByIgnition" SG_ 2589284074 ORUG2_TargetRelease 0;
BA_ "GenSigSendType" SG_ 2589284074 ORUG2_TorqueLock 0;
BA_ "GenSigSwitchedByIgnition" SG_ 2589284074 ORUG2_TorqueLock 0;
BA_REL_ "GenSigTimeoutTime" BU_SG_REL_ Fahrerdisplay_Kombi SG_ 2589283656 ORU_Status 5000;
BA_REL_ "GenSigTimeoutTime" BU_SG_REL_ Fahrerdisplay_Kombi SG_ 2589283656 ORU_Warnung 5000;
BA_REL_ "GenSigTimeoutTime" BU_SG_REL_ Fahrerdisplay_Kombi SG_ 2589284073 ORUG01_01_BZ 5000;
BA_REL_ "GenSigTimeoutTime" BU_SG_REL_ Fahrerdisplay_Kombi SG_ 2589284073 ORUG01_01_CRC 5000;
BA_REL_ "GenSigTimeoutTime" BU_SG_REL_ Fahrerdisplay_Kombi SG_ 2589284073 ORUG1_TargetRelease 5000;
BA_REL_ "GenSigTimeoutTime" BU_SG_REL_ Fahrerdisplay_Kombi SG_ 2589284073 ORUG1_Warning 5000;
BA_REL_ "GenSigTimeoutTime" BU_SG_REL_ Fahrerdisplay_Kombi SG_ 2589284074 ORUG02_01_BZ 5000;
BA_REL_ "GenSigTimeoutTime" BU_SG_REL_ Fahrerdisplay_Kombi SG_ 2589284074 ORUG02_01_CRC 5000;
BA_REL_ "GenSigTimeoutTime" BU_SG_REL_ Fahrerdisplay_Kombi SG_ 2589284074 ORUG2_TargetRelease 5000;
BA_REL_ "GenSigTimeoutTime" BU_SG_REL_ Fahrerdisplay_Kombi SG_ 2600468496 NM_Gateway_NM_State 2000;
BA_REL_ "GenSigTimeoutTime" BU_SG_REL_ Fahrerdisplay_Kombi SG_ 2600468500 NM_Kombi_NM_State 2000;
BA_REL_ "GenSigTimeoutTime" BU_SG_REL_ Fahrerdisplay_Kombi SG_ 2600468507 NM_HUD_NM_State 2000;
BA_REL_ "GenSigTimeoutTime" BU_SG_REL_ Fahrerdisplay_Kombi SG_ 2600468595 NM_Info_El_NM_State 2000;
BA_REL_ "GenSigTimeoutTime" BU_SG_REL_ Fahrerdisplay_Kombi SG_ 2600468748 NM_SmLi_01_NM_State 2000;
BA_REL_ "GenSigTimeoutTime" BU_SG_REL_ HUD SG_ 2589283656 ORU_Status 5000;
BA_REL_ "GenSigTimeoutTime" BU_SG_REL_ HUD SG_ 2589284073 ORUG01_01_BZ 5000;
BA_REL_ "GenSigTimeoutTime" BU_SG_REL_ HUD SG_ 2589284073 ORUG01_01_CRC 5000;
BA_REL_ "GenSigTimeoutTime" BU_SG_REL_ HUD SG_ 2589284073 ORUG1_TargetRelease 5000;
BA_REL_ "GenSigTimeoutTime" BU_SG_REL_ HUD SG_ 2589284074 ORUG02_01_BZ 5000;
BA_REL_ "GenSigTimeoutTime" BU_SG_REL_ HUD SG_ 2589284074 ORUG02_01_CRC 5000;
BA_REL_ "GenSigTimeoutTime" BU_SG_REL_ HUD SG_ 2589284074 ORUG2_TargetRelease 5000;
BA_REL_ "GenSigTimeoutTime" BU_SG_REL_ HUD SG_ 2600468496 NM_Gateway_NM_State 2000;
BA_REL_ "GenSigTimeoutTime" BU_SG_REL_ HUD SG_ 2600468500 NM_Kombi_NM_State 2000;
BA_REL_ "GenSigTimeoutTime" BU_SG_REL_ HUD SG_ 2600468595 NM_Info_El_NM_State 2000;
BA_REL_ "GenSigTimeoutTime" BU_SG_REL_ HUD SG_ 2600468745 NM_DispKBI_FS_NM_State 2000;
BA_REL_ "GenSigTimeoutTime" BU_SG_REL_ HUD SG_ 2600468748 NM_SmLi_01_NM_State 2000;
BA_REL_ "GenSigTimeoutTime" BU_SG_REL_ ICAS1_X_Gateway SG_ 2527679665 ND_Avrg_Speed_RangeData 2000;
BA_REL_ "GenSigTimeoutTime" BU_SG_REL_ ICAS1_X_Gateway SG_ 2589284094 Fahrerdisplay_Kombi_ORUData 5000;
BA_REL_ "GenSigTimeoutTime" BU_SG_REL_ ICAS1_X_Gateway SG_ 2589284094 Fahrerdisplay_Kombi_ORUDataIndex 5000;
BA_REL_ "GenSigTimeoutTime" BU_SG_REL_ ICAS1_X_Gateway SG_ 2589284094 ORU_007E_BZ 5000;
BA_REL_ "GenSigTimeoutTime" BU_SG_REL_ ICAS1_X_Gateway SG_ 2589284094 ORU_007E_CRC 5000;
BA_REL_ "GenSigTimeoutTime" BU_SG_REL_ ICAS1_X_Gateway SG_ 2589284095 HUD_ORUData 5000;
BA_REL_ "GenSigTimeoutTime" BU_SG_REL_ ICAS1_X_Gateway SG_ 2589284095 HUD_ORUDataIndex 5000;
BA_REL_ "GenSigTimeoutTime" BU_SG_REL_ ICAS1_X_Gateway SG_ 2589284095 ORU_0082_BZ 5000;
BA_REL_ "GenSigTimeoutTime" BU_SG_REL_ ICAS1_X_Gateway SG_ 2589284095 ORU_0082_CRC 5000;
BA_REL_ "GenSigTimeoutTime" BU_SG_REL_ ICAS1_X_Gateway SG_ 2600468500 NM_Kombi_CAB_V15 2000;
BA_REL_ "GenSigTimeoutTime" BU_SG_REL_ ICAS1_X_Gateway SG_ 2600468500 NM_Kombi_CBV_AWB 2000;
BA_REL_ "GenSigTimeoutTime" BU_SG_REL_ ICAS1_X_Gateway SG_ 2600468500 NM_Kombi_CBV_CRI 2000;
BA_REL_ "GenSigTimeoutTime" BU_SG_REL_ ICAS1_X_Gateway SG_ 2600468500 NM_Kombi_Car_Wakeup 2000;
BA_REL_ "GenSigTimeoutTime" BU_SG_REL_ ICAS1_X_Gateway SG_ 2600468507 NM_HUD_CAB_V15 2000;
BA_REL_ "GenSigTimeoutTime" BU_SG_REL_ ICAS1_X_Gateway SG_ 2600468507 NM_HUD_CBV_AWB 2000;
BA_REL_ "GenSigTimeoutTime" BU_SG_REL_ ICAS1_X_Gateway SG_ 2600468507 NM_HUD_CBV_CRI 2000;
BA_REL_ "GenSigTimeoutTime" BU_SG_REL_ ICAS1_X_Gateway SG_ 2600468507 NM_HUD_Car_WakeUp 2000;
BA_REL_ "GenSigTimeoutTime" BU_SG_REL_ ICAS1_X_Gateway SG_ 2600468595 NM_Info_El_CAB_V15 2000;
BA_REL_ "GenSigTimeoutTime" BU_SG_REL_ ICAS1_X_Gateway SG_ 2600468595 NM_Info_El_CBV_AWB 2000;
BA_REL_ "GenSigTimeoutTime" BU_SG_REL_ ICAS1_X_Gateway SG_ 2600468595 NM_Info_El_CBV_CRI 2000;
BA_REL_ "GenSigTimeoutTime" BU_SG_REL_ ICAS1_X_Gateway SG_ 2600468595 NM_Info_El_Car_Wakeup 2000;
BA_REL_ "GenSigTimeoutTime" BU_SG_REL_ ICAS1_X_Gateway SG_ 2600468745 NM_DispKBI_FS_CAB_V15 2000;
BA_REL_ "GenSigTimeoutTime" BU_SG_REL_ ICAS1_X_Gateway SG_ 2600468745 NM_DispKBI_FS_CBV_AWB 2000;
BA_REL_ "GenSigTimeoutTime" BU_SG_REL_ ICAS1_X_Gateway SG_ 2600468745 NM_DispKBI_FS_CBV_CRI 2000;
BA_REL_ "GenSigTimeoutTime" BU_SG_REL_ ICAS1_X_Gateway SG_ 2600468745 NM_DispKBI_FS_CarWakeup 2000;
BA_REL_ "GenSigTimeoutTime" BU_SG_REL_ ICAS1_X_Gateway SG_ 2600468748 NM_SmLi_01_CAB_V15 2000;
BA_REL_ "GenSigTimeoutTime" BU_SG_REL_ ICAS1_X_Gateway SG_ 2600468748 NM_SmLi_01_CBV_AWB 2000;
BA_REL_ "GenSigTimeoutTime" BU_SG_REL_ ICAS1_X_Gateway SG_ 2600468748 NM_SmLi_01_CBV_CRI 2000;
BA_REL_ "GenSigTimeoutTime" BU_SG_REL_ ICAS1_X_Gateway SG_ 2600468748 NM_SmLi_01_CarWakeup 2000;
BA_REL_ "GenSigTimeoutTime" BU_SG_REL_ ICAS3_Gateway SG_ 332 ISA_Regelung_aktiv 1000;
BA_REL_ "GenSigTimeoutTime" BU_SG_REL_ ICAS3_Gateway SG_ 332 OBD_Driving_Cycle 1000;
BA_REL_ "GenSigTimeoutTime" BU_SG_REL_ ICAS3_Gateway SG_ 332 OBD_Warm_Up_Cycle 1000;
BA_REL_ "GenSigTimeoutTime" BU_SG_REL_ ICAS3_Gateway SG_ 332 TSK_GRA_FoD_Status 1000;
BA_REL_ "GenSigTimeoutTime" BU_SG_REL_ ICAS3_Gateway SG_ 512 ISA_Tempolimit_Regelung 500;
BA_REL_ "GenSigTimeoutTime" BU_SG_REL_ ICAS3_Gateway SG_ 512 MO_Anzeige_Fahrbereitschaft 500;
BA_REL_ "GenSigTimeoutTime" BU_SG_REL_ ICAS3_Gateway SG_ 2331595982 PTUIPwrm_FacPwrDyn 500;
BA_REL_ "GenSigTimeoutTime" BU_SG_REL_ ICAS3_Gateway SG_ 2331595982 PTUIPwrm_PrctPeakPwrAvl 500;
BA_REL_ "GenSigTimeoutTime" BU_SG_REL_ ICAS3_Gateway SG_ 2331595982 PTUIPwrm_PrctPwrGnrMaxUse 500;
BA_REL_ "GenSigTimeoutTime" BU_SG_REL_ ICAS3_Gateway SG_ 2331595982 PTUIPwrm_PrctPwrMotMaxUse 500;
BA_REL_ "GenSigTimeoutTime" BU_SG_REL_ ICAS3_Gateway SG_ 2331595982 PTUIPwrm_PrctPwrSysCur 500;
BA_REL_ "GenSigTimeoutTime" BU_SG_REL_ ICAS3_Gateway SG_ 2331595982 PTUIPwrm_StAcv 500;
BA_REL_ "GenSigTimeoutTime" BU_SG_REL_ ICAS3_Gateway SG_ 2589283656 ORU_Status 5000;
BA_REL_ "GenSigTimeoutTime" BU_SG_REL_ ICAS3_Gateway SG_ 2589283672 SOK_ORU_01_Signatur 5000;
BA_REL_ "GenSigTimeoutTime" BU_SG_REL_ ICAS3_Gateway SG_ 2589283946 PTUIPwrm_PwrGnrNom 5000;
BA_REL_ "GenSigTimeoutTime" BU_SG_REL_ ICAS3_Gateway SG_ 2589283946 PTUIPwrm_PwrSysMotNomDisp 5000;
BA_REL_ "GenSigTimeoutTime" BU_SG_REL_ ICAS3_Gateway SG_ 2600468496 NM_Gateway_Car_Wakeup 2000;
BA_REL_ "GenSigTimeoutTime" BU_SG_REL_ ICAS3_Gateway SG_ 2600468496 NM_Gateway_NM_State 2000;
BA_REL_ "GenSigTimeoutTime" BU_SG_REL_ ICAS3_Gateway SG_ 2600468500 NM_Kombi_NM_State 2000;
BA_REL_ "GenSigTimeoutTime" BU_SG_REL_ ICAS3_Gateway SG_ 2600468507 NM_HUD_NM_State 2000;
BA_REL_ "GenSigTimeoutTime" BU_SG_REL_ ICAS3_Gateway SG_ 2600468745 NM_DispKBI_FS_NM_State 2000;
BA_REL_ "GenSigTimeoutTime" BU_SG_REL_ ICAS3_Gateway SG_ 2600468748 NM_SmLi_01_NM_State 2000;
BA_REL_ "GenSigTimeoutTime" BU_SG_REL_ ICC_IO_Node SG_ 2589283656 ORU_Status 5000;
BA_REL_ "GenSigTimeoutTime" BU_SG_REL_ ICC_IO_Node SG_ 2600468496 NM_Gateway_NM_State 2000;
BA_REL_ "GenSigTimeoutTime" BU_SG_REL_ ICC_IO_Node SG_ 2600468500 NM_Kombi_NM_State 2000;
BA_REL_ "GenSigTimeoutTime" BU_SG_REL_ ICC_IO_Node SG_ 2600468507 NM_HUD_NM_State 2000;
BA_REL_ "GenSigTimeoutTime" BU_SG_REL_ ICC_IO_Node SG_ 2600468745 NM_DispKBI_FS_NM_State 2000;
BA_REL_ "GenSigTimeoutTime" BU_SG_REL_ ICC_IO_Node SG_ 2600468748 NM_SmLi_01_NM_State 2000;
BA_REL_ "GenSigTimeoutTime" BU_SG_REL_ Kombi SG_ 332 ISA_Regelung_aktiv 1000;
BA_REL_ "GenSigTimeoutTime" BU_SG_REL_ Kombi SG_ 332 ISA_Status 1000;
BA_REL_ "GenSigTimeoutTime" BU_SG_REL_ Kombi SG_ 332 ISA_Tempolimitwarnung 1000;
BA_REL_ "GenSigTimeoutTime" BU_SG_REL_ Kombi SG_ 332 MO_Red_El_Fahrleistung 1000;
BA_REL_ "GenSigTimeoutTime" BU_SG_REL_ Kombi SG_ 332 TSK_vMax_aktuell 1000;
BA_REL_ "GenSigTimeoutTime" BU_SG_REL_ Kombi SG_ 512 MO_Anzeige_Fahrbereitschaft 500;
BA_REL_ "GenSigTimeoutTime" BU_SG_REL_ Kombi SG_ 512 MO_Text_Aktivierung_Antrieb 500;
BA_REL_ "GenSigTimeoutTime" BU_SG_REL_ Kombi SG_ 512 PEA_Fahrerinfo 500;
BA_REL_ "GenSigTimeoutTime" BU_SG_REL_ Kombi SG_ 512 TSK_Akustik 500;
BA_REL_ "GenSigTimeoutTime" BU_SG_REL_ Kombi SG_ 512 TSK_Fahrzeugstatus_GRA 500;
BA_REL_ "GenSigTimeoutTime" BU_SG_REL_ Kombi SG_ 512 TSK_Fahrzeugstatus_Limiter 500;
BA_REL_ "GenSigTimeoutTime" BU_SG_REL_ Kombi SG_ 512 TSK_Fahrzeugstatus_praed_Fkt 500;
BA_REL_ "GenSigTimeoutTime" BU_SG_REL_ Kombi SG_ 512 TSK_Limiter_Anzeige 500;
BA_REL_ "GenSigTimeoutTime" BU_SG_REL_ Kombi SG_ 512 TSK_Limiter_Fahrerinfo 500;
BA_REL_ "GenSigTimeoutTime" BU_SG_REL_ Kombi SG_ 512 TSK_Status_Anzeige 500;
BA_REL_ "GenSigTimeoutTime" BU_SG_REL_ Kombi SG_ 512 TSK_Texte 500;
BA_REL_ "GenSigTimeoutTime" BU_SG_REL_ Kombi SG_ 512 TSK_Texte_Primaeranz 500;
BA_REL_ "GenSigTimeoutTime" BU_SG_REL_ Kombi SG_ 512 TSK_Wunschgeschw 500;
BA_REL_ "GenSigTimeoutTime" BU_SG_REL_ Kombi SG_ 512 TSK_naechstes_Event 500;
BA_REL_ "GenSigTimeoutTime" BU_SG_REL_ Kombi SG_ 512 TSK_praed_Wunschgeschw 500;
BA_REL_ "GenSigTimeoutTime" BU_SG_REL_ Kombi SG_ 512 TSK_praediktiver_Hinweis 500;
BA_REL_ "GenSigTimeoutTime" BU_SG_REL_ Kombi SG_ 1155 MO_Powermeter_Charge_Grenze 5000;
BA_REL_ "GenSigTimeoutTime" BU_SG_REL_ Kombi SG_ 1155 MO_Powermeter_Grenze_strategisch 5000;
BA_REL_ "GenSigTimeoutTime" BU_SG_REL_ Kombi SG_ 1155 Mo_Powermeter_Grenze 5000;
BA_REL_ "GenSigTimeoutTime" BU_SG_REL_ Kombi SG_ 2331595982 PTUIPwrm_FacPwrDyn 500;
BA_REL_ "GenSigTimeoutTime" BU_SG_REL_ Kombi SG_ 2331595982 PTUIPwrm_PrctPwrGnrMaxUse 500;
BA_REL_ "GenSigTimeoutTime" BU_SG_REL_ Kombi SG_ 2331595982 PTUIPwrm_PrctPwrMotMaxUse 500;
BA_REL_ "GenSigTimeoutTime" BU_SG_REL_ Kombi SG_ 2331595982 PTUIPwrm_PrctPwrSysCur 500;
BA_REL_ "GenSigTimeoutTime" BU_SG_REL_ Kombi SG_ 2331595982 PTUIPwrm_StAcv 500;
BA_REL_ "GenSigTimeoutTime" BU_SG_REL_ Kombi SG_ 2463978666 MO_Rekuperation_EM_Ges_Ueberlauf 1000;
BA_REL_ "GenSigTimeoutTime" BU_SG_REL_ Kombi SG_ 2463978666 MO_Rekuperation_Ges_EM 1000;
BA_REL_ "GenSigTimeoutTime" BU_SG_REL_ Kombi SG_ 2463978666 MO_Verbrauch_EM_Ges 1000;
BA_REL_ "GenSigTimeoutTime" BU_SG_REL_ Kombi SG_ 2463978666 MO_Verbrauch_EM_Ges_Ueberlauf 1000;
BA_REL_ "GenSigTimeoutTime" BU_SG_REL_ Kombi SG_ 2589283656 ORU_Warnung 5000;
BA_REL_ "GenSigTimeoutTime" BU_SG_REL_ Kombi SG_ 2589283946 PTUIPwrm_PwrGnrNom 5000;
BA_REL_ "GenSigTimeoutTime" BU_SG_REL_ Kombi SG_ 2589283946 PTUIPwrm_PwrSysMotNomDisp 5000;
BA_REL_ "GenSigTimeoutTime" BU_SG_REL_ Kombi SG_ 2600468496 NM_Gateway_NM_State 2000;
BA_REL_ "GenSigTimeoutTime" BU_SG_REL_ Kombi SG_ 2600468507 NM_HUD_NM_State 2000;
BA_REL_ "GenSigTimeoutTime" BU_SG_REL_ Kombi SG_ 2600468595 NM_Info_El_NM_State 2000;
BA_REL_ "GenSigTimeoutTime" BU_SG_REL_ Kombi SG_ 2600468745 NM_DispKBI_FS_NM_State 2000;
BA_REL_ "GenSigTimeoutTime" BU_SG_REL_ Kombi SG_ 2600468748 NM_SmLi_01_NM_State 2000;
BA_REL_ "GenSigTimeoutTime" BU_SG_REL_ SmartLight_01 SG_ 2589283656 ORU_Status 5000;
BA_REL_ "GenSigTimeoutTime" BU_SG_REL_ SmartLight_01 SG_ 2600468496 NM_Gateway_NM_State 2000;
BA_REL_ "GenSigTimeoutTime" BU_SG_REL_ SmartLight_01 SG_ 2600468500 NM_Kombi_NM_State 2000;
BA_REL_ "GenSigTimeoutTime" BU_SG_REL_ SmartLight_01 SG_ 2600468507 NM_HUD_NM_State 2000;
BA_REL_ "GenSigTimeoutTime" BU_SG_REL_ SmartLight_01 SG_ 2600468595 NM_Info_El_NM_State 2000;
BA_REL_ "GenSigTimeoutTime" BU_SG_REL_ SmartLight_01 SG_ 2600468745 NM_DispKBI_FS_NM_State 2000;
BA_REL_ "GenSigTimeoutTime" BU_SG_REL_ ZR_MIB_TOP_ab_Gen3 SG_ 332 ISA_Regelung_aktiv 1000;
BA_REL_ "GenSigTimeoutTime" BU_SG_REL_ ZR_MIB_TOP_ab_Gen3 SG_ 332 ISA_Status 1000;
BA_REL_ "GenSigTimeoutTime" BU_SG_REL_ ZR_MIB_TOP_ab_Gen3 SG_ 332 ISA_Tempolimitwarnung 1000;
BA_REL_ "GenSigTimeoutTime" BU_SG_REL_ ZR_MIB_TOP_ab_Gen3 SG_ 332 OBD_Driving_Cycle 1000;
BA_REL_ "GenSigTimeoutTime" BU_SG_REL_ ZR_MIB_TOP_ab_Gen3 SG_ 332 OBD_Warm_Up_Cycle 1000;
BA_REL_ "GenSigTimeoutTime" BU_SG_REL_ ZR_MIB_TOP_ab_Gen3 SG_ 512 TSK_Fahrzeugstatus_GRA 500;
BA_REL_ "GenSigTimeoutTime" BU_SG_REL_ ZR_MIB_TOP_ab_Gen3 SG_ 512 TSK_Fahrzeugstatus_Limiter 500;
BA_REL_ "GenSigTimeoutTime" BU_SG_REL_ ZR_MIB_TOP_ab_Gen3 SG_ 512 TSK_Fahrzeugstatus_praed_Fkt 500;
BA_REL_ "GenSigTimeoutTime" BU_SG_REL_ ZR_MIB_TOP_ab_Gen3 SG_ 512 TSK_Limiter_Anzeige 500;
BA_REL_ "GenSigTimeoutTime" BU_SG_REL_ ZR_MIB_TOP_ab_Gen3 SG_ 512 TSK_Limiter_Fahrerinfo 500;
BA_REL_ "GenSigTimeoutTime" BU_SG_REL_ ZR_MIB_TOP_ab_Gen3 SG_ 512 TSK_Status_Anzeige 500;
BA_REL_ "GenSigTimeoutTime" BU_SG_REL_ ZR_MIB_TOP_ab_Gen3 SG_ 512 TSK_Texte_Primaeranz 500;
BA_REL_ "GenSigTimeoutTime" BU_SG_REL_ ZR_MIB_TOP_ab_Gen3 SG_ 512 TSK_Wunschgeschw 500;
BA_REL_ "GenSigTimeoutTime" BU_SG_REL_ ZR_MIB_TOP_ab_Gen3 SG_ 512 TSK_naechstes_Event 500;
BA_REL_ "GenSigTimeoutTime" BU_SG_REL_ ZR_MIB_TOP_ab_Gen3 SG_ 512 TSK_praed_Wunschgeschw 500;
BA_REL_ "GenSigTimeoutTime" BU_SG_REL_ ZR_MIB_TOP_ab_Gen3 SG_ 512 TSK_praediktiver_Hinweis 500;
BA_REL_ "GenSigTimeoutTime" BU_SG_REL_ ZR_MIB_TOP_ab_Gen3 SG_ 2600468496 NM_Gateway_Car_Wakeup 2000;
BA_REL_ "GenSigTimeoutTime" BU_SG_REL_ ZR_MIB_TOP_ab_Gen3 SG_ 2600468496 NM_Gateway_NM_State 2000;
BA_REL_ "GenSigTimeoutTime" BU_SG_REL_ ZR_MIB_TOP_ab_Gen3 SG_ 2600468500 NM_Kombi_NM_State 2000;
BA_REL_ "GenSigTimeoutTime" BU_SG_REL_ ZR_MIB_TOP_ab_Gen3 SG_ 2600468507 NM_HUD_NM_State 2000;
BA_REL_ "GenSigTimeoutTime" BU_SG_REL_ ZR_MIB_TOP_ab_Gen3 SG_ 2600468745 NM_DispKBI_FS_NM_State 2000;
BA_REL_ "GenSigTimeoutTime" BU_SG_REL_ ZR_MIB_TOP_ab_Gen3 SG_ 2600468748 NM_SmLi_01_NM_State 2000;
VAL_ 512 ISA_Tempolimit_Regelung 0 "Init" 1 "Tempolimit_5" 2 "Tempolimit_10" 3 "Tempolimit_15" 4 "Tempolimit_20" 5 "Tempolimit_25" 6 "Tempolimit_30" 7 "Tempolimit_35" 8 "Tempolimit_40" 9 "Tempolimit_45" 10 "Tempolimit_50" 11 "Tempolimit_55" 12 "Tempolimit_60" 13 "Tempolimit_65" 14 "Tempolimit_70" 15 "Tempolimit_75" 16 "Tempolimit_80" 17 "Tempolimit_90" 18 "Tempolimit_100" 19 "Tempolimit_110" 20 "Tempolimit_120" 21 "Tempolimit_130" 22 "Tempolimit_140" 23 "Tempolimit_150" 24 "Tempolimit_160" 25 "Tempolimit_unbegrenzt" 26 "Linkskurve" 27 "Rechtskurve" 28 "Kuppe" 29 "Steigung" 30 "Gefaelle" 31 "Kreuzung" 32 "Ampel" 33 "Bahnuebergang" 34 "Ortsanfang" 35 "Kreisverkehr" 36 "naechstes_Limit_ausserh_Verfueg" ;
VAL_ 512 MO_Antriebsstrang_Warnung_HS 0 "Keine_Anzeige" 1 "Fehlereskalationsstufe_I" 2 "Fehlereskalationsstufe_II" 3 "Fehlereskalationsstufe_III" ;
VAL_ 512 MO_Anzeige_Betriebsmodus 0 "Init_keine_Anzeige" 1 "EV" 2 "Auto" 3 "Hold" 4 "Charge" 5 "GTE" 6 "ECO" 7 "SPORT" 8 "Auto_praediktiv" 9 "Manuell_SOC_erhoehen" 10 "Manuell_SOC_halten" 11 "Manuell_SOC_verringern" ;
VAL_ 512 MO_Anzeige_Fahrbereitschaft 0 "OFF" 1 "READY" ;
VAL_ 512 MO_Anzeige_Rekuperation 0 "Init_und_nicht_verbaut" ;
VAL_ 512 MO_Boost_aktiv 0 "kein_Boost_aktiv" 1 "Boost_aktiv" ;
VAL_ 512 MO_Boost_verfuegbar 0 "Init" 253 "Nicht_verbaut" 254 "Funktion_deaktiv" 255 "Fehler" ;
VAL_ 512 MO_BZS_Charisma_FahrPr 0 "keine_Funktion" 1 "Programm_1" 2 "Programm_2" 3 "Programm_3" 4 "Programm_4" 5 "Programm_5" 6 "Programm_6" 7 "Programm_7" 8 "Programm_8" 9 "Programm_9" 10 "Programm_10" 11 "Programm_11" 12 "Programm_12" 13 "Programm_13" 14 "Programm_14" 15 "Programm_15" ;
VAL_ 512 MO_BZS_Charisma_Status 0 "Init" 1 "verfuegbar" 2 "nicht_verfuegbar" 3 "asynchron_durch_Fahrerwunsch" ;
VAL_ 512 MO_Charisma_FahrPr 0 "keine_Funktion" 1 "Programm_1" 2 "Programm_2" 3 "Programm_3" 4 "Programm_4" 5 "Programm_5" 6 "Programm_6" 7 "Programm_7" 8 "Programm_8" 9 "Programm_9" 10 "Programm_10" 11 "Programm_11" 12 "Programm_12" 13 "Programm_13" 14 "Programm_14" 15 "Programm_15" ;
VAL_ 512 MO_Charisma_Status 0 "Init" 1 "verfuegbar" 2 "nicht_verfuegbar" 3 "asynchron_durch_Fahrerwunsch" ;
VAL_ 512 MO_Luftpfad_aktiv 0 "kein Eingriff oder nur Eingriff ï?½ber Zï?½ndpfad" 1 "Eingriff ï?½ber Luftpfad" ;
VAL_ 512 MO_Motorlaufwarnung 0 "keine_Anzeige" 1 "Anforderung_Motorlaufwarnung" ;
VAL_ 512 MO_NGS_Position 0 "Neutralposition_nicht_erkannt" 1 "Neutralposition_erkannt" ;
VAL_ 512 MO_NGS_Status 0 "nicht_verbaut" 1 "nicht_plausibilisiert" 2 "plausibilisiert" 3 "Fehler" ;
VAL_ 512 MO_Overboost 0 "inaktiv" 1 "aktiv" ;
VAL_ 512 MO_Prio_MAX_Wunschdrehzahl 0 "Wunsch" 1 "Zwang" ;
VAL_ 512 MO_Prio_MIN_Wunschdrehzahl 0 "Wunsch" 1 "Zwang" ;
VAL_ 512 MO_Rampenzeit_Generator_Anf 0 "0_sec" 1 "1_sec" 2 "2_sec" 3 "3_sec" 4 "4_sec" 5 "5_sec" 6 "6_sec" 7 "7_sec" 8 "8_sec" 9 "9_sec" 10 "reserviert" 11 "reserviert" 12 "reserviert" 13 "reserviert" 14 "reserviert" 15 "keine_Anforderung" ;
VAL_ 512 MO_Sperrung_FahrPr_BZS 0 "keine Sperrung" 1 "Sperrung BZS1" 2 "Sperrung BZS2" 4 "Sperrung BZS3" 8 "Sperrung BZS4" 16 "Sperrung BZS5" 32 "Sperrung BZS6" 64 "Sperrung BZS7" 128 "Sperrung BZS8" ;
VAL_ 512 MO_StSt_Charisma_FahrPr 0 "keine_Funktion" 1 "Programm_1" 2 "Programm_2" 3 "Programm_3" 4 "Programm_4" 5 "Programm_5" 6 "Programm_6" 7 "Programm_7" 8 "Programm_8" 9 "Programm_9" 10 "Programm_10" 11 "Programm_11" 12 "Programm_12" 13 "Programm_13" 14 "Programm_14" 15 "Programm_15" ;
VAL_ 512 MO_StSt_Charisma_Status 0 "Init" 1 "verfuegbar" 2 "nicht_verfuegbar" 3 "asynchron_durch_Fahrerwunsch" ;
VAL_ 512 MO_Text_Aktivierung_Antrieb 0 "keine_Anzeige" 1 "Ladestecker_nicht_fahrbereit" 2 "erneute_Aktivierung_erforderlich" 3 "Warten_Antrieb_wird_aktiviert" 4 "zum_Fahren_Bremse_und_Fahrstufe" 5 "h2_Tankklappe_nicht_fahrbereit" 6 "zum_Starten_Bremse_treten" 7 "zum_Starten_Kupplung_treten" 15 "Init" ;
VAL_ 512 MO_v_Begrenz_Aktivierbar 0 "V-Begrenzung nicht mï?½glich" 1 "V-Begrenzung mï?½glich" ;
VAL_ 512 MO_v_Begrenzung_Niveau 0 "keine_Begrenzung_aktiv" 1 "Sicherheitsbegrenzung_1_aktiv" 2 "Sicherheitsbegrenzung_2_aktiv" 3 "Komfortbegrenzung_aktiv" ;
VAL_ 512 PEA_Abschalttexte 0 "keine_Anzeige" 1 "PEA_ausserhalb_Einsatzgebiet" 2 "PEA_temporaer_nicht_verfuegbar" 3 "PEA_vom_Fahrer_deaktiviert" ;
VAL_ 512 PEA_Ereignisanzeige 0 "keine_Anzeige" 1 "Linkskurve_voraus" 2 "Rechtskurve_voraus" 3 "Kreuzung_voraus" 4 "Gefaelle_voraus" 5 "Kreisverkehr_voraus" 6 "Fahrzeug_voraus" 7 "Tempolimit_voraus" 8 "Ereignis_voraus" 9 "Autobahnabfahrt_voraus" 10 "Autobahnauffahrt_voraus" 11 "Abbiegung_links_voraus" 12 "Abbiegung_rechts_voraus" 13 "Ortseinfahrt_voraus" 14 "Autobahnabfahrt_links_voraus" ;
VAL_ 512 PEA_Ereignisanzeige_temporaer 0 "keine_Anzeige" 1 "Anzeige_temporaer" ;
VAL_ 512 PEA_Fahrerinfo 0 "keine_Anzeige" 1 "Anzeige_Fahreruebernahme_hart" 2 "Anzeige_Fahreruebernahme_medium" 3 "Anzeige_Fahreruebernahme_soft" 4 "Anzeige_Fahreruebernahme_Popup" 5 "Fehleranzeige_FAS_Sammelmeldung" ;
VAL_ 512 PEA_Fortschrittsanzeige 127 "Neutralwert" ;
VAL_ 512 PEA_Hinweis 0 "keine_Anzeige" 1 "Anzeige_Fusssymbol_1" 2 "Anzeige_Fusssymbol_2" 3 "Anzeige_Auskuppeln" ;
VAL_ 512 PEA_Zielgeschw 0 "keine_Anzeige" 1 "Wert_5" 2 "Wert_10" 3 "Wert_15" 4 "Wert_20" 5 "Wert_25" 6 "Wert_30" 7 "Wert_35" 8 "Wert_40" 9 "Wert_45" 10 "50" 11 "Wert_55" 12 "Wert_60" 13 "Wert_65" 14 "Wert_70" 15 "Wert_75" 16 "Wert_80" 17 "Wert_85" 18 "Wert_90" 19 "Wert_95" 20 "Wert_100" 21 "Wert_105" 22 "Wert_110" 23 "Wert_115" 24 "Wert_120" 25 "Wert_125" 26 "Wert_130" 27 "Wert_140" 28 "Wert_150" 29 "Wert_160" ;
VAL_ 512 PEA_Zielgeschw_Einheit 0 "km_h" 1 "mph" ;
VAL_ 512 TSK_Akustik 0 "keine_Akustik" 1 "einzelner_Warnton" 2 "dauerhafter_Warnton" ;
VAL_ 512 TSK_Fahrzeugstatus_GRA 0 "GRA_verfuegbar" 1 "GRA_nicht_verfuegbar" ;
VAL_ 512 TSK_Fahrzeugstatus_Limiter 0 "Limiter_verfuegbar" 1 "Limiter_nicht_verfuegbar" ;
VAL_ 512 TSK_Fahrzeugstatus_praed_Fkt 0 "init" 1 "Praed_Fkt_verfuegbar" 2 "Praed_Fkt_eingeschraenkt_verfueg" 3 "Praed_Fkt_nicht_verfuegbar" 4 "Praed_Fkt_Land_nicht_verfuegbar" 5 "Praed_Fkt_Auffahrt" 6 "Praed_Fkt_Abfahrt" 7 "Praed_Fkt_Regelbereich_verlassen" ;
VAL_ 512 TSK_Limiter_Anzeige 0 "Display_Anzeige_GRA_ACC" 1 "Display_Anzeige_Limiter" ;
VAL_ 512 TSK_Limiter_Fahrerinfo 0 "keine_Info" 1 "Limit_erreicht" 2 "Ueberschritten" 3 "Vom_Fahrer_Ueberstimmt" ;
VAL_ 512 TSK_naechstes_Event 0 "Init" 1 "Tempolimit_5" 2 "Tempolimit_10" 3 "Tempolimit_15" 4 "Tempolimit_20" 5 "Tempolimit_25" 6 "Tempolimit_30" 7 "Tempolimit_35" 8 "Tempolimit_40" 9 "Tempolimit_45" 10 "Tempolimit_50" 11 "Tempolimit_55" 12 "Tempolimit_60" 13 "Tempolimit_65" 14 "Tempolimit_70" 15 "Tempolimit_75" 16 "Tempolimit_80" 17 "Tempolimit_90" 18 "Tempolimit_100" 19 "Tempolimit_110" 20 "Tempolimit_120" 21 "Tempolimit_130" 22 "Tempolimit_140" 23 "Tempolimit_150" 24 "Tempolimit_160" 25 "Tempolimit_unbegrenzt" 26 "Linkskurve" 27 "Rechtskurve" 28 "Kuppe" 29 "Steigung" 30 "Gefaelle" 31 "Kreuzung" 32 "Ampel" 33 "Bahnuebergang" 34 "Ortsanfang" 35 "Kreisverkehr" 36 "naechstes_Limit_ausserh_Verfueg" ;
VAL_ 512 TSK_naechstes_Event_Einheit 0 "kmh" 1 "mph" ;
VAL_ 512 TSK_praed_Wunschgeschw 1022 "keine_Anzeige" 1023 "kein_praed_Setzwert_verfuegbar" ;
VAL_ 512 TSK_praediktiver_Automode 0 "Automode_inaktiv" 1 "Automode_aktiv" ;
VAL_ 512 TSK_praediktiver_Hinweis 0 "keine_Anzeige" 1 "Vorschlag_zur_Bestaetigung" 2 "Hinweis_neuer_Setzwert" 3 "Regelung_im_Uebergang" 4 "Tempolimit_voraus" 5 "Tempolimit_erkannt" ;
VAL_ 512 TSK_Status_Anzeige 0 "Hauptschalter_aus" 1 "Init" 2 "passiv" 3 "aktiv" 4 "Uebertreten" 5 "Limitiierung_aktiv" 6 "reversibel_aus" 7 "irreversibel_aus" ;
VAL_ 512 TSK_Texte 0 "kein_Text" 1 "GRA_Modus_ausgewaehlt" 2 "ACC_Modus_ausgewaehlt" 3 "Lim_Modus_ausgewaehlt" 4 "Lim_nicht_verfuegbar_ESC_passiv" 5 "GRA_nicht_verfuegbar_ESC_passiv" 6 "Lim_nicht_verfuegbar_Charisma" 7 "GRA_nicht_verfuegbar_Charisma" 8 "Lim_nicht_verfuegbar_HDC" 9 "GRA_nicht_verfuegbar_HDC" 10 "P_GRA_Modus_ausgewaehlt" 11 "P_LIM_Modus_ausgewaehlt" 12 "Bremse_ueberhitzt" 13 "kein_Laengsregler" 14 "kein_Abstandsregler" 15 "keine_Abstandsregelung" 16 "Bitte_Hauptschalter_einschalten" ;
VAL_ 512 TSK_Texte_Primaeranz 0 "keine_Anzeige" 1 "GRA_Symbol_passiv_xxx_kmh_mph" 2 "GRA_Symbol_aktiv_xxx_kmh_mph" 3 "Bremse_ueberhitzt" 4 "Limiter_Modus_aktiviert" 5 "GRA_Modus_aktiviert" 6 "ACC_Modus_aktiviert" 7 "Opt_Geschwindigkeitswarnung" 8 "Opt_und_akustische_GeschwWarnung" 9 "Opt_GeschwWarnung_dauerhaft_mit_einmal_Akustik" 10 "Limiter_passiv_mit_Akustik" 11 "Limiter_Fehler_mit_Akustik" 12 "Limiter_Symbol_passiv_xxx_kmh_mph" 13 "Limiter_Symbol_aktiv_xxx_kmh_mph" 14 "Popup_Geschw_zu_hoch__Resume_unzulaessig" ;
VAL_ 512 TSK_Wunschgeschw 1022 "keine_Anzeige" 1023 "kein_Wert_im_Speicher" ;
VAL_ 332 FoD_DTC_TSK_ACC 0 "Kein_DTC" 1 "DTC_vorhanden_oder_in_Quali" ;
VAL_ 332 FoD_DTC_TSK_GRA 0 "Kein_DTC" 1 "DTC_vorhanden_oder_in_Quali" ;
VAL_ 332 ISA_Regelung_aktiv 0 "ISA_Regelung_nicht_aktiv" 1 "ISA_Regelung_aktiv" ;
VAL_ 332 ISA_Status 0 "ISA_nicht_aktiv" 1 "Init" 2 "ISA_degradiert" 3 "ISA_aktiv" 4 "reserviert" 5 "reserviert" 6 "reserviert" 7 "reserviert" ;
VAL_ 332 ISA_Tempolimitwarnung 0 "ISA_keine_Warnung" 1 "ISA_Warnung_aktiv" ;
VAL_ 332 KVA_Ist_Pos 126 "Init" 127 "Fehler" ;
VAL_ 332 MO_Anforderung_Anzeige_Halten 0 "Keine_Anzeige_Halten" 1 "Anzeige_Halten" ;
VAL_ 332 MO_Anforderung_HMS 0 "keine_Anforderung" 1 "halten" 2 "parken" 3 "halten_Standby" 4 "anfahren" 5 "Loesen_ueber_Rampe" 7 "HMS_uebernehmen" ;
VAL_ 332 MO_EBoost_verf_praed 0 "Init_oder_nicht_verfuegbar" 1 "EBoost_kurzzeit_verfuegbar" 2 "EBoost_langzeit_verfuegbar" ;
VAL_ 332 MO_eLaunch_verf 0 "Init" 1 "nicht_verfuegbar" 2 "verfuegbar" ;
VAL_ 332 MO_Fahrbereitschaft 0 "Fahrzykl_inaktiv__kein_Antrieb" 1 "Fahrzykl_aktiv__kein_Antrieb" 2 "Fahrzykl_aktiv__Antrieb_moeglich" ;
VAL_ 332 MO_Freilauf_Info 0 "Freilauf_freigegeben" 1 "Weiches_Veto_uebertippbar" 2 "Hartes_Veto_Abbruch" 3 "Freilauf_Anforderung" ;
VAL_ 332 MO_Freilauf_Status 0 "Freilauf_inaktiv_aber_moeglich" 1 "Freilauf_aktiv" 2 "Freilauf_nicht_moegl_1Verhinderer" 3 "Freilauf_nicht_moegl_gr_1Verhinderer" 7 "Fehler" ;
VAL_ 332 MO_Heckspoiler_Anf 0 "nicht_angefordert" 1 "angefordert" ;
VAL_ 332 MO_Klima_Regelmodus 0 "Init" 1 "Regelmodus_1" 2 "Regelmodus_2" 3 "Regelmodus_3" ;
VAL_ 332 MO_Krit_Heckobjekt 0 "Init_kein_relevantes_Objekt" 1 "Entfernung_grosser_Abstand" 2 "Annaeherung_grosser_Abstand" 3 "Entfernung_geringer_Abstand" 4 "Annaeherung_geringer_Abstand" 7 "Fehler" ;
VAL_ 332 MO_LaunchControl 0 "nicht_verfuegbar" 1 "verfuegbar" ;
VAL_ 332 MO_NGS_Gangpos 0 "nicht_bedient" 1 "1_3_oder_5" 2 "2_4_6_oder_R" 3 "R" 4 "Neutralposition" 5 "Zwischenposition" 6 "Sensor_temp_nicht_verfuegbar" 7 "Fehler" ;
VAL_ 332 MO_OnePedal_Verzoegerungsstufe 0 "Fahrstufe_B_inaktiv" 1 "Verzoegerungsstufe_1" 2 "Verzoegerungsstufe_2" 3 "Reserve_01" 4 "Reserve_02" 7 "Fehler" ;
VAL_ 332 MO_Positionierung_aktiv 0 "keine_Positionierung_aktiv" 1 "Positionierung_aktiv" ;
VAL_ 332 MO_QBit_Aussen_Temp 0 "gueltiger_Wert" 1 "Ersatz_Init_oder_Fehlerwert" ;
VAL_ 332 MO_Red_El_Fahrleistung 0 "keine_Anzeige" 1 "mehr_als_20Prcnt_Red" 2 "Reserve_1" 3 "Reserve_2" 4 "unter_GBB_Schwelle_Anhaenger" 5 "unter_GBB_Schwelle" 6 "unter_minimal_Schwelle" 7 "kein_Vortrieb" ;
VAL_ 332 MO_Servicemodus 0 "nicht_aktiv" 1 "Service_Mode_1" 2 "Service_Mode_2" 3 "Service_Mode_3" 4 "Service_Mode_4" 5 "Service_Mode_5" 6 "Service_Mode_6" 7 "Service_Mode_7" 8 "Service_Mode_8" 9 "Service_Mode_9" 10 "Service_Mode_10" 11 "Service_Mode_11" 12 "Service_Mode_12" 13 "Service_Mode_13" 14 "Service_Mode_14" 15 "Service_Mode_15" ;
VAL_ 332 MO_Startwunsch 0 "kein_Startwunsch" 1 "Startwunsch" ;
VAL_ 332 MO_UBE_Reserve 1023 "Init" ;
VAL_ 332 OBD_Aussen_Temp_gef 254 "Initwert" 255 "Fehler" ;
VAL_ 332 OBD_ClearMem_Inhibit 0 "FSP_Loeschen_zulaessig" 1 "FSP_Loeschen_nicht_zulaessig" ;
VAL_ 332 OBD_Driving_Cycle 0 "kein_Driving_Cycle_erkannt" 1 "Driving_Cycle_erkannt" ;
VAL_ 332 OBD_Kaltstart_Denominator 0 "Denominator_nicht_hochzaehlen" 1 "Bedingungen_zum_Inkr_des_Kaltstart_Denom_erf" ;
VAL_ 332 OBD_Minimum_Trip 0 "kein_Min_Normed_Trip" 1 "Min_Normed_Trip" ;
VAL_ 332 OBD_Normed_Trip 0 "kein_Normed_Trip" 1 "Normed_Trip" ;
VAL_ 332 OBD_Sperrung_IUMPR 0 "IUMPR_Berechnung_freigegeben" 1 "IUMPR_Berechnung_gesperrt" ;
VAL_ 332 OBD_Sperrung_Kaltstart_Denom 0 "EVAP_Berechnung_freigegeben" 1 "EVAP_Berechnung_gesperrt" ;
VAL_ 332 OBD_Warm_Up_Cycle 0 "kein_Warm_Up_Cycle_erkannt" 1 "Warm_Up_Cycle_erkannt" ;
VAL_ 332 TSK_ACC_FoD_Status 0 "default" 1 "nicht_aktiv" 2 "aktiv" 3 "nicht_genutzt" ;
VAL_ 332 TSK_aktives_System 0 "keine_Funktion_aktiv" 1 "GRA_ACC" 2 "ARA" 3 "Speedlimiter" 4 "IPA" 5 "PLA" 6 "PEA_Ausrollassistent" 7 "EA" ;
VAL_ 332 TSK_Anf_Antriebsmoment 0 "keine_Anforderung" 1 "Anforderung_aktiv" ;
VAL_ 332 TSK_Einheit_vMax_Fahrerassistenz 0 "kmh" 1 "mph" ;
VAL_ 332 TSK_erhoehter_Fahrwiderstand 0 "kein_erhoehter_Fahrwiderstand" 1 "erhoehter_Fahrwiderstand" ;
VAL_ 332 TSK_GRA_FoD_Status 0 "default" 1 "nicht_aktiv" 2 "aktiv" 3 "nicht_genutzt" ;
VAL_ 332 TSK_Status_ARA 0 "Aus" 1 "Init_oder_nicht_verbaut" 2 "aktivierbar" 3 "aktiv" 5 "abschaltung_laeuft" 6 "reversibel_aus" 7 "Fehler" ;
VAL_ 332 TSK_Status_EA 0 "Aus" 1 "Init_oder_nicht_verbaut" 3 "Aktiv" 4 "Uebertreten" 5 "Abschaltung_laeuft" 6 "Reversibel_aus" 7 "Fehler" ;
VAL_ 332 TSK_Status_IPA 0 "Aus_Funktionsbereit" 1 "Init_oder_nicht_verbaut" 2 "aktivierbar" 3 "aktiv" 4 "Fahreruebernahme_angefordert" 5 "Abschaltung_laueft" 6 "reversibel_aus" 7 "Fehler" ;
VAL_ 332 TSK_Status_PLA 0 "Aus_Funktionsbereit" 1 "Init_oder_nicht_verbaut" 2 "aktivierbar" 3 "aktiv" 5 "Abschaltung_laeuft" 6 "reversibel_aus" 7 "Fehler" ;
VAL_ 332 TSK_vMax_aktuell 254 "kein_Limit_aktiv" 255 "Init" ;
VAL_ 332 TSK_vMax_Fahrerassistenz 511 "Init_ungueltig_keine_Beschraenkung" ;
VAL_ 2463978666 MO_Drehzahl_EM 8190 "Init_nichtverbaut" 8191 "Fehler" ;
VAL_ 2463978666 MO_Drehzahl_EM_sek 8190 "Init_nichtverbaut" 8191 "Fehler" ;
VAL_ 2463978666 MO_EM1_Generator_Leistung 254 "Init" 255 "Fehler" ;
VAL_ 2463978666 MO_EM1_Max_Leistung_Gesamt 8190 "Init" ;
VAL_ 2463978666 MO_EM1_Max_Spannung_Lim 1022 "Init" ;
VAL_ 2463978666 MO_EM1_Min_Leistung_Gesamt 8190 "Init" ;
VAL_ 2463978666 MO_EM1_Min_Spannung_Lim 1022 "Init" ;
VAL_ 2463978666 MO_EM2_Generator_Leistung 254 "Init" 255 "Fehler" ;
VAL_ 2463978666 MO_EM2_Max_Leistung_Gesamt 8190 "Init" ;
VAL_ 2463978666 MO_EM2_Max_Spannung_Lim 1022 "Init" ;
VAL_ 2463978666 MO_EM2_Min_Leistung_Gesamt 8190 "Init" ;
VAL_ 2463978666 MO_EM2_Min_Spannung_Lim 1022 "Init" ;
VAL_ 2463978666 MO_Rekuperation_EM_Ges_Ueberlauf 0 "kein_Ueberlauf" 1 "Ueberlauf_Reku_Leistungssignal" ;
VAL_ 2463978666 MO_Uebersetzung_EM 0 "keine_sichere_Uebertragung" 1022 "Init_nichtverbaut" 1023 "Fehler" ;
VAL_ 2463978666 MO_Uebersetzung_EM_sek 0 "keine_sichere_Uebertragung" 1022 "Init" 1023 "Fehler" ;
VAL_ 2463978666 MO_Verbrauch_EM_Ges_Ueberlauf 0 "kein_Ueberlauf" 1 "Ueberlauf_Verbrauchssignal" ;
VAL_ 2331595982 PTHyDrA_PrctUtilElDrv 2046 "NotAvailable" 2047 "Init" ;
VAL_ 2331595982 PTHyDrA_StAcv 0 "aus_keine_Anzeige" 1 "inaktiv" 2 "aktiv" 3 "Init" ;
VAL_ 2331595982 PTUIPwrm_FacPwrDyn 126 "nicht_vorhanden" 127 "Init" ;
VAL_ 2331595982 PTUIPwrm_PrctBoostAvl 1022 "nicht_vorhanden" 1023 "InitWert" ;
VAL_ 2331595982 PTUIPwrm_PrctPeakPwrAvl 2046 "nicht_vorhanden" 2047 "Init" ;
VAL_ 2331595982 PTUIPwrm_PrctPwrElBoostCur 1022 "nicht_vorhanden" 1023 "InitWert" ;
VAL_ 2331595982 PTUIPwrm_PrctPwrElBoostMaxUse 1022 "nicht_vorhanden" 1023 "InitWert" ;
VAL_ 2331595982 PTUIPwrm_PrctPwrElDrvCur 4094 "nicht vorhanden" 4095 "Init" ;
VAL_ 2331595982 PTUIPwrm_PrctPwrGnrMaxUse 2046 "nicht_vorhanden" 2047 "Init" ;
VAL_ 2331595982 PTUIPwrm_PrctPwrMotElMaxUse 2046 "nicht vorhanden" 2047 "Init" ;
VAL_ 2331595982 PTUIPwrm_PrctPwrMotMaxUse 2046 "nicht_vorhanden" 2047 "Init" ;
VAL_ 2331595982 PTUIPwrm_PrctPwrSysCur 4094 "nicht_vorhanden" 4095 "Init" ;
VAL_ 2331595982 PTUIPwrm_PwrElBoostNom 1022 "nicht_vorhanden" 1023 "Init" ;
VAL_ 2331595982 PTUIPwrm_StAcv 0 "aus_keine_Anzeige" 1 "inaktiv" 2 "aktiv" 3 "Init" ;
VAL_ 2589283946 PTUIPwrm_PwrGnrNom 2046 "nicht_vorhanden" 2047 "Init" ;
VAL_ 2589283946 PTUIPwrm_PwrMotElNom 2046 "nicht_vorhanden" 2047 "Init" ;
VAL_ 2589283946 PTUIPwrm_PwrSysMotNomDisp 2046 "nicht_vorhanden" 2047 "Init" ;
VAL_ 1155 MO_Powermeter_Charge_Grenze 1022 "Init" 1023 "Fehler" ;
VAL_ 1155 Mo_Powermeter_Grenze 4093 "OFF" ;
VAL_ 1155 MO_Powermeter_Grenze_strategisch 4094 "Init" 4095 "Fehler" ;
VAL_ 1155 MO_Powermeter_Inszenierung_aktiv 0 "keine_Anzeige" 1 "Inszenierung_aktiv" ;
VAL_ 1155 MO_Powermeter_obere_E_Grenze 4094 "Init" 4095 "Fehler" ;
VAL_ 1155 MO_Powermeter_untere_E_Grenze 4094 "Init" 4095 "Fehler" ;
VAL_ 1156 ND_GDOP 1022 "Init" 1023 "Fehler" ;
VAL_ 1156 ND_HDOP 1022 "Init" 1023 "Fehler" ;
VAL_ 1156 ND_Heading 4094 "Init" 4095 "Fehler" ;
VAL_ 1156 ND_Init 0 "nicht_Initialisiert" 1 "Initialisiert" ;
VAL_ 1156 ND_PDOP 1022 "Init" 1023 "Fehler" ;
VAL_ 1156 ND_TDOP 1022 "Init" 1023 "Fehler" ;
VAL_ 1156 ND_VDOP 1022 "Init" 1023 "Fehler" ;
VAL_ 1157 ND_SatInUse 30 "Init" 31 "Fehler" ;
VAL_ 1157 ND_SatInView 30 "Init" 31 "Fehler" ;
VAL_ 1157 NP_Altitude 4094 "Init" 4095 "Fehler" ;
VAL_ 1157 POS_Guete_horizontal 124 "von_248m_bis_400m" 125 "mehr_als_400m" 126 "Init" 127 "Fehler" ;
VAL_ 1157 POS_Guete_horizontal_verfuegbar 0 "nicht_verfuegbar" 1 "verfuegbar" ;
VAL_ 2527679512 ND_Fuelstation_detected 0 "nicht_verbaut" 1 "Tankstelle_nicht_erkannt" 2 "Tankstelle_erkannt" 3 "Init" ;
VAL_ 2527679512 ND_RecDelay 4094 "Init" 4095 "Fehler" ;
VAL_ 2527679512 ND_RouteType 0 "keine_Zielfuehrung_oder_MPR_aktiv" 1 "MPR_aktiv" 2 "Zielfuehrung_aktiv" 3 "reserviert" ;
VAL_ 2527679512 ND_SendDelay 4094 "Init" 4095 "Fehler" ;
VAL_ 2527679512 ND_TimeOffset 0 "Ziel_in_gleicher_Zeitzone" 1 "Ziel_in_Zeitzone_plus_1" 2 "Ziel_in_Zeitzone_minus_1" 3 "Zielzeitzone_groesser_plus_minus_1" ;
VAL_ 2527679512 ND_TimeToDestination 510 "Fehler" 511 "Init" ;
VAL_ 2527679512 ND_Timezone_Offset 14 "Init" 15 "Fehler" ;
VAL_ 2527679512 ND_Timezone_SignBit 0 "PLUS_Vorzeichen" 1 "MINUS_Vorzeichen" ;
VAL_ 2527679512 ND_Timezone_Validity 0 "invalid" 1 "valid" ;
VAL_ 2527679512 ND_Velocity 1022 "Init" 1023 "Fehler" ;
VAL_ 2527679665 ND_Avrg_Speed_RangeData 254 "Init" 255 "Fehler" ;
VAL_ 2527679665 ND_PSD_Street_Category 0 "Rest_Feldweg_Schotterweg_Privatw" 1 "Ortsstrasse" 2 "Kreisstrasse" 3 "Landstrasse" 4 "Bundesstrasse" 5 "Autobahn" 6 "nicht_belegt" 7 "Init" ;
VAL_ 1158 NP_Fix 0 "Init" 1 "No_Fix" 2 "2D_Fix" 3 "3D_Fix" ;
VAL_ 1158 NP_LatDegree 134217726 "Init" 134217727 "Fehler" ;
VAL_ 1158 NP_LatDirection 0 "Nord" 1 "Sued" ;
VAL_ 1158 NP_LongDegree 268435454 "Init" 268435455 "Fehler" ;
VAL_ 1158 NP_LongDirection 0 "Ost" 1 "West" ;
VAL_ 1158 NP_Sat 30 "Init" 31 "Fehler" ;
VAL_ 2589283496 POS_Heading_Trust 0 "Init" 1 "TrustLevel01" 2 "TrustLevel02" 3 "Fehler" ;
VAL_ 2589283496 POS_LatDegree 134217726 "Init" 134217727 "Fehler" ;
VAL_ 2589283496 POS_LatDirection 0 "North" 1 "South" ;
VAL_ 2589283496 POS_LongDegree 268435454 "Init" 268435455 "Fehler" ;
VAL_ 2589283496 POS_LongDirection 0 "East" 1 "West" ;
VAL_ 2589283496 POS_MUX 0 "MUX_0" 1 "MUX_1" 2 "reserved" 3 "Init" ;
VAL_ 2589283496 POS_ODD_EVEN 0 "ODD" 1 "EVEN" ;
VAL_ 2589283496 POS_PosStati 0 "Init" 1 "NoNavAvailable" 2 "NoMapAvailable" 3 "NavBooting" 4 "NavError" 5 "NavCalibrating" 6 "NavNoGpsResyncSince1h" 7 "NavOffroadParkgarageRampOffset2" 8 "DeadReckoningWithoutGps" 9 "DeadReckoningWithGps" 10 "MapMatchedLowConfidence" 11 "MapMatchedLimitedConfidence" 12 "OffroadHighConfidence" 13 "MapMatchedHighConfidence" 14 "PosInSyncWithGpsAndMAP" ;
VAL_ 2527679647 MDK_Anf_Start_Auth 0 "nicht_angefordert" 1 "angefordert" ;
VAL_ 2527679647 MDK_BTLE_Spielschutz_aktivieren 0 "Init_kein_BTLE_Spielschutz" 1 "BTLE_Spielschutz_aktiv" ;
VAL_ 2527679647 MDK_NFC_Spielschutz_aktivieren 0 "Init_kein_NFC_Spielschutz" 1 "NFC_Spielschutz_aktiv" ;
VAL_ 2527679647 NFC_ESM_aktivieren 0 "Init_kein_ESM" 1 "ESM_aktivieren" ;
VAL_ 2527679647 NFC_Laden_unterbrechen 0 "Laden_nicht_unterbrechen" 1 "Laden_unterbrechen" ;
VAL_ 2527679647 Stellgliedtest_NFC 0 "Init_kein_Stellgliedtest" 1 "Stellgliedtest_angefordert" ;
VAL_ 2527679645 NFC_MiKo_ESM_aktiv 0 "Init_kein_ESM" 1 "ESM_aktiv" ;
VAL_ 2527679645 NFC_MiKo_Fehler 0 "SG_iO" 1 "SG_defekt" 2 "Antenne_defekt" 4 "Unterspannung" 8 "Ueberspannung" 16 "Ueberhitzung" ;
VAL_ 2527679645 NFC_MiKo_Laden_unterbrechen 0 "Init_keine_Unterbrechung" 1 "Laden_unterbrechen" ;
VAL_ 2527679645 NFC_MiKo_NFC_Device_gekoppelt 0 "Init_kein_NFC_Device_gekoppelt" 1 "NFC_Device_gekoppelt" ;
VAL_ 2527679645 NFC_MiKo_NFC_Device_Status 0 "Init_nicht_erkannt" 1 "NFC_Device_erkannt" 2 "MDK_Framework_erkannt" 3 "MDK_Applet_erkannt" 4 "MDK_Servicekarte_erkannt" 5 "MDK_Device_authentifiziert" ;
VAL_ 2600468745 NM_DispKBI_FS_CAB_V15 0 "Init" 1 "CAB_01_Antrieb" 2 "CAB_02_Hybrid_Laden" 4 "CAB_03_Fahrwerk" 8 "CAB_04_Fahrerassistenz" 16 "CAB_05_Komfort" 32 "CAB_06_Anzeige" 64 "CAB_07_Connect" 128 "CAB_08_MIB" 256 "CAB_09_Standheizung" 512 "CAB_10_MDK" 1024 "CAB_11_VLAN_Fahrerassistenz" 4096 "CAB_13_VLAN_Connect" 8192 "CAB_14_VLAN_Infotainment" 16384 "CAB_15_Laden" 32768 "CAB_16_Licht" 65536 "CAB_17_RTM" ;
VAL_ 2600468745 NM_DispKBI_FS_CarWakeup 0 "Inaktiv" 1 "Car_Wakeup" ;
VAL_ 2600468745 NM_DispKBI_FS_CBV_AWB 0 "Passiver_WakeUp" 1 "Aktiver_WakeUp" ;
VAL_ 2600468745 NM_DispKBI_FS_CBV_CRI 0 "NM_ohne_Clusteranforderungen" 1 "NM_mit_Clusteranforderungen" ;
VAL_ 2600468745 NM_DispKBI_FS_NM_aktiv_Diagnose 0 "Init" 1 "Diagnose_aktiv" ;
VAL_ 2600468745 NM_DispKBI_FS_NM_aktiv_KL15 0 "Inaktiv" 1 "KL15_EIN" ;
VAL_ 2600468745 NM_DispKBI_FS_NM_aktiv_Tmin 0 "Inaktiv" 1 "Mindestaktivzeit" ;
VAL_ 2600468745 NM_DispKBI_FS_NM_State 0 "Init" 1 "NM_RM_aus_BSM" 2 "NM_RM_aus_PBSM" 4 "NM_NO_aus_RM" 8 "NM_NO_aus_RS" 16 "reserved" 32 "reserved" ;
VAL_ 2600468745 NM_DispKBI_FS_UDS_CC 0 "Inaktiv" 1 "CC_aktiv" ;
VAL_ 2600468496 NM_Gateway_CAB_V15 0 "Init" 1 "CAB_01_Antrieb" 2 "CAB_02_Hybrid_Laden" 4 "CAB_03_Fahrwerk" 8 "CAB_04_Fahrerassistenz" 16 "CAB_05_Komfort" 32 "CAB_06_Anzeige" 64 "CAB_07_Connect" 128 "CAB_08_MIB" 256 "CAB_09_Standheizung" 512 "CAB_10_MDK" 1024 "CAB_11_VLAN_Fahrerassistenz" 4096 "CAB_13_VLAN_Connect" 8192 "CAB_14_VLAN_Infotainment" 16384 "CAB_15_Laden" 32768 "CAB_16_Licht" 65536 "CAB_17_RTM" ;
VAL_ 2600468496 NM_Gateway_Car_Wakeup 0 "Inaktiv" 1 "Car_Wakeup" ;
VAL_ 2600468496 NM_Gateway_CBV_AWB 0 "Passiver_WakeUp" 1 "Aktiver_WakeUp" ;
VAL_ 2600468496 NM_Gateway_CBV_CRI 0 "NM_ohne_Clusteranforderungen" 1 "NM_mit_Clusteranforderungen" ;
VAL_ 2600468496 NM_Gateway_NM_aktiv_CAB 0 "Inaktiv" 1 "CAB_aktiv" ;
VAL_ 2600468496 NM_Gateway_NM_aktiv_Diagnose 0 "Init" 1 "Diagnose_aktiv" ;
VAL_ 2600468496 NM_Gateway_NM_aktiv_Energie 0 "Inaktiv" 1 "Energie_aktiv" ;
VAL_ 2600468496 NM_Gateway_NM_aktiv_FoD 0 "Inaktiv" 1 "FoD_aktiv" ;
VAL_ 2600468496 NM_Gateway_NM_aktiv_IAA_PSO 0 "Inaktiv" 1 "Personalisierung_aktiv" ;
VAL_ 2600468496 NM_Gateway_NM_aktiv_Kessy 0 "Inaktiv" 1 "Kessy_aktiv" ;
VAL_ 2600468496 NM_Gateway_NM_aktiv_KL15 0 "Inaktiv" 1 "KL15_EIN" ;
VAL_ 2600468496 NM_Gateway_NM_aktiv_KS 0 "Inaktiv" 1 "KS_aktiv" ;
VAL_ 2600468496 NM_Gateway_NM_aktiv_Licht 0 "Inaktiv" 1 "Licht_aktiv" ;
VAL_ 2600468496 NM_Gateway_NM_aktiv_PaCo 0 "Inaktiv" 1 "PaCo_aktiv" ;
VAL_ 2600468496 NM_Gateway_NM_aktiv_RTM 0 "Inaktiv" 1 "RTM_aktiv" ;
VAL_ 2600468496 NM_Gateway_NM_aktiv_Standklima 0 "Inaktiv" 1 "STK_aktiv" ;
VAL_ 2600468496 NM_Gateway_NM_aktiv_Tmin 0 "Inaktiv" 1 "Mindestaktivzeit" ;
VAL_ 2600468496 NM_Gateway_NM_aktiv_USS 0 "Inaktiv" 1 "USS_aktiv" ;
VAL_ 2600468496 NM_Gateway_NM_aktiv_ZM 0 "Inaktiv" 1 "ZM_aktiv" ;
VAL_ 2600468496 NM_Gateway_NM_aktiv_ZV 0 "Inaktiv" 1 "ZV_aktiv" ;
VAL_ 2600468496 NM_Gateway_NM_State 0 "Init" 1 "NM_RM_aus_BSM" 2 "NM_RM_aus_PBSM" 4 "NM_NO_aus_RM" 8 "NM_NO_aus_RS" 16 "reserved" 32 "reserved" ;
VAL_ 2600468496 NM_Gateway_UDS_CC 0 "Inaktiv" 1 "CC_aktiv" ;
VAL_ 2600468507 NM_HUD_CAB_V15 0 "Init" 1 "CAB_01_Antrieb" 2 "CAB_02_Hybrid_Laden" 4 "CAB_03_Fahrwerk" 8 "CAB_04_Fahrerassistenz" 16 "CAB_05_Komfort" 32 "CAB_06_Anzeige" 64 "CAB_07_Connect" 128 "CAB_08_MIB" 256 "CAB_09_Standheizung" 512 "CAB_10_MDK" 1024 "CAB_11_VLAN_Fahrerassistenz" 4096 "CAB_13_VLAN_Connect" 8192 "CAB_14_VLAN_Infotainment" 16384 "CAB_15_Laden" 32768 "CAB_16_Licht" 65536 "CAB_17_RTM" ;
VAL_ 2600468507 NM_HUD_Car_WakeUp 0 "Inaktiv" 1 "Car_Wakeup" ;
VAL_ 2600468507 NM_HUD_CBV_AWB 0 "Passiver_WakeUp" 1 "Aktiver_WakeUp" ;
VAL_ 2600468507 NM_HUD_CBV_CRI 0 "NM_ohne_Clusteranforderungen" 1 "NM_mit_Clusteranforderungen" ;
VAL_ 2600468507 NM_HUD_NM_aktiv_Diagnose 0 "Init" 1 "Diagnose_aktiv" ;
VAL_ 2600468507 NM_HUD_NM_aktiv_KL15 0 "Inaktiv" 1 "KL15_EIN" ;
VAL_ 2600468507 NM_HUD_NM_aktiv_Tmin 0 "Inaktiv" 1 "Mindestaktivzeit" ;
VAL_ 2600468507 NM_HUD_NM_State 0 "Init" 1 "NM_RM_aus_BSM" 2 "NM_RM_aus_PBSM" 4 "NM_NO_aus_RM" 8 "NM_NO_aus_RS" 16 "reserved" 32 "reserved" ;
VAL_ 2600468507 NM_HUD_UDS_CC 0 "Inaktiv" 1 "CC_aktiv" ;
VAL_ 2600468595 NM_Info_El_CAB_V15 0 "Init" 1 "CAB_01_Antrieb" 2 "CAB_02_Hybrid_Laden" 4 "CAB_03_Fahrwerk" 8 "CAB_04_Fahrerassistenz" 16 "CAB_05_Komfort" 32 "CAB_06_Anzeige" 64 "CAB_07_Connect" 128 "CAB_08_MIB" 256 "CAB_09_Standheizung" 512 "CAB_10_MDK" 1024 "CAB_11_VLAN_Fahrerassistenz" 4096 "CAB_13_VLAN_Connect" 8192 "CAB_14_VLAN_Infotainment" 16384 "CAB_15_Laden" 32768 "CAB_16_Licht" 65536 "CAB_17_RTM" ;
VAL_ 2600468595 NM_Info_El_Car_Wakeup 0 "Inaktiv" 1 "Car_Wakeup" ;
VAL_ 2600468595 NM_Info_El_CBV_AWB 0 "Passiver_WakeUp" 1 "Aktiver_WakeUp" ;
VAL_ 2600468595 NM_Info_El_CBV_CRI 0 "NM_ohne_Clusteranforderungen" 1 "NM_mit_Clusteranforderungen" ;
VAL_ 2600468595 NM_Info_El_NM_aktiv_Applikation 0 "nicht_aktiv" 1 "Applikationsanforderung_aktiv" ;
VAL_ 2600468595 NM_Info_El_NM_aktiv_BAP_Comm 0 "Init" 1 "BAP_Sound_aktiv" ;
VAL_ 2600468595 NM_Info_El_NM_aktiv_Diagnose 0 "Init" 1 "Diagnose_aktiv" ;
VAL_ 2600468595 NM_Info_El_NM_aktiv_IAA 0 "Init" 1 "IAA_aktiv" ;
VAL_ 2600468595 NM_Info_El_NM_aktiv_KL15 0 "Inaktiv" 1 "KL15_EIN" ;
VAL_ 2600468595 NM_Info_El_NM_aktiv_MIBCAN 0 "Init" 1 "MIB_CAN_aktiv" ;
VAL_ 2600468595 NM_Info_El_NM_aktiv_Powerstate 0 "nicht_aktiv" 1 "Powerstate_aktiv" ;
VAL_ 2600468595 NM_Info_El_NM_aktiv_SmartLight 0 "Init" 1 "SmartLight_aktiv" ;
VAL_ 2600468595 NM_Info_El_NM_aktiv_Tmin 0 "Inaktiv" 1 "Mindestaktivzeit" ;
VAL_ 2600468595 NM_Info_El_NM_State 0 "Init" 1 "NM_RM_aus_BSM" 2 "NM_RM_aus_PBSM" 4 "NM_NO_aus_RM" 8 "NM_NO_aus_RS" 16 "reserved" 32 "reserved" ;
VAL_ 2600468595 NM_Info_El_UDS_CC 0 "Inaktiv" 1 "CC_aktiv" ;
VAL_ 2600468500 NM_Kombi_CAB_V15 0 "Init" 1 "CAB_01_Antrieb" 2 "CAB_02_Hybrid_Laden" 4 "CAB_03_Fahrwerk" 8 "CAB_04_Fahrerassistenz" 16 "CAB_05_Komfort" 32 "CAB_06_Anzeige" 64 "CAB_07_Connect" 128 "CAB_08_MIB" 256 "CAB_09_Standheizung" 512 "CAB_10_MDK" 1024 "CAB_11_VLAN_Fahrerassistenz" 4096 "CAB_13_VLAN_Connect" 8192 "CAB_14_VLAN_Infotainment" 16384 "CAB_15_Laden" 32768 "CAB_16_Licht" 65536 "CAB_17_RTM" ;
VAL_ 2600468500 NM_Kombi_Car_Wakeup 0 "Inaktiv" 1 "Car_Wakeup" ;
VAL_ 2600468500 NM_Kombi_CBV_AWB 0 "Passiver_WakeUp" 1 "Aktiver_WakeUp" ;
VAL_ 2600468500 NM_Kombi_CBV_CRI 0 "Standard_Layout" 1 "TNB_Layout" ;
VAL_ 2600468500 NM_Kombi_NM_aktiv_Buzzer 1 "Buzzer_aktiv" ;
VAL_ 2600468500 NM_Kombi_NM_aktiv_Diagnose 0 "Init" 1 "Diagnose_aktiv" ;
VAL_ 2600468500 NM_Kombi_NM_aktiv_KL15 0 "Inaktiv" 1 "KL15_EIN" ;
VAL_ 2600468500 NM_Kombi_NM_aktiv_Schluesselkomm 1 "Schluesselkomm_aktiv" ;
VAL_ 2600468500 NM_Kombi_NM_aktiv_Tmin 0 "Inaktiv" 1 "Mindestaktivzeit" ;
VAL_ 2600468500 NM_Kombi_NM_aktiv_VLW 0 "Init" 1 "VLW_aktiv" ;
VAL_ 2600468500 NM_Kombi_NM_State 0 "Init" 1 "NM_RM_aus_BSM" 2 "NM_RM_aus_PBSM" 4 "NM_NO_aus_RM" 8 "NM_NO_aus_RS" 16 "reserved" 32 "reserved" ;
VAL_ 2600468500 NM_Kombi_UDS_CC 0 "Init" 1 "CC_aktiv" ;
VAL_ 2600468748 NM_SmLi_01_CAB_V15 0 "Init" 1 "CAB_01_Antrieb" 2 "CAB_02_Hybrid_Laden" 4 "CAB_03_Fahrwerk" 8 "CAB_04_Fahrerassistenz" 16 "CAB_05_Komfort" 32 "CAB_06_Anzeige" 64 "CAB_07_Connect" 128 "CAB_08_MIB" 256 "CAB_09_Standheizung" 512 "CAB_10_MDK" 1024 "CAB_11_VLAN_Fahrerassistenz" 4096 "CAB_13_VLAN_Connect" 8192 "CAB_14_VLAN_Infotainment" 16384 "CAB_15_Laden" 32768 "CAB_16_Licht" 65536 "CAB_17_RTM" ;
VAL_ 2600468748 NM_SmLi_01_CarWakeup 0 "Inaktiv" 1 "Car_Wakeup" ;
VAL_ 2600468748 NM_SmLi_01_CBV_AWB 0 "Passiver_WakeUp" 1 "Aktiver_WakeUp" ;
VAL_ 2600468748 NM_SmLi_01_CBV_CRI 0 "Standard_Layout" 1 "TNB_Layout" ;
VAL_ 2600468748 NM_SmLi_01_NM_aktiv_Diagnose 0 "Init" 1 "Diagnose_aktiv" ;
VAL_ 2600468748 NM_SmLi_01_NM_aktiv_KL15 0 "Inaktiv" 1 "KL15_EIN" ;
VAL_ 2600468748 NM_SmLi_01_NM_aktiv_Tmin 0 "Inaktiv" 1 "Mindestaktivzeit" ;
VAL_ 2600468748 NM_SmLi_01_NM_State 0 "Init" 1 "NM_RM_aus_BSM" 2 "NM_RM_aus_PBSM" 4 "NM_NO_aus_RM" 8 "NM_NO_aus_RS" 16 "reserved" 32 "reserved" ;
VAL_ 2600468748 NM_SmLi_01_UDS_CC 0 "Init" 1 "CC_aktiv" ;
VAL_ 2589283656 ORU_EM_Anfrage_freigegebeneNetze 0 "only_12V" 1 "networks_48V_and_12V" 2 "networks_HV_and_12V" 3 "networks_HV_and_48V_and_12V" ;
VAL_ 2589283656 ORU_Inventory 0 "Init" 1 "Inventory_Erstellung_nicht_aktiv" 2 "Inventory_Erstellung_aktiv" ;
VAL_ 2589283656 ORU_Status 0 "IDLE" 1 "PENDING" 2 "PREPARATION" 3 "PREPARATION_HV" 4 "RUNNING" 5 "RUNNING_HV" 6 "PENDING_NOTREADY" 7 "FAILURE_POWERTRAIN_DISABLED" ;
VAL_ 2589283656 ORU_Warnung 0 "keine_Anzeige" 1 "Update_unvollstaendig_Prio1" 2 "Update_fehlgeschlagen_Prio1" 3 "reserviert" ;
VAL_ 2589284073 ORUG1_Anforderung_HMS 0 "keine_Anforderung" 1 "halten" 2 "parken" 3 "halten_Standby" 4 "anfahren" 5 "Loesen_ueber_Rampe" 6 "Parken_mit_P" 7 "HMS_uebernehmen" ;
VAL_ 2589284073 ORUG1_HVLock 0 "Idle" 1 "ActivateLock" 2 "ReleaseLock" ;
VAL_ 2589284073 ORUG1_HVReleased 0 "HVECUNotReleased" 1 "HVECUReleased" ;
VAL_ 2589284073 ORUG1_Parken_beibehalten_HMS 0 "Parken_nicht_beibehalten" 1 "Parken_beibehalten" 2 "Init" 3 "Fehler" ;
VAL_ 2589284073 ORUG1_Warning 0 "Idle" 1 "Yellow" 2 "Red" 3 "Suppress" ;
VAL_ 2589284074 ORUG2_GuardInfo 0 "Idle" 1 "VehicleLockActive" 2 "HMSLocked" 4 "KLSLocked" 8 "PWRaLocked" 16 "PWRcLocked" 32 "HVLockActive" 64 "BCMeLocked" 128 "OCCLocked" 256 "DCDCLocked" 512 "WarningsSuppressed" 1024 "CrashDetected" 2048 "Buffer1Blocked" 4096 "Buffer2Blocked" 8192 "Buffer3Blocked" 16384 "reserved" ;
VAL_ 2589284074 ORUG2_GuardState 0 "Idle" 1 "DataErr" 2 "CountErr" 3 "Collecting" 4 "HwVerErr" 5 "Waiting" 6 "Ready" ;
VAL_ 2589284074 ORUG2_TorqueLock 0 "Idle" 1 "ActivateLock" 2 "ReleaseLock" ;
